VERSION ""

NS_ :

BS_:

BU_: ZCUR HDBI HDBM CID ZCUF ZCUT HDBT HDBA ZCUL

BO_ 656 ZCUR_VB1_2: 32 ZCUR
 SG_ ZCUR_FHVACBypassMotor_Err : 114|2@1+ (1,0) [0|3] ""  HDBM
 SG_ ZCUR_FHVACDefrostMotor_Err : 122|2@1+ (1,0) [0|3] ""  HDBM
 SG_ ZCUR_FHVACBLW_Err : 119|1@1+ (1,0) [0|1] ""  HDBM
 SG_ ZCUR_FHVACModePos_Rsp : 0|10@1+ (1,0) [0|1000] ""  HDBM
 SG_ ZCUR_FHVACCyclePos_Rsp : 10|10@1+ (1,0) [0|1000] ""  HDBM
 SG_ ZCUR_FHVACBypassPos_Rsp : 20|10@1+ (1,0) [0|1000] ""  HDBM
 SG_ ZCUR_FHVACDefrostPos_Rsp : 30|10@1+ (1,0) [0|1000] ""  HDBM
 SG_ ZCUR_FHVACBLWPWM_Rsp : 40|10@1+ (1,0) [0|1000] "千分比"  HDBM
 SG_ ZCUR_FHVACBLWRelay_St : 126|1@1+ (1,0) [0|1] ""  HDBM
 SG_ ZCUR_FHVACLeftMixPos_Rsp : 50|10@1+ (1,0) [0|1000] ""  HDBM
 SG_ ZCUR_FHVACRigtMixPos_Rsp : 60|10@1+ (1,0) [0|1000] ""  HDBM
 SG_ ZCUR_FHVACLeftMixMotor_Err : 120|2@1+ (1,0) [0|3] ""  HDBM
 SG_ ZCUR_FHVACModeMotor_Err : 112|2@1+ (1,0) [0|3] ""  HDBM
 SG_ ZCUR_FHVACCycleMotor_Err : 124|2@1+ (1,0) [0|3] ""  HDBM
 SG_ ZCUR_FHVACBLWRelay_Err : 118|1@1+ (1,0) [0|1] ""  HDBM
 SG_ ZCUR_FHVACRigtMixMotor_Err : 116|2@1+ (1,0) [0|3] ""  HDBM

BO_ 657 ZCUR_VB1_3: 32 ZCUR
 SG_ ZCUR_TDuctRVValid_St : 144|1@1+ (1,0) [0|1] ""  HDBM
 SG_ ZCUR_TDuctLFValid_St : 145|1@1+ (1,0) [0|1] ""  HDBM
 SG_ ZCUR_TDuctRFValid_St : 146|1@1+ (1,0) [0|1] ""  HDBM
 SG_ ZCUR_ADSTws_Val : 32|12@1+ (0.1,-40) [-40|80] "℃"  HDBM
 SG_ ZCUR_ION_St : 162|2@1+ (1,0) [0|3] ""  HDBM
 SG_ ZCUR_ADSTrh_Val : 44|12@1+ (0.1,-40) [-40|80] "℃"  HDBM
 SG_ ZCUR_ADShumidity_Val : 56|12@1+ (0.1,0) [0|100] "%"  HDBM
 SG_ ZCUR_TcabOrig_Val : 68|12@1+ (0.1,-40) [-40|80] "℃"  HDBM
 SG_ ZCUR_TEvapOrig_Val : 80|12@1+ (0.1,-40) [-40|80] "℃"  HDBM
 SG_ ZCUR_TDuctLV_Val : 92|12@1+ (0.1,-40) [-40|80] "℃"  HDBM
 SG_ ZCUR_TDuctRV_Val : 104|12@1+ (0.1,-40) [-40|80] "℃"  HDBM
 SG_ ZCUR_TDuctLF_Val : 116|12@1+ (0.1,-40) [-40|80] "℃"  HDBM
 SG_ ZCUR_TDuctRF_Val : 128|12@1+ (0.1,-40) [-40|80] "℃"  HDBM
 SG_ ZCUR_ADS_Valid_St : 147|1@1+ (1,0) [0|1] ""  HDBM
 SG_ ZCUR_TcabOrigValid_St : 148|1@1+ (1,0) [0|1] ""  HDBM
 SG_ ZCUR_TEvapOrigValid_St : 149|1@1+ (1,0) [0|1] ""  HDBM
 SG_ ZCUR_TDuctLVValid_St : 150|1@1+ (1,0) [0|1] ""  HDBM
 SG_ ZCUR_ION_Err : 151|1@1+ (1,0) [0|1] ""  HDBM
 SG_ ZCUR_PM25Sensor_Err : 143|1@1+ (1,0) [0|1] ""  HDBM
 SG_ ZCUR_CmpmtInAirPmDnsty_Val : 152|10@1+ (1,0) [0|1023] ""  HDBM
 SG_ ZCUR_CmpmtInAirPmAQI_St : 140|3@1+ (1,0) [0|7] ""  HDBM

BO_ 912 ZCUR_VB1_4: 32 ZCUR
 SG_ ZCUR_RRHdl_Err : 40|3@1+ (1,0) [0|7] ""  HDBM
 SG_ ZCUR_FRHdlWork_St : 32|2@1+ (1,0) [0|3] ""  HDBM
 SG_ ZCUR_RRHdlWork_St : 34|2@1+ (1,0) [0|3] ""  HDBM
 SG_ ZCUR_FRHdl_Err : 36|3@1+ (1,0) [0|7] ""  HDBM
 SG_ ZCUR_FRSeatHt_Rsp : 0|5@1+ (5,0) [0|100] "%"  HDBM
 SG_ ZCUR_FRSeatHtStpRsn_St : 24|4@1+ (1,0) [0|15] ""  HDBM
 SG_ ZCUR_FRSeatVtlt_Rsp : 8|5@1+ (5,0) [0|100] "%"  HDBM
 SG_ ZCUR_FRSeatVtltStpRsn_St : 28|4@1+ (1,0) [0|15] ""  HDBM
 SG_ ZCUR_RExMirHt_Rsp : 16|5@1+ (5,0) [0|100] "%"  HDBM
 SG_ ZCUR_RExMirHtStpRsn_St : 43|4@1+ (1,0) [0|15] ""  HDBM

BO_ 1472 ZCUR_VB1_5: 32 ZCUR
 SG_ ZCUR_HSDLVPower_Err : 24|48@1+ (1,0) [0|0] ""  HDBM
 SG_ ZCUR_HSDLVPower_St : 72|48@1+ (1,0) [0|0] ""  HDBM
 SG_ ZCUR_PERMLVPower_Err : 120|16@1+ (1,0) [0|65535] ""  HDBM
 SG_ ZCUR_PERMLVPower_St : 136|16@1+ (1,0) [0|65535] ""  HDBM
 SG_ ZCUR_FRSeatHgtAdjLn_St : 202|1@1+ (1,0) [0|1] ""  HDBM
 SG_ ZCUR_FRSeatCshnAngAdjLn_St : 203|1@1+ (1,0) [0|1] ""  HDBM
 SG_ ZCUR_FRLegAngCshnExtLn_St : 204|1@1+ (1,0) [0|1] ""  HDBM
 SG_ ZCUR_FRWinStpRsn_St : 208|4@1+ (1,0) [0|15] ""  HDBM
 SG_ ZCUR_RRWinStpRsn_St : 212|4@1+ (1,0) [0|15] ""  HDBM
 SG_ ZCUR_FRWinStp_Req : 216|3@1+ (1,0) [0|7] ""  HDBM
 SG_ ZCUR_RRWinStp_Req : 219|3@1+ (1,0) [0|7] ""  HDBM
 SG_ ZCUR_FRHdlFrzLn_Val : 168|8@1+ (1,0) [0|255] ""  HDBM
 SG_ ZCUR_RRHdlFrzLn_Val : 176|8@1+ (1,0) [0|255] ""  HDBM
 SG_ ZCUR_FRHdlFrzLnTime_Val : 184|8@1+ (0.1,0) [0|25.5] ""  HDBM
 SG_ ZCUR_RRHdlFrzLnTime_Val : 192|8@1+ (0.1,0) [0|25.5] ""  HDBM
 SG_ ZCUR_FRSeatFBAdjLn_St : 200|1@1+ (1,0) [0|1] ""  HDBM
 SG_ ZCUR_FRSeatBackrestAdjLn_St : 201|1@1+ (1,0) [0|1] ""  HDBM

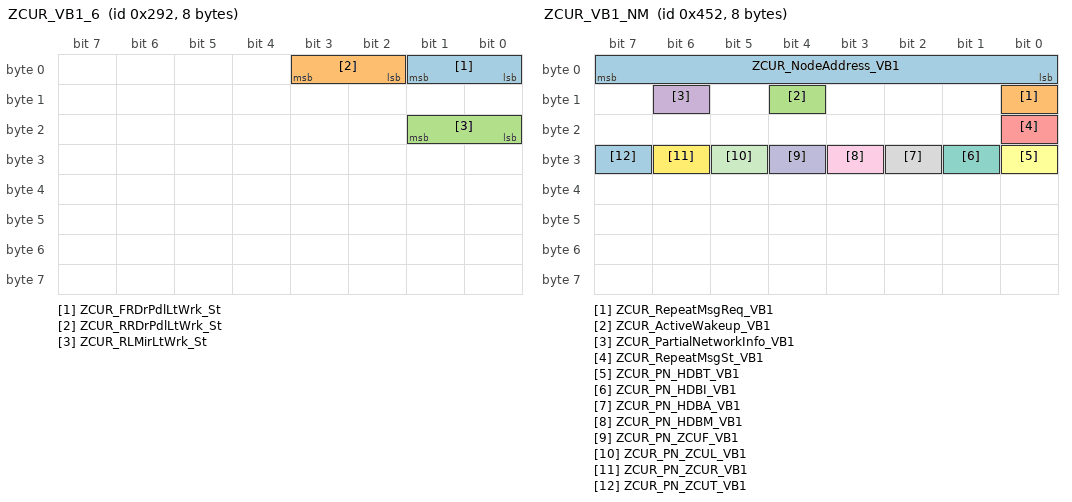
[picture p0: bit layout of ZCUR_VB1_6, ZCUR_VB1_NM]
BO_ 658 ZCUR_VB1_6: 8 ZCUR
 SG_ ZCUR_FRDrPdlLtWrk_St : 0|2@1+ (1,0) [0|3] ""  HDBM
 SG_ ZCUR_RRDrPdlLtWrk_St : 2|2@1+ (1,0) [0|3] ""  HDBM
 SG_ ZCUR_RLMirLtWrk_St : 16|2@1+ (1,0) [0|3] ""  HDBM

BO_ 1106 ZCUR_VB1_NM: 8 ZCUR
 SG_ ZCUR_NodeAddress_VB1 : 0|8@1+ (1,0) [0|255] ""  ZCUT,HDBI,ZCUF,HDBM,ZCUL,HDBA,HDBT,CID
 SG_ ZCUR_RepeatMsgReq_VB1 : 8|1@1+ (1,0) [0|1] ""  ZCUT,HDBI,ZCUF,HDBM,ZCUL,HDBA,HDBT
 SG_ ZCUR_ActiveWakeup_VB1 : 12|1@1+ (1,0) [0|1] ""  ZCUT,HDBI,ZCUF,HDBM,ZCUL,HDBA,HDBT
 SG_ ZCUR_PartialNetworkInfo_VB1 : 14|1@1+ (1,0) [0|1] ""  ZCUT,HDBI,ZCUF,HDBM,ZCUL,HDBA,HDBT
 SG_ ZCUR_RepeatMsgSt_VB1 : 16|1@1+ (1,0) [0|1] ""  ZCUT,HDBI,ZCUF,HDBM,ZCUL,HDBA,HDBT
 SG_ ZCUR_PN_HDBT_VB1 : 24|1@1+ (1,0) [0|1] ""  ZCUT,HDBI,ZCUF,HDBM,ZCUL,HDBA,HDBT
 SG_ ZCUR_PN_HDBI_VB1 : 25|1@1+ (1,0) [0|1] ""  ZCUT,HDBI,ZCUF,HDBM,ZCUL,HDBA,HDBT
 SG_ ZCUR_PN_HDBA_VB1 : 26|1@1+ (1,0) [0|1] ""  ZCUT,HDBI,ZCUF,HDBM,ZCUL,HDBA,HDBT
 SG_ ZCUR_PN_HDBM_VB1 : 27|1@1+ (1,0) [0|1] ""  ZCUT,HDBI,ZCUF,HDBM,ZCUL,HDBA,HDBT
 SG_ ZCUR_PN_ZCUF_VB1 : 28|1@1+ (1,0) [0|1] ""  ZCUT,HDBI,ZCUF,HDBM,ZCUL,HDBA,HDBT
 SG_ ZCUR_PN_ZCUL_VB1 : 29|1@1+ (1,0) [0|1] ""  ZCUT,HDBI,ZCUF,HDBM,ZCUL,HDBA,HDBT
 SG_ ZCUR_PN_ZCUR_VB1 : 30|1@1+ (1,0) [0|1] ""  ZCUT,HDBI,ZCUF,HDBM,ZCUL,HDBA,HDBT
 SG_ ZCUR_PN_ZCUT_VB1 : 31|1@1+ (1,0) [0|1] ""  ZCUT,HDBI,ZCUF,HDBM,ZCUL,HDBA,HDBT

BO_ 1414 ZCUR_NMWakeup: 32 ZCUR
 SG_ ZCUR_WakeupReq_HDBT : 0|1@1+ (1,0) [0|1] ""  HDBM,HDBT
 SG_ ZCUR_WakeupReq_HDBI : 8|8@1+ (1,0) [0|255] ""  HDBI,HDBM
 SG_ ZCUR_WakeupReq_HDBA : 16|8@1+ (1,0) [0|255] ""  HDBM,HDBA
 SG_ ZCUR_WakeupReq_HDBM : 24|8@1+ (1,0) [0|255] ""  HDBM
 SG_ ZCUR_WakeupReq_ZCUF : 32|56@1+ (1,0) [0|0] ""  ZCUF,HDBM
 SG_ ZCUR_WakeupReq_ZCUL : 88|56@1+ (1,0) [0|0] ""  HDBM,ZCUL
 SG_ ZCUR_WakeupReq_ZCUR : 144|56@1+ (1,0) [0|0] ""  HDBM
 SG_ ZCUR_WakeupReq_ZCUT : 200|56@1+ (1,0) [0|0] ""  ZCUT,HDBM

BO_ 1495 ZCUR_VB1_NMIndication: 32 ZCUR
 SG_ ZCUR_VB1_NetworkReqCondition0 : 0|8@1+ (1,0) [0|255] ""  HDBM
 SG_ ZCUR_VB1_NetworkReqCondition1 : 8|8@1+ (1,0) [0|255] ""  HDBM
 SG_ ZCUR_VB1_NetworkReqCondition2 : 16|8@1+ (1,0) [0|255] ""  HDBM
 SG_ ZCUR_VB1_NetworkReqCondition3 : 24|8@1+ (1,0) [0|255] ""  HDBM
 SG_ ZCUR_VB1_NetworkReqCondition4 : 32|8@1+ (1,0) [0|255] ""  HDBM
 SG_ ZCUR_VB1_NetworkReqCondition5 : 40|8@1+ (1,0) [0|255] ""  HDBM
 SG_ ZCUR_VB1_NetworkReqCondition6 : 48|8@1+ (1,0) [0|255] ""  HDBM
 SG_ ZCUR_VB1_NetworkReqCondition7 : 56|8@1+ (1,0) [0|255] ""  HDBM
 SG_ ZCUR_VB1_NetworkReqCondition8 : 64|8@1+ (1,0) [0|255] ""  HDBM
 SG_ ZCUR_VB1_NetworkReqCondition9 : 72|8@1+ (1,0) [0|255] ""  HDBM
 SG_ ZCUR_VB1_NetworkReqCondition10 : 80|8@1+ (1,0) [0|255] ""  HDBM
 SG_ ZCUR_VB1_NetworkReqCondition11 : 88|8@1+ (1,0) [0|255] ""  HDBM
 SG_ ZCUR_VB1_NetworkReqCondition12 : 96|8@1+ (1,0) [0|255] ""  HDBM
 SG_ ZCUR_VB1_NetworkReqCondition13 : 104|8@1+ (1,0) [0|255] ""  HDBM
 SG_ ZCUR_VB1_NetworkReqCondition14 : 112|8@1+ (1,0) [0|255] ""  HDBM
 SG_ ZCUR_VB1_NetworkReqCondition15 : 120|8@1+ (1,0) [0|255] ""  HDBM
 SG_ ZCUR_VB1_NetworkReqCondition16 : 128|8@1+ (1,0) [0|255] ""  HDBM
 SG_ ZCUR_VB1_NetworkReqCondition17 : 136|8@1+ (1,0) [0|255] ""  HDBM
 SG_ ZCUR_VB1_NetworkReqCondition18 : 144|8@1+ (1,0) [0|255] ""  HDBM
 SG_ ZCUR_VB1_NetworkReqCondition19 : 152|8@1+ (1,0) [0|255] ""  HDBM
 SG_ ZCUR_VB1_NetworkReqCondition20 : 160|8@1+ (1,0) [0|255] ""  HDBM
 SG_ ZCUR_VB1_NetworkReqCondition21 : 168|8@1+ (1,0) [0|255] ""  HDBM
 SG_ ZCUR_VB1_NetworkReqCondition22 : 176|8@1+ (1,0) [0|255] ""  HDBM
 SG_ ZCUR_VB1_NetworkReqCondition23 : 184|8@1+ (1,0) [0|255] ""  HDBM
 SG_ ZCUR_VB1_NetworkReqCondition24 : 192|8@1+ (1,0) [0|255] ""  HDBM
 SG_ ZCUR_VB1_NetworkReqCondition25 : 200|8@1+ (1,0) [0|255] ""  HDBM
 SG_ ZCUR_VB1_NetworkReqCondition26 : 208|8@1+ (1,0) [0|255] ""  HDBM
 SG_ ZCUR_VB1_NetworkReqCondition27 : 216|8@1+ (1,0) [0|255] ""  HDBM
 SG_ ZCUR_VB1_NetworkReqCondition28 : 224|8@1+ (1,0) [0|255] ""  HDBM
 SG_ ZCUR_VB1_NetworkReqCondition29 : 232|8@1+ (1,0) [0|255] ""  HDBM
 SG_ ZCUR_VB1_NetworkReqCondition30 : 240|8@1+ (1,0) [0|255] ""  HDBM
 SG_ ZCUR_VB1_NetworkReqCondition31 : 248|8@1+ (1,0) [0|255] ""  HDBM

BO_ 431 ZCUR_VB1_8: 32 ZCUR
 SG_ ZCUR_FRSeatCshnAngPst_Val : 40|7@1+ (1,0) [0|100] ""  HDBM
 SG_ ZCUR_FRLegAngCshnExtPst_Val : 48|7@1+ (1,0) [0|100] ""  HDBM
 SG_ ZCUR_FRSeatFBPst_Val : 16|7@1+ (1,0) [0|100] ""  HDBM
 SG_ ZCUR_FRSeatBackrestPst_Val : 24|7@1+ (1,0) [0|100] ""  HDBM
 SG_ ZCUR_FRSeatHgtPst_Val : 32|7@1+ (1,0) [0|100] ""  HDBM
 SG_ ZCUR_RExMirUDPst_Val : 56|7@1+ (1,0) [0|100] ""  HDBM
 SG_ ZCUR_RExMirLRPst_Val : 64|7@1+ (1,0) [0|100] ""  HDBM

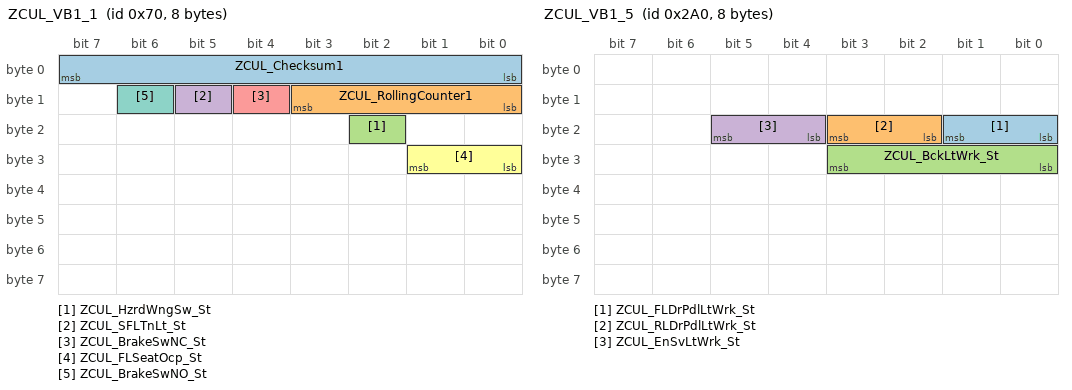
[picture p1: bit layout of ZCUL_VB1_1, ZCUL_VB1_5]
BO_ 112 ZCUL_VB1_1: 8 ZCUL
 SG_ ZCUL_Checksum1 : 0|8@1+ (1,0) [0|255] ""  HDBM,HDBA
 SG_ ZCUL_RollingCounter1 : 8|4@1+ (1,0) [0|15] ""  HDBM,HDBA
 SG_ ZCUL_HzrdWngSw_St : 18|1@1+ (1,0) [0|1] ""  ZCUF,HDBM
 SG_ ZCUL_SFLTnLt_St : 13|1@1+ (1,0) [0|1] ""  HDBM
 SG_ ZCUL_BrakeSwNC_St : 12|1@1+ (1,0) [0|1] ""  HDBM
 SG_ ZCUL_FLSeatOcp_St : 24|2@1+ (1,0) [0|3] ""  ZCUF,HDBM,HDBA
 SG_ ZCUL_BrakeSwNO_St : 14|1@1+ (1,0) [0|1] ""  HDBM

BO_ 400 ZCUL_VB1_2: 32 ZCUL
 SG_ ZCUL_FLSeatHgtAdj_Req : 24|2@1+ (1,0) [0|3] ""  HDBM
 SG_ ZCUL_FLLthPawl_St : 16|1@1+ (1,0) [0|1] ""  HDBM
 SG_ ZCUL_FLSeatCshnAngAdj_Req : 30|2@1+ (1,0) [0|3] ""  HDBM
 SG_ ZCUL_RLLthPawl_St : 36|1@1+ (1,0) [0|1] ""  HDBM
 SG_ ZCUL_FLHdlOprt_St : 17|2@1+ (1,0) [0|3] ""  HDBM
 SG_ ZCUL_RLHdlOprt_St : 19|2@1+ (1,0) [0|3] ""  HDBM
 SG_ ZCUL_FLDrIntSW_St : 12|2@1+ (1,0) [0|3] ""  HDBM
 SG_ ZCUL_RLDrIntSW_St : 32|2@1+ (1,0) [0|3] ""  HDBM
 SG_ ZCUL_FLLthAjar_St : 14|1@1+ (1,0) [0|1] ""  HDBM
 SG_ ZCUL_RLLthAjar_St : 34|1@1+ (1,0) [0|1] ""  HDBM
 SG_ ZCUL_FLSeatAdj_Req : 28|2@1+ (1,0) [0|3] ""  HDBM
 SG_ ZCUL_FLLthHlfLck_St : 15|1@1+ (1,0) [0|1] ""  HDBM
 SG_ ZCUL_FLSeatBackrestAdj_Req : 26|2@1+ (1,0) [0|3] ""  HDBM
 SG_ ZCUL_RLLthHlfLck_St : 35|1@1+ (1,0) [0|1] ""  HDBM
 SG_ ZCUL_Checksum2 : 0|8@1+ (1,0) [0|255] ""  HDBM
 SG_ ZCUL_RollingCounter2 : 8|4@1+ (1,0) [0|15] ""  HDBM
 SG_ ZCUL_FLSeatLegAngCshnExtAdj_Req : 40|2@1+ (1,0) [0|3] ""  HDBM
 SG_ ZCUL_SteerTiltPst_Val : 72|8@1+ (0.5,0) [0|100] ""  HDBM
 SG_ ZCUL_SteerTelePst_Val : 80|8@1+ (0.5,0) [0|100] ""  HDBM
 SG_ ZCUL_FLWinPst_Rsp : 88|8@1+ (1,0) [0|255] ""  HDBM
 SG_ ZCUL_RLWinPst_Rsp : 96|8@1+ (1,0) [0|255] ""  HDBM
 SG_ ZCUL_LExMirUDPst_Val : 104|7@1+ (1,0) [0|100] ""  HDBM
 SG_ ZCUL_LExMirLRPst_Val : 112|7@1+ (1,0) [0|100] ""  HDBM
 SG_ ZCUL_FLSeatFBPst_Val : 120|7@1+ (1,0) [0|100] ""  HDBM
 SG_ ZCUL_FLSeatBackrestPst_Val : 128|7@1+ (1,0) [0|100] ""  HDBM
 SG_ ZCUL_FLSeatHgtPst_Val : 136|7@1+ (1,0) [0|100] ""  HDBM
 SG_ ZCUL_FLSeatCshnAngPst_Val : 144|7@1+ (1,0) [0|100] ""  HDBM
 SG_ ZCUL_FLLegAngCshnExtPst_Val : 152|7@1+ (1,0) [0|100] ""  HDBM

BO_ 896 ZCUL_VB1_3: 32 ZCUL
 SG_ ZCUL_FLHdl_Err : 36|3@1+ (1,0) [0|7] ""  HDBM
 SG_ ZCUL_FLHdlWork_St : 32|2@1+ (1,0) [0|3] ""  HDBM
 SG_ ZCUL_RLHdlWork_St : 34|2@1+ (1,0) [0|3] ""  HDBM
 SG_ ZCUL_RLHdl_Err : 40|3@1+ (1,0) [0|7] ""  HDBM
 SG_ ZCUL_SteerTeleLn_St : 43|1@1+ (1,0) [0|1] ""  HDBM
 SG_ ZCUL_SteerTiltLn_St : 44|1@1+ (1,0) [0|1] ""  HDBM
 SG_ ZCUL_SteerHtStpRsn_St : 48|4@1+ (1,0) [0|15] ""  HDBM
 SG_ ZCUL_SteerHt_Rsp : 0|5@1+ (5,0) [0|100] "%"  HDBM
 SG_ ZCUL_FLSeatHtStpRsn_St : 56|4@1+ (1,0) [0|15] ""  HDBM
 SG_ ZCUL_FLSeatVtlt_Rsp : 24|5@1+ (5,0) [0|100] "%"  HDBM
 SG_ ZCUL_FLSeatVtltStpRsn_St : 60|4@1+ (1,0) [0|15] ""  HDBM
 SG_ ZCUL_LExMirHt_Rsp : 8|5@1+ (5,0) [0|100] "%"  HDBM
 SG_ ZCUL_LExMirHtStpRsn_St : 52|4@1+ (1,0) [0|15] ""  HDBM
 SG_ ZCUL_FLSeatHt_Rsp : 16|5@1+ (5,0) [0|100] "%"  HDBM

BO_ 1408 ZCUL_VB1_4: 32 ZCUL
 SG_ ZCUL_PERMLVPower_Err : 120|16@1+ (1,0) [0|65535] ""  HDBM
 SG_ ZCUL_HSDLVPower_St : 72|48@1+ (1,0) [0|0] ""  HDBM
 SG_ ZCUL_HSDLVPower_Err : 24|48@1+ (1,0) [0|0] ""  HDBM
 SG_ ZCUL_PERMLVPower_St : 136|16@1+ (1,0) [0|65535] ""  HDBM
 SG_ ZCUL_FLHdlFrzLn_Val : 168|8@1+ (1,0) [0|255] ""  HDBM
 SG_ ZCUL_RLHdlFrzLn_Val : 176|8@1+ (1,0) [0|255] ""  HDBM
 SG_ ZCUL_FLHdlFrzLnTime_Val : 184|8@1+ (0.1,0) [0|25.5] ""  HDBM
 SG_ ZCUL_RLHdlFrzLnTime_Val : 192|8@1+ (0.1,0) [0|25.5] ""  HDBM
 SG_ ZCUL_FLSeatFBAdjLn_St : 200|1@1+ (1,0) [0|1] ""  HDBM
 SG_ ZCUL_FLSeatBackrestAdjLn_St : 201|1@1+ (1,0) [0|1] ""  HDBM
 SG_ ZCUL_FLSeatHgtAdjLn_St : 202|1@1+ (1,0) [0|1] ""  HDBM
 SG_ ZCUL_FLSeatCshnAngAdjLn_St : 203|1@1+ (1,0) [0|1] ""  HDBM
 SG_ ZCUL_FLLegAngCshnExtLn_St : 204|1@1+ (1,0) [0|1] ""  HDBM
 SG_ ZCUL_FLWinStpRsn_St : 208|4@1+ (1,0) [0|15] ""  HDBM
 SG_ ZCUL_RLWinStpRsn_St : 212|4@1+ (1,0) [0|15] ""  HDBM
 SG_ ZCUL_FLWinStp_Req : 216|3@1+ (1,0) [0|7] ""  HDBM
 SG_ ZCUL_RLWinStp_Req : 219|3@1+ (1,0) [0|7] ""  HDBM

BO_ 672 ZCUL_VB1_5: 8 ZCUL
 SG_ ZCUL_FLDrPdlLtWrk_St : 16|2@1+ (1,0) [0|3] ""  HDBM
 SG_ ZCUL_RLDrPdlLtWrk_St : 18|2@1+ (1,0) [0|3] ""  HDBM
 SG_ ZCUL_BckLtWrk_St : 24|4@1+ (1,0) [0|15] ""  HDBM
 SG_ ZCUL_EnSvLtWrk_St : 20|2@1+ (1,0) [0|3] ""  HDBM

BO_ 673 ZCUL_VB1_6: 32 ZCUL
 SG_ ZCUL_RLWinSw_St : 58|3@1+ (1,0) [0|7] ""  HDBM
 SG_ ZCUL_FLWdwMov_St : 24|2@1+ (1,0) [0|3] ""  HDBM
 SG_ ZCUL_RLHdlFrz_St : 49|1@1+ (1,0) [0|1] ""  HDBM
 SG_ ZCUL_RLWdwMov_St : 56|2@1+ (1,0) [0|3] ""  HDBM
 SG_ ZCUL_FLLthHome_St : 23|1@1+ (1,0) [0|1] ""  HDBM
 SG_ ZCUL_RLLthHome_St : 55|1@1+ (1,0) [0|1] ""  HDBM
 SG_ ZCUL_FLDrLth_St : 0|3@1+ (1,0) [0|7] ""  HDBI,HDBM
 SG_ ZCUL_SFLTnLtErr_St : 47|1@1+ (1,0) [0|1] ""  HDBM
 SG_ ZCUL_FLHdlClsPstSW_St : 16|1@1+ (1,0) [0|1] ""  HDBM
 SG_ ZCUL_RLDrLth_St : 32|3@1+ (1,0) [0|7] ""  HDBI,HDBM
 SG_ ZCUL_FLDrLthWrk_St : 8|3@1+ (1,0) [0|7] ""  HDBM
 SG_ ZCUL_RLHdlClsPstSW_St : 48|1@1+ (1,0) [0|1] ""  HDBM
 SG_ ZCUL_FLHdlStpRsn_St : 19|4@1+ (1,0) [0|15] ""  HDBM
 SG_ ZCUL_FLHdlOpnPstSW_St : 18|1@1+ (1,0) [0|1] ""  HDBM
 SG_ ZCUL_RLDrLthWrk_St : 40|3@1+ (1,0) [0|7] ""  HDBM
 SG_ ZCUL_RLHdlStpRsn_St : 43|4@1+ (1,0) [0|15] ""  HDBM
 SG_ ZCUL_FLDrStpRsn_St : 11|4@1+ (1,0) [0|15] ""  HDBM
 SG_ ZCUL_RLHdlOpnPstSW_St : 50|1@1+ (1,0) [0|1] ""  HDBM
 SG_ ZCUL_RLDrStpRsn_St : 51|4@1+ (1,0) [0|15] ""  HDBM
 SG_ ZCUL_FLDrLth_Err : 3|3@1+ (1,0) [0|7] ""  HDBM
 SG_ ZCUL_RLDrLth_Err : 35|3@1+ (1,0) [0|7] ""  HDBM
 SG_ ZCUL_LExMirCtrl_Rsp : 72|1@1+ (1,0) [0|1] ""  HDBM
 SG_ ZCUL_HornSwitch_St : 64|1@1+ (1,0) [0|1] ""  HDBM
 SG_ ZCUL_FLHdlFrz_St : 17|1@1+ (1,0) [0|1] ""  HDBM
 SG_ ZCUL_FLDrStpRsn2_St : 65|4@1+ (1,0) [0|15] ""  HDBM
 SG_ ZCUL_FLDrLthWrk2_St : 69|3@1+ (1,0) [0|7] ""  HDBM
 SG_ ZCUL_RLDrStpRsn2_St : 73|4@1+ (1,0) [0|15] ""  HDBM
 SG_ ZCUL_RLDrLthWrk2_St : 77|3@1+ (1,0) [0|7] ""  HDBM
 SG_ ZCUL_FLLumbSuppUDAdj_Req : 88|2@1+ (1,0) [0|3] ""  HDBM
 SG_ ZCUL_FLSunshadeSW_St : 15|1@1+ (1,0) [0|1] ""  HDBM
 SG_ ZCUL_FLLumbSuppFBAdj_Req : 90|2@1+ (1,0) [0|3] ""  HDBM
 SG_ ZCUL_FLDrLth2_Err : 29|3@1+ (1,0) [0|7] ""  HDBM
 SG_ ZCUL_RLDrLth2_Err : 26|3@1+ (1,0) [0|7] ""  HDBM
 SG_ ZCUL_SteerTiltMv_St : 186|2@1+ (1,0) [0|3] ""  HDBM
 SG_ ZCUL_SteerTeleMv_St : 184|2@1+ (1,0) [0|3] ""  HDBM
 SG_ ZCUL_SteerTiltStpRsn_St : 148|4@1+ (1,0) [0|15] ""  HDBM
 SG_ ZCUL_SteerTiltStp_Req : 107|3@1+ (1,0) [0|7] ""  HDBM
 SG_ ZCUL_SteerTeleStpRsn_St : 144|4@1+ (1,0) [0|15] ""  HDBM
 SG_ ZCUL_SteerTeleStp_Req : 104|3@1+ (1,0) [0|7] ""  HDBM
 SG_ ZCUL_LExMirUDMv_St : 190|2@1+ (1,0) [0|3] ""  HDBM
 SG_ ZCUL_LExMirLRMv_St : 188|2@1+ (1,0) [0|3] ""  HDBM
 SG_ ZCUL_LExMirUDStpRsn_St : 156|4@1+ (1,0) [0|15] ""  HDBM
 SG_ ZCUL_LExMirUDStp_Req : 115|3@1+ (1,0) [0|7] ""  HDBM
 SG_ ZCUL_LExMirLRStpRsn_St : 152|4@1+ (1,0) [0|15] ""  HDBM
 SG_ ZCUL_LExMirLRStp_Req : 112|3@1+ (1,0) [0|7] ""  HDBM
 SG_ ZCUL_FLSeatCshnAngStpRsn_St : 176|4@1+ (1,0) [0|15] ""  HDBM
 SG_ ZCUL_FLSeatCshnAngStp_Req : 136|3@1+ (1,0) [0|7] ""  HDBM
 SG_ ZCUL_FLLegAngCshnExtStpRsn_St : 180|4@1+ (1,0) [0|15] ""  HDBM
 SG_ ZCUL_FLLegAngCshnExtStp_Req : 139|3@1+ (1,0) [0|7] ""  HDBM
 SG_ ZCUL_FLSeatFBMv_St : 194|2@1+ (1,0) [0|3] ""  HDBM
 SG_ ZCUL_FLSeatBackrestMv_St : 196|2@1+ (1,0) [0|3] ""  HDBM
 SG_ ZCUL_FLSeatHgtMv_St : 198|2@1+ (1,0) [0|3] ""  HDBM
 SG_ ZCUL_FLSeatCshnAngMv_St : 200|2@1+ (1,0) [0|3] ""  HDBM
 SG_ ZCUL_FLLegAngCshnExtMv_St : 202|2@1+ (1,0) [0|3] ""  HDBM
 SG_ ZCUL_FLSeatFBStpRsn_St : 164|4@1+ (1,0) [0|15] ""  HDBM
 SG_ ZCUL_FLSeatFBStp_Req : 123|3@1+ (1,0) [0|7] ""  HDBM
 SG_ ZCUL_FLSeatBackrestStpRsn_St : 168|4@1+ (1,0) [0|15] ""  HDBM
 SG_ ZCUL_FLSeatBackrestStp_Req : 128|3@1+ (1,0) [0|7] ""  HDBM
 SG_ ZCUL_FLSeatHgtStpRsn_St : 172|4@1+ (1,0) [0|15] ""  HDBM
 SG_ ZCUL_FLSeatHgtStp_Req : 131|3@1+ (1,0) [0|7] ""  HDBM
 SG_ ZCUL_FLHdlDbOprt_St : 80|2@1+ (1,0) [0|3] ""  HDBM
 SG_ ZCUL_RLHdlDbOprt_St : 82|2@1+ (1,0) [0|3] ""  HDBM
 SG_ ZCUL_LExMirCtrlMv_St : 192|2@1+ (1,0) [0|3] ""  HDBM
 SG_ ZCUL_LExMirCtrlStpRsn_St : 160|4@1+ (1,0) [0|15] ""  HDBM
 SG_ ZCUL_LExMirCtrlStp_Req : 120|3@1+ (1,0) [0|7] ""  HDBM

BO_ 401 ZCUL_FD_RT_1: 32 ZCUL
 SG_ SWSR_TouchPadDownSw_St : 25|1@1+ (1,0) [0|1] ""  HDBM
 SG_ SWSR_TouchPadLeftSw_St : 26|1@1+ (1,0) [0|1] ""  HDBM
 SG_ SWSR_TouchPadRightSw_St : 27|1@1+ (1,0) [0|1] ""  HDBM
 SG_ SWSR_TouchPadUpSw_St : 24|1@1+ (1,0) [0|1] ""  HDBM
 SG_ DISFL_FRWinCtl_Req : 32|3@1+ (1,0) [0|7] ""  HDBM
 SG_ DISFL_RLWinCtl_Req : 35|3@1+ (1,0) [0|7] ""  HDBM
 SG_ DISFL_RRWinCtl_Req : 40|3@1+ (1,0) [0|7] ""  HDBM
 SG_ DISFL_DrvCtLckSW_Req : 38|2@1+ (1,0) [0|3] ""  HDBM
 SG_ DISFL_FLWinCtl_Req : 43|3@1+ (1,0) [0|7] ""  HDBM
 SG_ TL_FLTpLtClr_St : 88|2@1+ (1,0) [0|3] ""  HDBM
 SG_ TL_RLTpLtClr_St : 92|2@1+ (1,0) [0|3] ""  HDBM
 SG_ TL_FRTpLtClr_St : 90|2@1+ (1,0) [0|3] ""  HDBM
 SG_ TL_RRTpLtClr_St : 94|2@1+ (1,0) [0|3] ""  HDBM
 SG_ TL_FLTchBtn_St : 80|1@1+ (1,0) [0|1] ""  HDBM
 SG_ TL_FLTpLtBrt_Val : 96|4@1+ (1,0) [0|15] ""  HDBM
 SG_ TL_RLTchBtn_St : 82|1@1+ (1,0) [0|1] ""  HDBM
 SG_ TL_RLTpLtBrt_Val : 104|4@1+ (1,0) [0|15] ""  HDBM
 SG_ TL_FRTchBtn_St : 81|1@1+ (1,0) [0|1] ""  HDBM
 SG_ TL_FRTpLtBrt_Val : 100|4@1+ (1,0) [0|15] ""  HDBM
 SG_ TL_RRTchBtn_St : 83|1@1+ (1,0) [0|1] ""  HDBM
 SG_ TL_RRTpLtBrt_Val : 108|4@1+ (1,0) [0|15] ""  HDBM
 SG_ ZCUL_FD_RT_1_SWSRAvailable_St : 120|2@1+ (1,0) [0|3] ""  HDBM
 SG_ ZCUL_FD_RT_1_DISFLAvailable_St : 122|2@1+ (1,0) [0|3] ""  HDBM
 SG_ ZCUL_FD_RT_1_TLAvailable_St : 124|2@1+ (1,0) [0|3] ""  HDBM

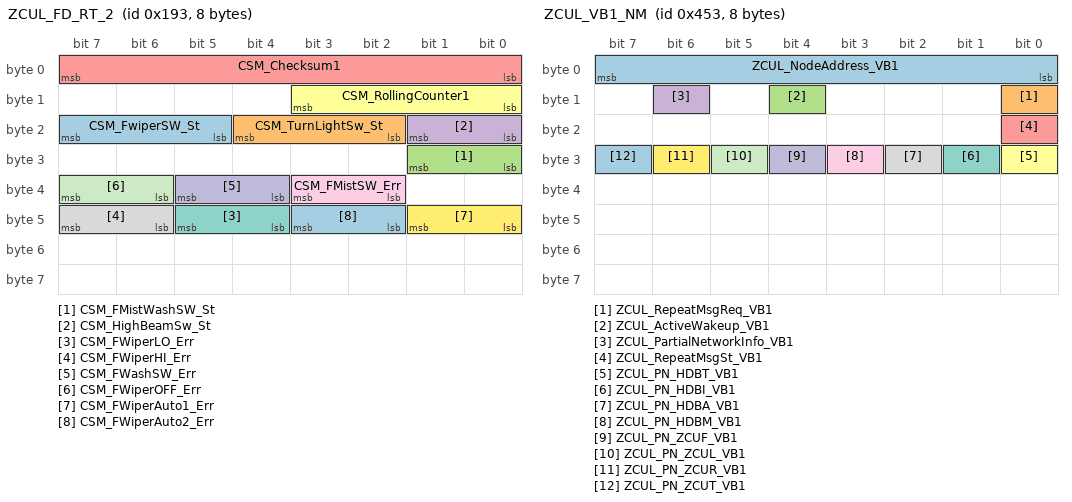
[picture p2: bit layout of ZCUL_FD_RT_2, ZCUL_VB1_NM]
BO_ 403 ZCUL_FD_RT_2: 8 ZCUL
 SG_ CSM_FwiperSW_St : 21|3@1+ (1,0) [0|7] ""  HDBM
 SG_ CSM_TurnLightSw_St : 18|3@1+ (1,0) [0|7] ""  HDBM
 SG_ CSM_FMistWashSW_St : 24|2@1+ (1,0) [0|3] ""  HDBM
 SG_ CSM_HighBeamSw_St : 16|2@1+ (1,0) [0|3] ""  HDBM
 SG_ CSM_Checksum1 : 0|8@1+ (1,0) [0|255] ""  HDBM
 SG_ CSM_RollingCounter1 : 8|4@1+ (1,0) [0|15] ""  HDBM
 SG_ CSM_FWiperLO_Err : 44|2@1+ (1,0) [0|3] ""  HDBM
 SG_ CSM_FWiperHI_Err : 46|2@1+ (1,0) [0|3] ""  HDBM
 SG_ CSM_FMistSW_Err : 34|2@1+ (1,0) [0|3] ""  HDBM
 SG_ CSM_FWashSW_Err : 36|2@1+ (1,0) [0|3] ""  HDBM
 SG_ CSM_FWiperOFF_Err : 38|2@1+ (1,0) [0|3] ""  HDBM
 SG_ CSM_FWiperAuto1_Err : 40|2@1+ (1,0) [0|3] ""  HDBM
 SG_ CSM_FWiperAuto2_Err : 42|2@1+ (1,0) [0|3] ""  HDBM

BO_ 1482 ZCUL_VB1_NMIndication: 32 ZCUL
 SG_ ZCUL_VB1_NetworkReqCondition0 : 0|8@1+ (1,0) [0|255] ""  HDBM
 SG_ ZCUL_VB1_NetworkReqCondition1 : 8|8@1+ (1,0) [0|255] ""  HDBM
 SG_ ZCUL_VB1_NetworkReqCondition2 : 16|8@1+ (1,0) [0|255] ""  HDBM
 SG_ ZCUL_VB1_NetworkReqCondition3 : 24|8@1+ (1,0) [0|255] ""  HDBM
 SG_ ZCUL_VB1_NetworkReqCondition4 : 32|8@1+ (1,0) [0|255] ""  HDBM
 SG_ ZCUL_VB1_NetworkReqCondition5 : 40|8@1+ (1,0) [0|255] ""  HDBM
 SG_ ZCUL_VB1_NetworkReqCondition6 : 48|8@1+ (1,0) [0|255] ""  HDBM
 SG_ ZCUL_VB1_NetworkReqCondition7 : 56|8@1+ (1,0) [0|255] ""  HDBM
 SG_ ZCUL_VB1_NetworkReqCondition8 : 64|8@1+ (1,0) [0|255] ""  HDBM
 SG_ ZCUL_VB1_NetworkReqCondition9 : 72|8@1+ (1,0) [0|255] ""  HDBM
 SG_ ZCUL_VB1_NetworkReqCondition10 : 80|8@1+ (1,0) [0|255] ""  HDBM
 SG_ ZCUL_VB1_NetworkReqCondition11 : 88|8@1+ (1,0) [0|255] ""  HDBM
 SG_ ZCUL_VB1_NetworkReqCondition12 : 96|8@1+ (1,0) [0|255] ""  HDBM
 SG_ ZCUL_VB1_NetworkReqCondition13 : 104|8@1+ (1,0) [0|255] ""  HDBM
 SG_ ZCUL_VB1_NetworkReqCondition14 : 112|8@1+ (1,0) [0|255] ""  HDBM
 SG_ ZCUL_VB1_NetworkReqCondition15 : 120|8@1+ (1,0) [0|255] ""  HDBM
 SG_ ZCUL_VB1_NetworkReqCondition16 : 128|8@1+ (1,0) [0|255] ""  HDBM
 SG_ ZCUL_VB1_NetworkReqCondition17 : 136|8@1+ (1,0) [0|255] ""  HDBM
 SG_ ZCUL_VB1_NetworkReqCondition18 : 144|8@1+ (1,0) [0|255] ""  HDBM
 SG_ ZCUL_VB1_NetworkReqCondition19 : 152|8@1+ (1,0) [0|255] ""  HDBM
 SG_ ZCUL_VB1_NetworkReqCondition20 : 160|8@1+ (1,0) [0|255] ""  HDBM
 SG_ ZCUL_VB1_NetworkReqCondition21 : 168|8@1+ (1,0) [0|255] ""  HDBM
 SG_ ZCUL_VB1_NetworkReqCondition22 : 176|8@1+ (1,0) [0|255] ""  HDBM
 SG_ ZCUL_VB1_NetworkReqCondition23 : 184|8@1+ (1,0) [0|255] ""  HDBM
 SG_ ZCUL_VB1_NetworkReqCondition24 : 192|8@1+ (1,0) [0|255] ""  HDBM
 SG_ ZCUL_VB1_NetworkReqCondition25 : 200|8@1+ (1,0) [0|255] ""  HDBM
 SG_ ZCUL_VB1_NetworkReqCondition26 : 208|8@1+ (1,0) [0|255] ""  HDBM
 SG_ ZCUL_VB1_NetworkReqCondition27 : 216|8@1+ (1,0) [0|255] ""  HDBM
 SG_ ZCUL_VB1_NetworkReqCondition28 : 224|8@1+ (1,0) [0|255] ""  HDBM
 SG_ ZCUL_VB1_NetworkReqCondition29 : 232|8@1+ (1,0) [0|255] ""  HDBM
 SG_ ZCUL_VB1_NetworkReqCondition30 : 240|8@1+ (1,0) [0|255] ""  HDBM
 SG_ ZCUL_VB1_NetworkReqCondition31 : 248|8@1+ (1,0) [0|255] ""  HDBM

BO_ 1415 ZCUL_NMWakeup: 32 ZCUL
 SG_ ZCUL_WakeupReq_HDBT : 0|1@1+ (1,0) [0|1] ""  HDBM,HDBT
 SG_ ZCUL_WakeupReq_HDBI : 8|8@1+ (1,0) [0|255] ""  HDBI,HDBM
 SG_ ZCUL_WakeupReq_HDBA : 16|8@1+ (1,0) [0|255] ""  HDBM,HDBA
 SG_ ZCUL_WakeupReq_HDBM : 24|8@1+ (1,0) [0|255] ""  HDBM
 SG_ ZCUL_WakeupReq_ZCUF : 32|56@1+ (1,0) [0|0] ""  ZCUF,HDBM
 SG_ ZCUL_WakeupReq_ZCUL : 88|56@1+ (1,0) [0|0] ""  HDBM
 SG_ ZCUL_WakeupReq_ZCUR : 144|56@1+ (1,0) [0|0] ""  HDBM,ZCUR
 SG_ ZCUL_WakeupReq_ZCUT : 200|56@1+ (1,0) [0|0] ""  ZCUT,HDBM

BO_ 1107 ZCUL_VB1_NM: 8 ZCUL
 SG_ ZCUL_NodeAddress_VB1 : 0|8@1+ (1,0) [0|255] ""  ZCUT,HDBI,ZCUF,HDBM,HDBA,ZCUR,HDBT
 SG_ ZCUL_RepeatMsgReq_VB1 : 8|1@1+ (1,0) [0|1] ""  ZCUT,HDBI,ZCUF,HDBM,HDBA,ZCUR,HDBT
 SG_ ZCUL_ActiveWakeup_VB1 : 12|1@1+ (1,0) [0|1] ""  ZCUT,HDBI,ZCUF,HDBM,HDBA,ZCUR,HDBT
 SG_ ZCUL_PartialNetworkInfo_VB1 : 14|1@1+ (1,0) [0|1] ""  ZCUT,HDBI,ZCUF,HDBM,HDBA,ZCUR,HDBT
 SG_ ZCUL_RepeatMsgSt_VB1 : 16|1@1+ (1,0) [0|1] ""  ZCUT,HDBI,ZCUF,HDBM,HDBA,ZCUR,HDBT
 SG_ ZCUL_PN_HDBT_VB1 : 24|1@1+ (1,0) [0|1] ""  ZCUT,HDBI,ZCUF,HDBM,HDBA,ZCUR,HDBT
 SG_ ZCUL_PN_HDBI_VB1 : 25|1@1+ (1,0) [0|1] ""  ZCUT,HDBI,ZCUF,HDBM,HDBA,ZCUR,HDBT
 SG_ ZCUL_PN_HDBA_VB1 : 26|1@1+ (1,0) [0|1] ""  ZCUT,HDBI,ZCUF,HDBM,HDBA,ZCUR,HDBT
 SG_ ZCUL_PN_HDBM_VB1 : 27|1@1+ (1,0) [0|1] ""  ZCUT,HDBI,ZCUF,HDBM,HDBA,ZCUR,HDBT
 SG_ ZCUL_PN_ZCUF_VB1 : 28|1@1+ (1,0) [0|1] ""  ZCUT,HDBI,ZCUF,HDBM,HDBA,ZCUR,HDBT
 SG_ ZCUL_PN_ZCUL_VB1 : 29|1@1+ (1,0) [0|1] ""  ZCUT,HDBI,ZCUF,HDBM,HDBA,ZCUR,HDBT
 SG_ ZCUL_PN_ZCUR_VB1 : 30|1@1+ (1,0) [0|1] ""  ZCUT,HDBI,ZCUF,HDBM,HDBA,ZCUR,HDBT
 SG_ ZCUL_PN_ZCUT_VB1 : 31|1@1+ (1,0) [0|1] ""  ZCUT,HDBI,ZCUF,HDBM,HDBA,ZCUR,HDBT

BO_ 320 ZCUF_VB1_2: 32 ZCUF
 SG_ ZCUF_RegenPwrPct_Val : 0|8@1+ (0.4,0) [0|100] "%"  HDBI,HDBM
 SG_ ZCUF_CurrActlDrvPwr_Val : 8|8@1+ (2,0) [0|500] "KW"  HDBI,HDBM
 SG_ ZCUF_FWiperParkAreaSW_St : 64|2@1+ (1,0) [0|3] ""  HDBM
 SG_ ZCUF_CurrActlBrakePwr_Val : 24|8@1+ (2,0) [0|500] "KW"  HDBI,HDBM
 SG_ ZCUF_CurrLimitDrivePwrPct_Val : 48|8@1+ (0.4,0) [0|100] "%"  HDBI,HDBM
 SG_ ZCUF_CurrLimitBrakePwrPct_Val : 56|8@1+ (0.4,0) [0|100] "%"  HDBI,HDBM

BO_ 528 ZCUF_VB1_3: 32 ZCUF
 SG_ ZCUF_ACTotLimPwr_Val : 184|10@1+ (100,0) [0|40000] "W"  HDBM
 SG_ ZCUF_ECFActualSpdPct_Val : 160|8@1+ (1,0) [0|100] ""  HDBM
 SG_ ZCUF_EcfFlt_St : 168|3@1+ (1,0) [0|3] ""  HDBM
 SG_ ZCUF_FLHighLgt_St : 120|1@1+ (1,0) [0|1] ""  HDBM
 SG_ ZCUF_FRHighLgt_St : 121|1@1+ (1,0) [0|1] ""  HDBM
 SG_ ZCUF_StdSenarioMileage_Val : 76|12@1+ (1,0) [0|4000] "Km"  HDBI,HDBM,HDBT
 SG_ ZCUF_RESSInletTargTemp_Req : 104|8@1+ (1,-40) [-40|100] "℃"  ZCUT,HDBM
 SG_ ZCUF_Ready_St : 128|1@1+ (1,0) [0|1] ""  HDBM,HDBA
 SG_ ZCUF_PackThmlMode_Req : 112|3@1+ (1,0) [0|7] ""  ZCUT,HDBM
 SG_ ZCUF_HighVoltage_St : 129|2@1+ (1,0) [0|3] ""  HDBM
 SG_ ZCUF_AGSFaultSt_Err : 214|1@1+ (1,0) [0|1] ""  HDBM
 SG_ ZCUF_AGSActAng_Val : 32|8@1+ (1,0) [0|255] ""  HDBM
 SG_ ZCUF_TractionModeSet_Rsp : 16|2@1+ (1,0) [0|3] ""  HDBI,HDBM
 SG_ ZCUF_FLTnLgtErr_St : 18|1@1+ (1,0) [0|1] ""  HDBM
 SG_ ZCUF_FRTnLgtErr_St : 19|1@1+ (1,0) [0|1] ""  HDBM
 SG_ ZCUF_Checksum5 : 0|8@1+ (1,0) [0|255] ""  HDBM
 SG_ ZCUF_RollingCounter5 : 8|4@1+ (1,0) [0|15] ""  HDBM
 SG_ ZCUF_CoolSysInletTemp_Val : 144|8@1+ (1,-40) [-40|120] "℃"  ZCUT,HDBM
 SG_ ZCUF_CoolSysOutletTemp_Val : 152|8@1+ (1,-40) [-40|120] "℃"  ZCUT,HDBM

BO_ 1424 ZCUF_VB1_4: 32 ZCUF
 SG_ ZCUF_HSDLVPower_St : 72|48@1+ (1,0) [0|0] ""  HDBM
 SG_ ZCUF_HSDLVPower_Err : 24|48@1+ (1,1) [0|0] ""  HDBM
 SG_ ZCUF_PERMLVPower_St : 120|16@1+ (1,0) [0|65535] ""  HDBM
 SG_ ZCUF_PERMLVPower_Err : 136|16@1+ (1,0) [0|65535] ""  HDBM
 SG_ ZCUF_AvgEnergyConsume_Val : 160|12@1+ (0.1,0) [0|409.5] "kWh/100km"  HDBM

BO_ 513 ZCUF_VB1_5: 32 ZCUF
 SG_ ZCUF_AbnormalShiftInfo_Err : 88|4@1+ (1,0) [0|15] ""  HDBI,HDBM
 SG_ ZCUF_ThmlRunawayWarn_St : 99|2@1+ (1,0) [0|1] ""  HDBI,HDBM
 SG_ ZCUF_Shift_Err : 84|3@1+ (1,0) [0|7] ""  HDBI,HDBM
 SG_ ZCUF_PullOver_St : 75|1@1+ (1,0) [0|1] ""  HDBI,HDBM
 SG_ ZCUF_BrakeLightOn_Req : 106|1@1+ (1,0) [0|1] ""  HDBM
 SG_ ZCUF_HVOffConfirm_Req : 105|1@1+ (1,0) [0|1] ""  HDBI,HDBM,CID
 SG_ ZCUF_PTFaultLgtClr_St : 80|2@1+ (1,0) [0|3] ""  HDBI,HDBM
 SG_ ZCUF_AntiTheft_St : 101|3@1+ (1,0) [0|7] ""  HDBI,HDBM
 SG_ ZCUF_LowVoltSys_Err : 87|1@1+ (1,0) [0|1] ""  HDBI,HDBM
 SG_ ZCUF_MotorOverTemp_St : 83|1@1+ (1,0) [0|1] ""  HDBI,HDBM
 SG_ ZCUF_PTHMI_Req : 128|32@1+ (1,0) [0|4294967295] ""  HDBI,HDBM
 SG_ ZCUF_EDCDisTemp_Val : 16|12@1+ (0.1,-40) [-40|160] "℃"  HDBM
 SG_ ZCUF_EDCSuncPres_Val : 40|16@1+ (1,0) [0|30000] "kpa"  HDBM
 SG_ ZCUF_EDCSuncTemp_Val : 28|12@1+ (0.1,-40) [-40|160] "℃"  HDBM
 SG_ ZCUF_EDCDisPres_Val : 0|16@1+ (1,0) [0|30000] "kpa"  HDBM
 SG_ ZCUF_TAmbOrig_Val : 56|12@1+ (0.1,-40) [-40|80] ""  HDBM
 SG_ ZCUF_EEMSetPowerLevel_St : 68|4@1+ (1,0) [0|15] ""  HDBM

BO_ 880 ZCUF_VB1_6: 32 ZCUF
 SG_ ZCUF_ACMEnable_Req : 80|1@1+ (1,0) [0|1] ""  HDBM
 SG_ ZCUF_FLLowLgt_St : 26|1@1+ (1,0) [0|1] ""  HDBM
 SG_ ZCUF_FRLowLgt_St : 27|1@1+ (1,0) [0|1] ""  HDBM
 SG_ ZCUF_HoodAjar_St : 73|1@1+ (1,0) [0|1] ""  HDBM
 SG_ ZCUF_DriveConflictRemindInfo_UI : 32|4@1+ (1,0) [0|15] ""  HDBI,HDBM
 SG_ ZCUF_FLPstnLgt_St : 24|1@1+ (1,0) [0|1] ""  HDBM
 SG_ ZCUF_FRPstnLgt_St : 25|1@1+ (1,1) [0|1] ""  HDBM
 SG_ ZCUF_PTworkmode_St : 16|4@1+ (1,0) [0|15] ""  HDBM
 SG_ ZCUF_PtModAvailable_St : 76|1@1+ (1,0) [0|1] ""  HDBM
 SG_ ZCUF_RegenSetPct_Rsp : 96|8@1+ (0.5,0) [0|100] "%"  HDBI,HDBM
 SG_ ZCUF_Fwiper_St : 40|3@1+ (1,0) [0|7] ""  HDBM
 SG_ ZCUF_ServiceReminder_St : 85|1@1+ (1,0) [0|1] ""  HDBI,HDBM
 SG_ ZCUF_HoodHalfOrPawl_St : 72|1@1+ (1,0) [0|1] ""  HDBM
 SG_ ZCUF_TractionModeAvail_St : 88|2@1+ (1,0) [0|3] ""  HDBI,HDBM
 SG_ ZCUF_TractionModeRemaind_St : 90|2@1+ (1,0) [0|3] ""  HDBI,HDBM
 SG_ ZCUF_FLDyLgt_St : 64|1@1+ (1,0) [0|1] ""  HDBM
 SG_ ZCUF_FRDyLgt_St : 66|1@1+ (1,0) [0|1] ""  HDBM
 SG_ ZCUF_LowBattChrgForbid_St : 65|1@1+ (1,0) [0|1] ""  HDBM
 SG_ ZCUF_PTThmlLiquidLackWarn_St : 20|2@1+ (1,0) [0|3] ""  HDBI,HDBM
 SG_ ZCUF_RegenAvail_St : 79|1@1+ (1,0) [0|1] ""  HDBI,HDBM
 SG_ ZCUF_LowVoltSysWarnStop_St : 22|1@1+ (1,0) [0|1] ""  HDBI,HDBM
 SG_ ZCUF_EmergencyLgtOn_Req : 23|1@1+ (1,0) [0|1] ""  HDBM
 SG_ ZCUF_HoodLatch_St : 81|2@1+ (1,0) [0|3] ""  HDBM
 SG_ ZCUF_WashLqdHgtSW_St : 67|1@1+ (1,0) [0|1] ""  HDBM

BO_ 97 ZCUF_FD_RT_1: 16 ZCUF
 SG_ EHBM_FLWhlPulse_Val : 56|8@1+ (1,0) [0|255] ""  HDBM,HDBA
 SG_ EHBM_FRWhlPulse_Val : 64|8@1+ (1,0) [0|255] ""  HDBM,HDBA
 SG_ EHBM_RLWhlPulse_Val : 72|8@1+ (1,0) [0|255] ""  HDBM,HDBA
 SG_ EHBM_RRWhlPulse_Val : 80|8@1+ (1,0) [0|255] ""  HDBM,HDBA
 SG_ EHBM_FLWhlPulseValid_St : 50|1@1+ (1,0) [0|1] ""  HDBM,HDBA
 SG_ EHBM_FRWhlPulseValid_St : 51|1@1+ (1,0) [0|1] ""  HDBM,HDBA
 SG_ EHBM_RLWhlPulseValid_St : 52|1@1+ (1,0) [0|1] ""  HDBM,HDBA
 SG_ EHBM_RRWhlPulseValid_St : 53|1@1+ (1,0) [0|1] ""  HDBM,HDBA
 SG_ ZCUF_FD_RT_1_EHBMAvailable_St : 54|2@1+ (1,0) [0|3] ""  HDBM

BO_ 448 ACCM_FCANFD1_1: 32 ZCUF
 SG_ ACCM_ZCUFMissing_St : 98|1@1+ (1,0) [0|1] ""  HDBM
 SG_ ACCM_VDC_Val : 18|10@1+ (1,0) [0|1000] "V"  HDBM
 SG_ ACCM_UvP_St : 85|1@1+ (1,0) [0|1] ""  HDBM
 SG_ ACCM_UnderHV_St : 87|1@1+ (1,0) [0|1] ""  HDBM
 SG_ ACCM_TempSensorError : 95|1@1+ (1,0) [0|1] ""  HDBM
 SG_ ACCM_St : 72|3@1+ (1,0) [0|7] ""  HDBM
 SG_ ACCM_Speed_Val : 42|14@1+ (1,0) [0|16000] "rpm"  HDBM
 SG_ ACCM_SIC_Err : 97|1@1+ (1,0) [0|1] ""  HDBM
 SG_ ACCM_Power_Val : 28|14@1+ (1,0) [0|16000] "W"  HDBM
 SG_ ACCM_PISaturation_St : 92|1@1+ (1,0) [0|1] ""  HDBM
 SG_ ACCM_PhaseCurrent_Val : 56|8@1+ (0.1,0) [0|25.5] "A"  HDBM
 SG_ ACCM_OvPd_St : 78|1@1+ (1,0) [0|1] ""  HDBM
 SG_ ACCM_OverPower_St : 94|1@1+ (1,0) [0|1] ""  HDBM
 SG_ ACCM_Overload_St : 93|1@1+ (1,0) [0|1] ""  HDBM
 SG_ ACCM_OverIPMTemp_St : 76|1@1+ (1,0) [0|1] ""  HDBM
 SG_ ACCM_OverHV_St : 86|1@1+ (1,0) [0|1] ""  HDBM
 SG_ ACCM_OverDuty_St : 75|1@1+ (1,0) [0|1] ""  HDBM
 SG_ ACCM_LvUv_St : 79|1@1+ (1,0) [0|1] ""  HDBM
 SG_ ACCM_LvOv_St : 77|1@1+ (1,0) [0|1] ""  HDBM
 SG_ ACCM_LoseStep_St : 82|1@1+ (1,0) [0|1] ""  HDBM
 SG_ ACCM_LackPhase_St : 80|1@1+ (1,0) [0|1] ""  HDBM
 SG_ ACCM_IPMTemperature_Val : 9|9@1+ (0.5,-50) [-50|200] "DegC"  HDBM
 SG_ ACCM_HVLoop_St : 83|2@1+ (1,0) [0|3] ""  HDBM
 SG_ ACCM_HardProtection_St : 91|1@1+ (1,0) [0|1] ""  HDBM
 SG_ ACCM_FreqLimitcode_Spec : 89|2@1+ (1,0) [0|3] ""  HDBM
 SG_ ACCM_DriveVoltageUV_St : 88|1@1+ (1,0) [0|1] ""  HDBM
 SG_ ACCM_DriveVoltageOV_St : 96|1@1+ (1,0) [0|1] ""  HDBM
 SG_ ACCM_DCCurrent_Val : 64|8@1+ (0.1,0) [0|25.5] "A"  HDBM
 SG_ ACCM_CSE_Err : 81|1@1+ (1,0) [0|1] ""  HDBM
 SG_ ACCM_ControllerTemp_Val : 0|9@1+ (0.5,-50) [-50|200] "DegC"  HDBM
 SG_ ACCM_Busoff_Err : 104|1@1+ (1,0) [0|1] ""  HDBM

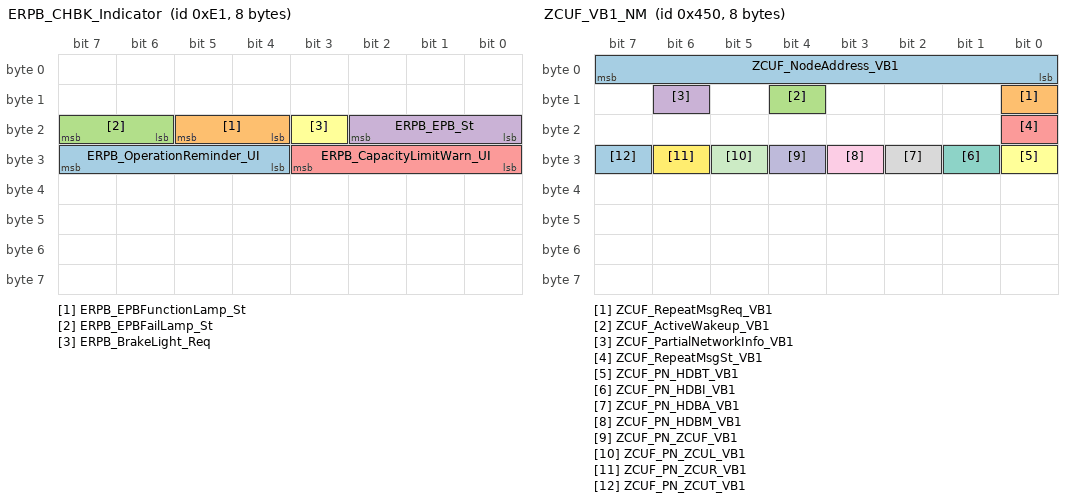
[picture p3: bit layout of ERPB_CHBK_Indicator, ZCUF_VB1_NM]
BO_ 225 ERPB_CHBK_Indicator: 8 ZCUF
 SG_ ERPB_OperationReminder_UI : 28|4@1+ (1,0) [0|15] ""  HDBI,HDBM
 SG_ ERPB_EPBFunctionLamp_St : 20|2@1+ (1,0) [0|3] ""  HDBI,HDBM
 SG_ ERPB_EPBFailLamp_St : 22|2@1+ (1,0) [0|3] ""  HDBI,HDBM
 SG_ ERPB_EPB_St : 16|3@1+ (1,0) [0|7] ""  HDBI,ZCUF,HDBM,HDBA,CID
 SG_ ERPB_CapacityLimitWarn_UI : 24|4@1+ (1,0) [0|15] ""  HDBI,HDBM
 SG_ ERPB_BrakeLight_Req : 19|1@1+ (1,0) [0|1] ""  HDBM

BO_ 1476 ZCUF_VB1_NMIndication: 32 ZCUF
 SG_ ZCUF_VB1_NetworkReqCondition0 : 0|8@1+ (1,0) [0|255] ""  HDBM
 SG_ ZCUF_VB1_NetworkReqCondition1 : 8|8@1+ (1,0) [0|255] ""  HDBM
 SG_ ZCUF_VB1_NetworkReqCondition2 : 16|8@1+ (1,0) [0|255] ""  HDBM
 SG_ ZCUF_VB1_NetworkReqCondition3 : 24|8@1+ (1,0) [0|255] ""  HDBM
 SG_ ZCUF_VB1_NetworkReqCondition4 : 32|8@1+ (1,0) [0|255] ""  HDBM
 SG_ ZCUF_VB1_NetworkReqCondition5 : 40|8@1+ (1,0) [0|255] ""  HDBM
 SG_ ZCUF_VB1_NetworkReqCondition6 : 48|8@1+ (1,0) [0|255] ""  HDBM
 SG_ ZCUF_VB1_NetworkReqCondition7 : 56|8@1+ (1,0) [0|255] ""  HDBM
 SG_ ZCUF_VB1_NetworkReqCondition8 : 64|8@1+ (1,0) [0|255] ""  HDBM
 SG_ ZCUF_VB1_NetworkReqCondition9 : 72|8@1+ (1,0) [0|255] ""  HDBM
 SG_ ZCUF_VB1_NetworkReqCondition10 : 80|8@1+ (1,0) [0|255] ""  HDBM
 SG_ ZCUF_VB1_NetworkReqCondition11 : 88|8@1+ (1,0) [0|255] ""  HDBM
 SG_ ZCUF_VB1_NetworkReqCondition12 : 96|8@1+ (1,0) [0|255] ""  HDBM
 SG_ ZCUF_VB1_NetworkReqCondition13 : 104|8@1+ (1,0) [0|255] ""  HDBM
 SG_ ZCUF_VB1_NetworkReqCondition14 : 112|8@1+ (1,0) [0|255] ""  HDBM
 SG_ ZCUF_VB1_NetworkReqCondition15 : 120|8@1+ (1,0) [0|255] ""  HDBM
 SG_ ZCUF_VB1_NetworkReqCondition16 : 128|8@1+ (1,0) [0|255] ""  HDBM
 SG_ ZCUF_VB1_NetworkReqCondition17 : 136|8@1+ (1,0) [0|255] ""  HDBM
 SG_ ZCUF_VB1_NetworkReqCondition18 : 144|8@1+ (1,0) [0|255] ""  HDBM
 SG_ ZCUF_VB1_NetworkReqCondition19 : 152|8@1+ (1,0) [0|255] ""  HDBM
 SG_ ZCUF_VB1_NetworkReqCondition20 : 160|8@1+ (1,0) [0|255] ""  HDBM
 SG_ ZCUF_VB1_NetworkReqCondition21 : 168|8@1+ (1,0) [0|255] ""  HDBM
 SG_ ZCUF_VB1_NetworkReqCondition22 : 176|8@1+ (1,0) [0|255] ""  HDBM
 SG_ ZCUF_VB1_NetworkReqCondition23 : 184|8@1+ (1,0) [0|255] ""  HDBM
 SG_ ZCUF_VB1_NetworkReqCondition24 : 192|8@1+ (1,0) [0|255] ""  HDBM
 SG_ ZCUF_VB1_NetworkReqCondition25 : 200|8@1+ (1,0) [0|255] ""  HDBM
 SG_ ZCUF_VB1_NetworkReqCondition26 : 208|8@1+ (1,0) [0|255] ""  HDBM
 SG_ ZCUF_VB1_NetworkReqCondition27 : 216|8@1+ (1,0) [0|255] ""  HDBM
 SG_ ZCUF_VB1_NetworkReqCondition28 : 224|8@1+ (1,0) [0|255] ""  HDBM
 SG_ ZCUF_VB1_NetworkReqCondition29 : 232|8@1+ (1,0) [0|255] ""  HDBM
 SG_ ZCUF_VB1_NetworkReqCondition30 : 240|8@1+ (1,0) [0|255] ""  HDBM
 SG_ ZCUF_VB1_NetworkReqCondition31 : 248|8@1+ (1,0) [0|255] ""  HDBM

BO_ 1412 ZCUF_NMWakeup: 32 ZCUF
 SG_ ZCUF_WakeupReq_HDBT : 0|1@1+ (1,0) [0|1] ""  HDBM,HDBT
 SG_ ZCUF_WakeupReq_HDBI : 8|8@1+ (1,0) [0|255] ""  HDBI,HDBM
 SG_ ZCUF_WakeupReq_HDBA : 16|8@1+ (1,0) [0|255] ""  HDBM,HDBA
 SG_ ZCUF_WakeupReq_HDBM : 24|8@1+ (1,0) [0|255] ""  HDBM
 SG_ ZCUF_WakeupReq_ZCUF : 32|56@1+ (1,0) [0|0] ""  HDBM
 SG_ ZCUF_WakeupReq_ZCUL : 88|56@1+ (1,0) [0|0] ""  HDBM,ZCUL
 SG_ ZCUF_WakeupReq_ZCUR : 144|56@1+ (1,0) [0|0] ""  HDBM,ZCUR
 SG_ ZCUF_WakeupReq_ZCUT : 200|56@1+ (1,0) [0|0] ""  ZCUT,HDBM

BO_ 1104 ZCUF_VB1_NM: 8 ZCUF
 SG_ ZCUF_NodeAddress_VB1 : 0|8@1+ (1,0) [0|255] ""  ZCUT,HDBI,HDBM,ZCUL,HDBA,ZCUR,HDBT
 SG_ ZCUF_RepeatMsgReq_VB1 : 8|1@1+ (1,0) [0|1] ""  ZCUT,HDBI,HDBM,ZCUL,HDBA,ZCUR,HDBT
 SG_ ZCUF_ActiveWakeup_VB1 : 12|1@1+ (1,0) [0|1] ""  ZCUT,HDBI,HDBM,ZCUL,HDBA,ZCUR,HDBT
 SG_ ZCUF_PartialNetworkInfo_VB1 : 14|1@1+ (1,0) [0|1] ""  ZCUT,HDBI,HDBM,ZCUL,HDBA,HDBT,ZCUR
 SG_ ZCUF_RepeatMsgSt_VB1 : 16|1@1+ (1,0) [0|1] ""  ZCUT,HDBI,HDBM,ZCUL,HDBA,ZCUR,HDBT
 SG_ ZCUF_PN_HDBT_VB1 : 24|1@1+ (1,0) [0|1] ""  ZCUT,HDBI,HDBM,ZCUL,HDBA,ZCUR,HDBT
 SG_ ZCUF_PN_HDBI_VB1 : 25|1@1+ (1,0) [0|1] ""  ZCUT,HDBI,HDBM,ZCUL,HDBA,ZCUR,HDBT
 SG_ ZCUF_PN_HDBA_VB1 : 26|1@1+ (1,0) [0|1] ""  ZCUT,HDBI,HDBM,ZCUL,HDBA,ZCUR,HDBT
 SG_ ZCUF_PN_HDBM_VB1 : 27|1@1+ (1,0) [0|1] ""  ZCUT,HDBI,HDBM,ZCUL,HDBA,ZCUR,HDBT
 SG_ ZCUF_PN_ZCUF_VB1 : 28|1@1+ (1,0) [0|1] ""  ZCUT,HDBI,HDBM,ZCUL,HDBA,ZCUR,HDBT
 SG_ ZCUF_PN_ZCUL_VB1 : 29|1@1+ (1,0) [0|1] ""  ZCUT,HDBI,HDBM,ZCUL,HDBA,ZCUR,HDBT
 SG_ ZCUF_PN_ZCUR_VB1 : 30|1@1+ (1,0) [0|1] ""  ZCUT,HDBI,HDBM,ZCUL,HDBA,ZCUR,HDBT
 SG_ ZCUF_PN_ZCUT_VB1 : 31|1@1+ (1,0) [0|1] ""  ZCUT,HDBI,HDBM,ZCUL,HDBA,ZCUR,HDBT

BO_ 562 TCM_FD_RT_1: 32 ZCUF
 SG_ AQS_NoxWert_Val : 56|10@1+ (1,0) [0|1023] ""  HDBM
 SG_ AQS_NoxBereich_St : 40|2@1+ (1,0) [0|3] ""  HDBM
 SG_ AQS_Nox_St : 48|4@1+ (1,0) [0|15] ""  HDBM
 SG_ CHVH_InltTmp_Val : 16|8@1+ (1,-40) [-40|215] "℃"  ZCUF,HDBM
 SG_ CHVH_OutltTmp_Val : 24|8@1+ (1,-40) [-40|215] "℃"  ZCUF,HDBM
 SG_ AQS_Luftguete_Val : 52|4@1+ (1,0) [0|15] ""  HDBM
 SG_ TCM_FD_RT_1_AQSAvailable_St : 68|2@1+ (1,0) [0|3] ""  HDBM
 SG_ CHVH_ActuPwr_Val : 32|8@1+ (50,0) [0|12750] "W"  HDBM
 SG_ CHVH_Fault_St : 42|2@1+ (2,0) [0|3] ""  HDBM

BO_ 514 TCM_FCANFD1_1: 32 ZCUF
 SG_ TCM_V3WHeatActualPos_Val : 32|8@1+ (1,0) [0|100] "%"  ZCUF,HDBM
 SG_ TCM_ThermalCoolantTemp_Val : 96|8@1+ (1,-40) [-40|100] "℃"  ZCUF,HDBM
 SG_ TCM_OHXEXVRun_St : 149|1@1+ (1,0) [0|1] ""  HDBM
 SG_ TCM_OHXEXVPos_Val : 0|16@1+ (1,0) [0|576] ""  HDBM
 SG_ TCM_OHXEXVOverTempWarn_St : 162|2@1+ (1,0) [0|3] ""  HDBM
 SG_ TCM_OHXEXVInit_St : 158|2@1+ (1,0) [0|3] ""  HDBM
 SG_ TCM_OHXEXVFault_St : 168|4@1+ (1,0) [0|15] ""  HDBM
 SG_ TCM_OHXEXVCal_Req : 160|2@1+ (1,0) [0|3] ""  HDBM
 SG_ TCM_LINPowerHSD_St : 142|2@1+ (1,0) [0|3] ""  HDBM
 SG_ TCM_HPLowPressSOVFault_St : 182|1@1+ (1,0) [0|1] ""  HDBM
 SG_ TCM_HPLowPressSOV_St : 138|2@1+ (1,0) [0|3] ""  HDBM
 SG_ TCM_HPHighPressSOVFault_St : 175|1@1+ (1,0) [0|1] ""  HDBM
 SG_ TCM_HPHighPressSOV_St : 140|2@1+ (1,0) [0|3] ""  HDBM
 SG_ TCM_HPChillerTempValid_St : 145|1@1+ (1,0) [0|1] ""  HDBM
 SG_ TCM_HPChillerTemp_Val : 16|16@1+ (0.1,-40) [-40|80] ""  HDBM
 SG_ TCM_HEXVRun_St : 174|1@1+ (1,0) [0|1] ""  HDBM
 SG_ TCM_HEXVPos_Val : 72|10@1+ (1,0) [0|576] "step"  HDBM
 SG_ TCM_HEXVOverTempWarn_St : 156|2@1+ (1,0) [0|3] ""  HDBM
 SG_ TCM_HEXVInit_St : 154|2@1+ (1,0) [0|3] ""  HDBM
 SG_ TCM_HEXVFault_St : 176|4@1+ (1,0) [0|15] ""  HDBM
 SG_ TCM_HEXVCal_Req : 172|2@1+ (1,0) [0|3] ""  HDBM
 SG_ TCM_HeatPumpAcutalSpdPct_Val : 88|8@1+ (1,0) [0|100] "%"  ZCUF,HDBM
 SG_ TCM_FHVACOutletTempValid_St : 146|1@1+ (1,0) [0|1] ""  HDBM
 SG_ TCM_FHVACOutletTemp_Val : 120|16@1+ (0.1,-40) [-40|80] ""  HDBM
 SG_ TCM_CombChillerTempValid_St : 144|1@1+ (1,0) [0|1] ""  HDBM
 SG_ TCM_CombChillerTemp_Val : 56|16@1+ (0.1,-40) [-40|80] ""  HDBM
 SG_ TCM_ChillerEXVRun_St : 181|1@1+ (1,0) [0|1] ""  HDBM
 SG_ TCM_ChillerEXVPos_Val : 104|16@1+ (1,0) [0|576] ""  HDBM
 SG_ TCM_ChillerEXVOverTempWarn_St : 150|2@1+ (1,0) [0|3] ""  HDBM
 SG_ TCM_ChillerEXVInit_St : 147|2@1+ (1,0) [0|3] ""  HDBM
 SG_ TCM_ChillerEXVFault_St : 164|4@1+ (1,0) [0|15] ""  HDBM
 SG_ TCM_ChillerEXVCal_Req : 152|2@1+ (1,0) [0|3] ""  HDBM
 SG_ TCM_ACSOVFault_St : 180|1@1+ (1,0) [0|1] ""  HDBM
 SG_ TCM_ACSOV_St : 136|2@1+ (1,0) [0|3] ""  HDBM

BO_ 515 TCM_FCANFD1_2: 32 ZCUF
 SG_ TCM_V5WV4wActualPosition_Val : 106|2@1+ (1,0) [0|3] ""  ZCUF,HDBM
 SG_ TCM_V5WV3wActualPosition_Val : 136|8@1+ (1,0) [0|100] "%"  ZCUF,HDBM
 SG_ TCM_V5wMotor_St : 105|1@1+ (1,0) [0|1] ""  ZCUF,HDBM
 SG_ TCM_V5wFault_St : 116|1@1+ (1,0) [0|1] ""  ZCUF,HDBM
 SG_ TCM_V3wMotFault_St : 104|1@1+ (1,0) [0|1] ""  ZCUF,HDBM
 SG_ TCM_V3WHeatPMotor_St : 111|1@1+ (1,0) [0|1] ""  ZCUF,HDBM
 SG_ TCM_V3WHeatPCal_Req : 109|2@1+ (1,0) [0|3] ""  ZCUF,HDBM
 SG_ TCM_V3WHeatFault_St : 108|1@1+ (1,0) [0|1] ""  ZCUF,HDBM
 SG_ TCM_V3WHeatCal_St : 117|2@1+ (1,0) [0|3] ""  ZCUF,HDBM
 SG_ TCM_ThermalLiquidLackWarn_St : 126|2@1+ (1,0) [0|3] ""  ZCUF,HDBM
 SG_ TCM_RessPumpFault_St : 112|2@1+ (2,0) [0|3] ""  ZCUF,HDBM
 SG_ TCM_PowerVoltage_Val : 94|10@1+ (0.1,0) [0|30] "V"  ZCUF,HDBM
 SG_ TCM_PowerOffDelay_Req : 88|2@1+ (1,0) [0|3] ""  ZCUF,HDBM
 SG_ TCM_MotPumpFault_St : 120|2@1+ (2,0) [0|3] ""  ZCUF,HDBM
 SG_ TCM_HeatPumpFault_St : 114|2@1+ (2,0) [0|3] ""  ZCUF,HDBM
 SG_ TCM_HeatLiquidtLackWarn_St : 124|2@1+ (1,0) [0|3] ""  ZCUF,HDBM

BO_ 164 EHBM_CHBK_WorkState: 32 ZCUF
 SG_ EHBM_ABS_Err : 33|1@1+ (1,0) [0|1] ""  HDBI,ZCUF,HDBM,HDBA
 SG_ EHBM_EBD_Err : 35|1@1+ (1,0) [0|1] ""  HDBI,HDBM,HDBA
 SG_ EHBM_BrakeLight_Req : 46|1@1+ (1,0) [0|1] ""  HDBM
 SG_ EHBM_ModeChgEnable_St : 60|1@1+ (1,0) [0|1] ""  HDBM
 SG_ EHBM_CST_Rsp : 30|2@1+ (1,0) [0|3] ""  HDBI,HDBM
 SG_ EHBM_ESC_Err : 28|1@1+ (1,0) [0|1] ""  ZCUF,HDBM,HDBA
 SG_ EHBM_EmergencyBrakeLight_Req : 47|1@1+ (1,0) [0|1] ""  HDBM
 SG_ EHBM_PataLamp_St : 43|1@1+ (1,0) [0|1] ""  HDBI,ZCUF,HDBM,HDBA
 SG_ EHBM_VehSpd_Val : 112|13@1+ (0.05625,0) [0|300] "km/h"  ZCUT,HDBI,ZCUF,HDBM,ZCUL,HDBA,HDBT
 SG_ EHBM_VehSpdValid_St : 91|1@1+ (1,0) [0|1] ""  ZCUT,HDBI,ZCUF,HDBM,ZCUL,HDBT
 SG_ EHBM_WorkMode_St : 56|4@1+ (1,0) [0|15] ""  HDBM
 SG_ EHBM_InputRodStroke_Val : 96|12@1+ (0.05,-5) [-5|46.15] "mm"  HDBI,HDBM
 SG_ EHBM_InputRodStroke_St : 92|2@1+ (1,0) [0|3] ""  HDBI,HDBM
 SG_ EHBM_BrakePedal_St : 48|1@1+ (1,0) [0|1] ""  HDBI,ZCUF,HDBM,HDBT
 SG_ EHBM_BrakeMode_St : 53|3@1+ (1,0) [0|7] ""  HDBI,HDBM
 SG_ EHBM_BrakeModeEnable_St : 51|2@1+ (1,0) [0|3] ""  HDBI,HDBM
 SG_ EHBM_VDCorTCSIntv_St : 40|1@1+ (1,0) [0|1] ""  HDBI,ZCUF,HDBM
 SG_ EHBM_CtrllerFault_St : 29|1@1+ (1,0) [0|1] ""  HDBM
 SG_ EHBM_VDCIntv_St : 42|1@1+ (1,0) [0|1] ""  HDBI,ZCUF,HDBM
 SG_ EHBM_ESCSys_Err : 27|1@1+ (1,0) [0|1] ""  HDBM
 SG_ EHBM_ESCFunSys_St : 24|3@1+ (1,0) [0|7] ""  HDBI,HDBM,HDBT
 SG_ EHBM_ABSIntv_St : 32|1@1+ (1,0) [0|1] ""  HDBI,ZCUF,HDBM,HDBT
 SG_ EHBM_EBDIntv_St : 34|1@1+ (1,0) [0|1] ""  HDBI,HDBM
 SG_ EHBM_BrakeFluidLvl_St : 44|2@1+ (1,0) [0|3] ""  HDBI,HDBM
 SG_ EHBM_Checksum3 : 0|16@1+ (1,0) [0|65535] ""  HDBI,ZCUF,HDBM,ZCUL,HDBA
 SG_ EHBM_RollingCounter3 : 16|8@1+ (1,0) [0|255] ""  HDBI,ZCUF,HDBM,ZCUL,HDBA
 SG_ EHBM_HDCAvail_St : 73|1@1+ (1,0) [0|1] ""  HDBI,ZCUF,HDBM
 SG_ EHBM_HDC_St : 74|2@1+ (1,0) [0|3] ""  HDBI,ZCUF,HDBM
 SG_ EHBM_BoostDegrade_St : 88|3@1+ (1,0) [0|7] ""  HDBI,ZCUF,HDBM
 SG_ EHBM_ESCSwAvail_St : 68|1@1+ (1,0) [0|1] ""  HDBM
 SG_ EHBM_ESClamp_St : 69|1@1+ (1,0) [0|1] ""  HDBM
 SG_ EHBM_TCSSwAvail_St : 70|1@1+ (1,0) [0|1] ""  HDBM
 SG_ EHBM_AVH_St : 64|2@1+ (1,0) [0|3] ""  HDBM
 SG_ EHBM_AVHAvail_St : 66|1@1+ (1,0) [0|1] ""  HDBM

BO_ 226 ERPB_CHBU_EPBState: 32 ZCUF
 SG_ ERPB_BU_OperationReminder_UI : 20|4@1+ (1,0) [0|15] ""  HDBI,HDBM
 SG_ ERPB_BU_EPBHardSwitch_St : 40|2@1+ (1,0) [0|3] ""  HDBI,ZCUF,HDBM
 SG_ ERPB_BU_EPBFunctionLamp_St : 32|2@1+ (1,0) [0|3] ""  HDBI,HDBM
 SG_ ERPB_BU_EPBFailLamp_St : 34|2@1+ (1,0) [0|3] ""  HDBI,HDBM
 SG_ ERPB_BU_EPB_St : 45|3@1+ (1,0) [0|7] ""  HDBI,HDBM
 SG_ ERPB_BU_CapacityLimitWarn_UI : 16|4@1+ (1,0) [0|15] ""  HDBI,HDBM
 SG_ ERPB_BU_BrakeLight_Req : 44|1@1+ (1,0) [0|1] ""  HDBM

BO_ 160 ACU_CHBK_AxisAccelandCollision: 32 ZCUF
 SG_ ACU_YawRateValid_St : 27|1@1+ (1,0) [0|1] ""  HDBM,HDBA
 SG_ ACU_YawRate_Val : 104|16@1+ (0.01,-300) [-300|300] "°/s"  HDBM,HDBA,HDBT
 SG_ ACU_LtrlAccelValid_St : 25|1@1+ (1,0) [0|1] ""  ZCUF,HDBM,HDBA
 SG_ ACU_LtrlAccel_Val : 72|16@1+ (0.0002,-6) [-6|6] "g"  ZCUF,HDBM,HDBA
 SG_ ACU_LongAccel_Val : 56|16@1+ (0.0002,-6) [-6|6] "g"  ZCUF,HDBM,HDBA
 SG_ ACU_AirbagWarnLamp_St : 32|2@1+ (1,0) [0|3] ""  HDBM
 SG_ ACU_DrvrSeatBelt_St : 31|1@1+ (1,0) [0|1] ""  HDBM
 SG_ ACU_DrvrSeatBeltValid_St : 30|1@1+ (1,0) [0|1] ""  HDBM

BO_ 176 EPS_CHBK_WorkState: 32 ZCUF
 SG_ EPS_WorkMode_St : 93|3@1+ (1,0) [0|7] ""  HDBM,HDBA
 SG_ EPS_System_Err : 134|2@1+ (1,0) [0|3] ""  HDBI,HDBM,HDBA
 SG_ EPS_ModeChangeEn_St : 92|1@1+ (1,0) [0|1] ""  HDBM

BO_ 800 HDBI_VB1_2: 32 HDBI
 SG_ HDBI_NFCAvailability_St : 56|2@1+ (1,0) [0|3] ""  HDBM

BO_ 820 HDBI_VB1_3: 32 HDBI

BO_ 1501 HDBI_VB1_NMIndication: 32 HDBI
 SG_ HDBI_VB1_NetworkReqCondition0 : 0|8@1+ (1,0) [0|255] ""  HDBM
 SG_ HDBI_VB1_NetworkReqCondition1 : 8|8@1+ (1,0) [0|255] ""  HDBM
 SG_ HDBI_VB1_NetworkReqCondition2 : 16|8@1+ (1,0) [0|255] ""  HDBM
 SG_ HDBI_VB1_NetworkReqCondition3 : 24|8@1+ (1,0) [0|255] ""  HDBM
 SG_ HDBI_VB1_NetworkReqCondition4 : 32|8@1+ (1,0) [0|255] ""  HDBM
 SG_ HDBI_VB1_NetworkReqCondition5 : 40|8@1+ (1,0) [0|255] ""  HDBM
 SG_ HDBI_VB1_NetworkReqCondition6 : 48|8@1+ (1,0) [0|255] ""  HDBM
 SG_ HDBI_VB1_NetworkReqCondition7 : 56|8@1+ (1,0) [0|255] ""  HDBM
 SG_ HDBI_VB1_NetworkReqCondition8 : 64|8@1+ (1,0) [0|255] ""  HDBM
 SG_ HDBI_VB1_NetworkReqCondition9 : 72|8@1+ (1,0) [0|255] ""  HDBM
 SG_ HDBI_VB1_NetworkReqCondition10 : 80|8@1+ (1,0) [0|255] ""  HDBM
 SG_ HDBI_VB1_NetworkReqCondition11 : 88|8@1+ (1,0) [0|255] ""  HDBM
 SG_ HDBI_VB1_NetworkReqCondition12 : 96|8@1+ (1,0) [0|255] ""  HDBM
 SG_ HDBI_VB1_NetworkReqCondition13 : 104|8@1+ (1,0) [0|255] ""  HDBM
 SG_ HDBI_VB1_NetworkReqCondition14 : 112|8@1+ (1,0) [0|255] ""  HDBM
 SG_ HDBI_VB1_NetworkReqCondition15 : 120|8@1+ (1,0) [0|255] ""  HDBM
 SG_ HDBI_VB1_NetworkReqCondition16 : 128|8@1+ (1,0) [0|255] ""  HDBM
 SG_ HDBI_VB1_NetworkReqCondition17 : 136|8@1+ (1,0) [0|255] ""  HDBM
 SG_ HDBI_VB1_NetworkReqCondition18 : 144|8@1+ (1,0) [0|255] ""  HDBM
 SG_ HDBI_VB1_NetworkReqCondition19 : 152|8@1+ (1,0) [0|255] ""  HDBM
 SG_ HDBI_VB1_NetworkReqCondition20 : 160|8@1+ (1,0) [0|255] ""  HDBM
 SG_ HDBI_VB1_NetworkReqCondition21 : 168|8@1+ (1,0) [0|255] ""  HDBM
 SG_ HDBI_VB1_NetworkReqCondition22 : 176|8@1+ (1,0) [0|255] ""  HDBM
 SG_ HDBI_VB1_NetworkReqCondition23 : 184|8@1+ (1,0) [0|255] ""  HDBM
 SG_ HDBI_VB1_NetworkReqCondition24 : 192|8@1+ (1,0) [0|255] ""  HDBM
 SG_ HDBI_VB1_NetworkReqCondition25 : 200|8@1+ (1,0) [0|255] ""  HDBM
 SG_ HDBI_VB1_NetworkReqCondition26 : 208|8@1+ (1,0) [0|255] ""  HDBM
 SG_ HDBI_VB1_NetworkReqCondition27 : 216|8@1+ (1,0) [0|255] ""  HDBM
 SG_ HDBI_VB1_NetworkReqCondition28 : 224|8@1+ (1,0) [0|255] ""  HDBM
 SG_ HDBI_VB1_NetworkReqCondition29 : 232|8@1+ (1,0) [0|255] ""  HDBM
 SG_ HDBI_VB1_NetworkReqCondition30 : 240|8@1+ (1,0) [0|255] ""  HDBM
 SG_ HDBI_VB1_NetworkReqCondition31 : 248|8@1+ (1,0) [0|255] ""  HDBM

BO_ 1344 HDBI_NMWakeup: 32 HDBI
 SG_ HDBI_WakeupReq_HDBI : 8|8@1+ (1,0) [0|255] ""  HDBM
 SG_ HDBI_WakeupReq_HDBM : 24|8@1+ (1,0) [0|255] ""  HDBM

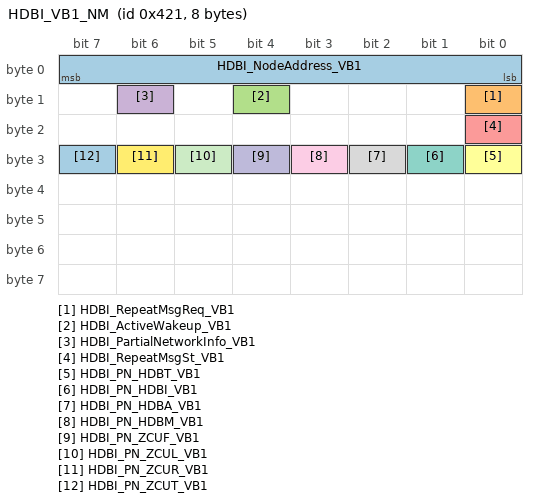
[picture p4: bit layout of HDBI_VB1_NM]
BO_ 1057 HDBI_VB1_NM: 8 HDBI
 SG_ HDBI_NodeAddress_VB1 : 0|8@1+ (1,0) [0|255] ""  ZCUT,ZCUF,HDBM,ZCUL,HDBA,ZCUR,HDBT
 SG_ HDBI_RepeatMsgReq_VB1 : 8|1@1+ (1,0) [0|1] ""  ZCUT,ZCUF,HDBM,ZCUL,HDBA,ZCUR,HDBT
 SG_ HDBI_ActiveWakeup_VB1 : 12|1@1+ (1,0) [0|1] ""  ZCUT,ZCUF,HDBM,ZCUL,HDBA,ZCUR,HDBT
 SG_ HDBI_PartialNetworkInfo_VB1 : 14|1@1+ (1,0) [0|1] ""  ZCUT,ZCUF,HDBM,ZCUL,HDBA,ZCUR,HDBT
 SG_ HDBI_RepeatMsgSt_VB1 : 16|1@1+ (1,0) [0|1] ""  ZCUT,ZCUF,HDBM,ZCUL,HDBA,ZCUR,HDBT
 SG_ HDBI_PN_HDBT_VB1 : 24|1@1+ (1,0) [0|1] ""  ZCUT,ZCUF,HDBM,ZCUL,HDBA,HDBT,ZCUR
 SG_ HDBI_PN_HDBI_VB1 : 25|1@1+ (1,0) [0|1] ""  ZCUT,ZCUF,HDBM,ZCUL,HDBA,HDBT
 SG_ HDBI_PN_HDBA_VB1 : 26|1@1+ (1,0) [0|1] ""  ZCUT,ZCUF,HDBM,ZCUL,HDBA,HDBT,ZCUR
 SG_ HDBI_PN_HDBM_VB1 : 27|1@1+ (1,0) [0|1] ""  ZCUT,ZCUF,HDBM,ZCUL,HDBA,HDBT,ZCUR
 SG_ HDBI_PN_ZCUF_VB1 : 28|1@1+ (1,0) [0|1] ""  ZCUT,ZCUF,HDBM,ZCUL,HDBA,ZCUR,HDBT
 SG_ HDBI_PN_ZCUL_VB1 : 29|1@1+ (1,0) [0|1] ""  ZCUT,ZCUF,HDBM,ZCUL,HDBA,HDBT,ZCUR
 SG_ HDBI_PN_ZCUR_VB1 : 30|1@1+ (1,0) [0|1] ""  ZCUT,ZCUF,HDBM,ZCUL,HDBA,ZCUR,HDBT
 SG_ HDBI_PN_ZCUT_VB1 : 31|1@1+ (1,0) [0|1] ""  ZCUT,ZCUF,HDBM,ZCUL,HDBA,ZCUR,HDBT

CM_ SG_ 656 ZCUR_FHVACBypassMotor_Err "


前Bypass模式风门电机状态反馈





";
CM_ SG_ 656 ZCUR_FHVACDefrostMotor_Err "

前除雾风门电机状态反馈




";
CM_ SG_ 656 ZCUR_FHVACBLW_Err "


前鼓风机电机状态反馈





";
CM_ SG_ 656 ZCUR_FHVACModePos_Rsp "


前出风模式风门位置反馈


";
CM_ SG_ 656 ZCUR_FHVACCyclePos_Rsp "


前内外循环风门位置反馈


";
CM_ SG_ 656 ZCUR_FHVACBypassPos_Rsp "


前Bypass模式风门位置反馈


";
CM_ SG_ 656 ZCUR_FHVACDefrostPos_Rsp "


前除雾风门位置反馈


";
CM_ SG_ 656 ZCUR_FHVACBLWPWM_Rsp "

前鼓风机转速占空比反馈



";
CM_ SG_ 656 ZCUR_FHVACBLWRelay_St "
前鼓风机继电器状态反馈


";
CM_ SG_ 656 ZCUR_FHVACLeftMixPos_Rsp "


前左冷暖风门位置反馈


";
CM_ SG_ 656 ZCUR_FHVACRigtMixPos_Rsp "


前右冷暖风门位置反馈


";
CM_ SG_ 656 ZCUR_FHVACLeftMixMotor_Err "
前左冷暖风门电机状态反馈




";
CM_ SG_ 656 ZCUR_FHVACModeMotor_Err "
前出风模式风门电机状态反馈




";
CM_ SG_ 656 ZCUR_FHVACCycleMotor_Err "
前内外循环风门电机状态反馈




";
CM_ SG_ 656 ZCUR_FHVACBLWRelay_Err "
前鼓风机继电器故障状态反馈
";
CM_ SG_ 656 ZCUR_FHVACRigtMixMotor_Err "
前右冷暖风门电机状态反馈
";
CM_ SG_ 657 ZCUR_TDuctRVValid_St "

右侧吹面通道温度有效性

";
CM_ SG_ 657 ZCUR_TDuctLFValid_St "

左侧吹脚通道温度有效性

";
CM_ SG_ 657 ZCUR_TDuctRFValid_St "

右侧吹脚通道温度有效性

";
CM_ SG_ 657 ZCUR_ADSTws_Val "

ADS自动除雾传感器-玻璃表面温度

";
CM_ SG_ 657 ZCUR_ION_St "



等离子发生器开关状态反馈



";
CM_ SG_ 657 ZCUR_ADSTrh_Val "

ADS自动除雾传感器-玻璃附近温度

";
CM_ SG_ 657 ZCUR_ADShumidity_Val "

ADS自动除雾传感器-玻璃表面湿度

";
CM_ SG_ 657 ZCUR_TcabOrig_Val "

车内温度原始值

";
CM_ SG_ 657 ZCUR_TEvapOrig_Val "

蒸发器温度原始值

";
CM_ SG_ 657 ZCUR_TDuctLV_Val "

左侧吹面通道温度

";
CM_ SG_ 657 ZCUR_TDuctRV_Val "

右侧吹面通道温度

";
CM_ SG_ 657 ZCUR_TDuctLF_Val "

左侧吹脚通道温度

";
CM_ SG_ 657 ZCUR_TDuctRF_Val "


右侧吹脚通道温度


";
CM_ SG_ 657 ZCUR_ADS_Valid_St "

ADS自动除雾传感器有效性

";
CM_ SG_ 657 ZCUR_TcabOrigValid_St "

车内温度原始值有效性

";
CM_ SG_ 657 ZCUR_TEvapOrigValid_St "

蒸发器温度原始值有效性

";
CM_ SG_ 657 ZCUR_TDuctLVValid_St "

左侧吹面通道温度有效性

";
CM_ SG_ 657 ZCUR_ION_Err "
等离子发生器故障状态
";
CM_ SG_ 657 ZCUR_PM25Sensor_Err "
PM2.5传感器故障状态
";
CM_ SG_ 657 ZCUR_CmpmtInAirPmDnsty_Val "

空气质量浓度

";
CM_ SG_ 657 ZCUR_CmpmtInAirPmAQI_St "

AQI值

";
CM_ SG_ 912 ZCUR_RRHdl_Err "

右后把手故障信号

";
CM_ SG_ 912 ZCUR_FRHdlWork_St "

右前把手工作状态

";
CM_ SG_ 912 ZCUR_RRHdlWork_St "

右后把手工作状态

";
CM_ SG_ 912 ZCUR_FRHdl_Err "

右前把手故障信号

";
CM_ SG_ 912 ZCUR_FRSeatHt_Rsp "



副驾座椅加热状态反馈



";
CM_ SG_ 912 ZCUR_FRSeatHtStpRsn_St "




副驾座椅加热停止原因




";
CM_ SG_ 912 ZCUR_FRSeatVtlt_Rsp "



副驾座椅通风状态反馈



";
CM_ SG_ 912 ZCUR_FRSeatVtltStpRsn_St "




副驾座椅通风停止原因




";
CM_ SG_ 912 ZCUR_RExMirHt_Rsp "



右外后视镜加热状态反馈



";
CM_ SG_ 912 ZCUR_RExMirHtStpRsn_St "




右外后视镜加热停止原因




";
CM_ SG_ 1472 ZCUR_HSDLVPower_Err "



ZCUR二级配电HSD供电故障
每个Bit位代表一个控制器电源故障状态 0:No Fault 1:Fault


";
CM_ SG_ 1472 ZCUR_HSDLVPower_St "

 ZCUR二级配电HSD供电状态  每个Bit位代表一个控制器电源状态 0;Power Off 1:Power On

";
CM_ SG_ 1472 ZCUR_PERMLVPower_Err "
ZCUR二级配电eFuse常电供电故障每个Bit位代表一个控制器电源故障状态 0:No Fault 1:Fault 
";
CM_ SG_ 1472 ZCUR_PERMLVPower_St "
 ZCUR二级配电eFuse常电供电状态每个Bit位代表一个控制器电源状态 0:Power Off 1:Power On
";
CM_ SG_ 1472 ZCUR_FRSeatHgtAdjLn_St "
副驾座椅高低调节电机学习状态



";
CM_ SG_ 1472 ZCUR_FRSeatCshnAngAdjLn_St "

副驾座椅坐垫角度调节电机学习状态



";
CM_ SG_ 1472 ZCUR_FRLegAngCshnExtLn_St "

副驾座椅腿托角度/坐垫延伸调节电机学习状态



";
CM_ SG_ 1472 ZCUR_FRWinStpRsn_St "
右前车窗停止原因



";
CM_ SG_ 1472 ZCUR_RRWinStpRsn_St "
右后车窗停止原因



";
CM_ SG_ 1472 ZCUR_FRWinStp_Req "

右前车窗过热状态




";
CM_ SG_ 1472 ZCUR_RRWinStp_Req "

右后车窗过热状态




";
CM_ SG_ 1472 ZCUR_FRHdlFrzLn_Val "

右前把手破冰学习次数

";
CM_ SG_ 1472 ZCUR_RRHdlFrzLn_Val "

右后把手破冰学习次数

";
CM_ SG_ 1472 ZCUR_FRHdlFrzLnTime_Val "

右前把手破冰学习时间

";
CM_ SG_ 1472 ZCUR_RRHdlFrzLnTime_Val "

右后把手破冰学习时间

";
CM_ SG_ 1472 ZCUR_FRSeatFBAdjLn_St "

副驾座椅前后调节电机学习状态



";
CM_ SG_ 1472 ZCUR_FRSeatBackrestAdjLn_St "

副驾座椅靠背调节电机学习状态

";
CM_ SG_ 658 ZCUR_FRDrPdlLtWrk_St "

右前门踏板灯工作状态

";
CM_ SG_ 658 ZCUR_RRDrPdlLtWrk_St "

右后门踏板灯工作状态

";
CM_ SG_ 658 ZCUR_RLMirLtWrk_St "


右化妆镜灯工作状态


";
CM_ SG_ 1106 ZCUR_NodeAddress_VB1 "
Node source address
节点源地址
";
CM_ SG_ 1106 ZCUR_RepeatMsgReq_VB1 "
Repeat Message Request Bit
重复报文请求位
";
CM_ SG_ 1106 ZCUR_ActiveWakeup_VB1 "
Active Wakeup Bit
主动唤醒指示位
";
CM_ SG_ 1106 ZCUR_PartialNetworkInfo_VB1 "
Partial Network Information Bit
部分网络管理信息指示位
";
CM_ SG_ 1106 ZCUR_RepeatMsgSt_VB1 "
Repeat Message State indication
节点处在重复报文状态指示位
";
CM_ SG_ 1106 ZCUR_PN_HDBT_VB1 "
Wakeup Target ECU requirement flag
唤醒目标ECU需求标志
";
CM_ SG_ 1106 ZCUR_PN_HDBI_VB1 "
Wakeup Target ECU requirement flag
唤醒目标ECU需求标志
";
CM_ SG_ 1106 ZCUR_PN_HDBA_VB1 "
Wakeup Target ECU requirement flag
唤醒目标ECU需求标志
";
CM_ SG_ 1106 ZCUR_PN_HDBM_VB1 "
Wakeup Target ECU requirement flag
唤醒目标ECU需求标志
";
CM_ SG_ 1106 ZCUR_PN_ZCUF_VB1 "
Wakeup Target ECU requirement flag
唤醒目标ECU需求标志
";
CM_ SG_ 1106 ZCUR_PN_ZCUL_VB1 "
Wakeup Target ECU requirement flag
唤醒目标ECU需求标志
";
CM_ SG_ 1106 ZCUR_PN_ZCUR_VB1 "
Wakeup Target ECU requirement flag
唤醒目标ECU需求标志
";
CM_ SG_ 1106 ZCUR_PN_ZCUT_VB1 "
Wakeup Target ECU requirement flag
唤醒目标ECU需求标志
";
CM_ SG_ 1414 ZCUR_WakeupReq_HDBT " Wakeup HDBT domain-related ECU flag bits, each bit represents an ECU, the correspondence between bit and ECU refers to Sleep Wakeup List 唤醒HDBT域相关ECU标志位，每一bit位代表一个ECU，具体bit与ECU的对应关系见休眠唤醒列表。 ";
CM_ SG_ 1414 ZCUR_WakeupReq_HDBI " Wakeup HDBI domain-related ECU flag bits, each bit represents an ECU, the correspondence between bit and ECU refers to Sleep Wakeup List 唤醒HDBI域相关ECU标志位，每一bit位代表一个ECU，具体bit与ECU的对应关系见休眠唤醒列表。 ";
CM_ SG_ 1414 ZCUR_WakeupReq_HDBA " Wakeup HDBA domain-related ECU flag bits, each bit represents an ECU, the correspondence between bit and ECU refers to Sleep Wakeup List 唤醒HDBA域相关ECU标志位，每一bit位代表一个ECU，具体bit与ECU的对应关系见休眠唤醒列表。 ";
CM_ SG_ 1414 ZCUR_WakeupReq_HDBM " Wakeup HDBM domain-related ECU flag bits, each bit represents an ECU, the correspondence between bit and ECU refers to Sleep Wakeup List 唤醒HDBM域相关ECU标志位，每一bit位代表一个ECU，具体bit与ECU的对应关系见休眠唤醒列表。 ";
CM_ SG_ 1414 ZCUR_WakeupReq_ZCUF " Wakeup ZCUF domain-related ECU flag bits, each bit represents an ECU, the correspondence between bit and ECU refers to Sleep Wakeup List 唤醒ZCUF域相关ECU标志位，每一bit位代表一个ECU，具体bit与ECU的对应关系见休眠唤醒列表。 ";
CM_ SG_ 1414 ZCUR_WakeupReq_ZCUL " Wakeup ZCUL domain-related ECU flag bits, each bit represents an ECU, the correspondence between bit and ECU refers to Sleep Wakeup List 唤醒ZCUL域相关ECU标志位，每一bit位代表一个ECU，具体bit与ECU的对应关系见休眠唤醒列表。 ";
CM_ SG_ 1414 ZCUR_WakeupReq_ZCUR " Wakeup ZCUR domain-related ECU flag bits, each bit represents an ECU, the correspondence between bit and ECU refers to Sleep Wakeup List 唤醒ZCUR域相关ECU标志位，每一bit位代表一个ECU，具体bit与ECU的对应关系见休眠唤醒列表。 ";
CM_ SG_ 1414 ZCUR_WakeupReq_ZCUT " Wakeup ZCUT domain-related ECU flag bits, each bit represents an ECU, the correspondence between bit and ECU refers to Sleep Wakeup List 唤醒ZCUT域相关ECU标志位，每一bit位代表一个ECU，具体bit与ECU的对应关系见休眠唤醒列表。 ";
CM_ SG_ 1495 ZCUR_VB1_NetworkReqCondition0 "
Wakeup or Request or Keep Network Condition0
唤醒或请求或保持网络条件1
";
CM_ SG_ 1495 ZCUR_VB1_NetworkReqCondition1 "
Wakeup or Request or Keep Network Condition1
唤醒或请求或保持网络条件1
";
CM_ SG_ 1495 ZCUR_VB1_NetworkReqCondition2 "
Wakeup or Request or Keep Network Condition2
唤醒或请求或保持网络条件2
";
CM_ SG_ 1495 ZCUR_VB1_NetworkReqCondition3 "
Wakeup or Request or Keep Network Condition3
唤醒或请求或保持网络条件3
";
CM_ SG_ 1495 ZCUR_VB1_NetworkReqCondition4 "
Wakeup or Request or Keep Network Condition4
唤醒或请求或保持网络条件4
";
CM_ SG_ 1495 ZCUR_VB1_NetworkReqCondition5 "
Wakeup or Request or Keep Network Condition5
唤醒或请求或保持网络条件5
";
CM_ SG_ 1495 ZCUR_VB1_NetworkReqCondition6 "
Wakeup or Request or Keep Network Condition6
唤醒或请求或保持网络条件6
";
CM_ SG_ 1495 ZCUR_VB1_NetworkReqCondition7 "
Wakeup or Request or Keep Network Condition7
唤醒或请求或保持网络条件7
";
CM_ SG_ 1495 ZCUR_VB1_NetworkReqCondition8 "
Wakeup or Request or Keep Network Condition8
唤醒或请求或保持网络条件8
";
CM_ SG_ 1495 ZCUR_VB1_NetworkReqCondition9 "
Wakeup or Request or Keep Network Condition9
唤醒或请求或保持网络条件9
";
CM_ SG_ 1495 ZCUR_VB1_NetworkReqCondition10 "
Wakeup or Request or Keep Network Condition10
唤醒或请求或保持网络条件10
";
CM_ SG_ 1495 ZCUR_VB1_NetworkReqCondition11 "
Wakeup or Request or Keep Network Condition11
唤醒或请求或保持网络条件11
";
CM_ SG_ 1495 ZCUR_VB1_NetworkReqCondition12 "
Wakeup or Request or Keep Network Condition12
唤醒或请求或保持网络条件12
";
CM_ SG_ 1495 ZCUR_VB1_NetworkReqCondition13 "
Wakeup or Request or Keep Network Condition13
唤醒或请求或保持网络条件13
";
CM_ SG_ 1495 ZCUR_VB1_NetworkReqCondition14 "
Wakeup or Request or Keep Network Condition14
唤醒或请求或保持网络条件14
";
CM_ SG_ 1495 ZCUR_VB1_NetworkReqCondition15 "
Wakeup or Request or Keep Network Condition15
唤醒或请求或保持网络条件15
";
CM_ SG_ 1495 ZCUR_VB1_NetworkReqCondition16 "
Wakeup or Request or Keep Network Condition16
唤醒或请求或保持网络条件16
";
CM_ SG_ 1495 ZCUR_VB1_NetworkReqCondition17 "
Wakeup or Request or Keep Network Condition17
唤醒或请求或保持网络条件17
";
CM_ SG_ 1495 ZCUR_VB1_NetworkReqCondition18 "
Wakeup or Request or Keep Network Condition18
唤醒或请求或保持网络条件18
";
CM_ SG_ 1495 ZCUR_VB1_NetworkReqCondition19 "
Wakeup or Request or Keep Network Condition19
唤醒或请求或保持网络条件19
";
CM_ SG_ 1495 ZCUR_VB1_NetworkReqCondition20 "
Wakeup or Request or Keep Network Condition20
唤醒或请求或保持网络条件20
";
CM_ SG_ 1495 ZCUR_VB1_NetworkReqCondition21 "
Wakeup or Request or Keep Network Condition20
唤醒或请求或保持网络条件21
";
CM_ SG_ 1495 ZCUR_VB1_NetworkReqCondition22 "
Wakeup or Request or Keep Network Condition20
唤醒或请求或保持网络条件22
";
CM_ SG_ 1495 ZCUR_VB1_NetworkReqCondition23 "
Wakeup or Request or Keep Network Condition20
唤醒或请求或保持网络条件23
";
CM_ SG_ 1495 ZCUR_VB1_NetworkReqCondition24 "
Wakeup or Request or Keep Network Condition20
唤醒或请求或保持网络条件24
";
CM_ SG_ 1495 ZCUR_VB1_NetworkReqCondition25 "
Wakeup or Request or Keep Network Condition20
唤醒或请求或保持网络条件25
";
CM_ SG_ 1495 ZCUR_VB1_NetworkReqCondition26 "
Wakeup or Request or Keep Network Condition20
唤醒或请求或保持网络条件26
";
CM_ SG_ 1495 ZCUR_VB1_NetworkReqCondition27 "
Wakeup or Request or Keep Network Condition20
唤醒或请求或保持网络条件27
";
CM_ SG_ 1495 ZCUR_VB1_NetworkReqCondition28 "
Wakeup or Request or Keep Network Condition20
唤醒或请求或保持网络条件28
";
CM_ SG_ 1495 ZCUR_VB1_NetworkReqCondition29 "
Wakeup or Request or Keep Network Condition20
唤醒或请求或保持网络条件29
";
CM_ SG_ 1495 ZCUR_VB1_NetworkReqCondition30 "
Wakeup or Request or Keep Network Condition20
唤醒或请求或保持网络条件30
";
CM_ SG_ 1495 ZCUR_VB1_NetworkReqCondition31 "
Wakeup or Request or Keep Network Condition20
唤醒或请求或保持网络条件31
";
CM_ SG_ 431 ZCUR_FRSeatCshnAngPst_Val "

副驾座椅坐垫角度位置反馈

";
CM_ SG_ 431 ZCUR_FRLegAngCshnExtPst_Val "

副驾座椅腿托角度/坐垫延伸位置反馈

";
CM_ SG_ 431 ZCUR_FRSeatFBPst_Val "


副驾座椅前后位置反馈


";
CM_ SG_ 431 ZCUR_FRSeatBackrestPst_Val "


副驾座椅靠背位置反馈


";
CM_ SG_ 431 ZCUR_FRSeatHgtPst_Val "

副驾座椅高低位置反馈

";
CM_ SG_ 431 ZCUR_RExMirUDPst_Val "

右前外后视镜上下位置反馈


";
CM_ SG_ 431 ZCUR_RExMirLRPst_Val "

右前外后视镜左右位置反馈


";
CM_ SG_ 112 ZCUL_Checksum1 "

E2E Signal Group Checksum
Checksum is the actual value after calculation. 
E2E信号组校验和
Checksum为计算后实际值

";
CM_ SG_ 112 ZCUL_RollingCounter1 "


E2E Signal Group Counter
Counter value is automatically accumulated, added from 0 to 14 and then looped to the initial value of 0. Every time a message is sent, counter adds 1.
E2E信号组计数器
Counter值为自动累加，从0加到14，然后循环至初始值0，每次报文发送，Counter加1


";
CM_ SG_ 112 ZCUL_HzrdWngSw_St "
危险报警灯开关状态
Hazard Warning light Switch Status



";
CM_ SG_ 112 ZCUL_SFLTnLt_St "
Side Left Turn Light State 左侧后视镜转向灯状态




";
CM_ SG_ 112 ZCUL_BrakeSwNC_St "



刹车踏板常闭开关状态







";
CM_ SG_ 112 ZCUL_FLSeatOcp_St "
Front Left Seat Occupied State 主驾座椅占位








";
CM_ SG_ 112 ZCUL_BrakeSwNO_St "

 刹车踏板常开开关状态


";
CM_ SG_ 400 ZCUL_FLSeatHgtAdj_Req "

主驾座椅高低调节请求

";
CM_ SG_ 400 ZCUL_FLLthPawl_St "


左前门锁Pawl状态


";
CM_ SG_ 400 ZCUL_FLSeatCshnAngAdj_Req "


主驾座椅坐垫角度调节请求


";
CM_ SG_ 400 ZCUL_RLLthPawl_St "

左后门锁Pawl状态

";
CM_ SG_ 400 ZCUL_FLHdlOprt_St "
左前把手操作状态


";
CM_ SG_ 400 ZCUL_RLHdlOprt_St "
左后把手操作状态


";
CM_ SG_ 400 ZCUL_FLDrIntSW_St "
左前门内部按键状态


";
CM_ SG_ 400 ZCUL_RLDrIntSW_St "
左后门内部按键状态


";
CM_ SG_ 400 ZCUL_FLLthAjar_St "

左前门锁Ajar状态

";
CM_ SG_ 400 ZCUL_RLLthAjar_St "

左后门锁Ajar状态

";
CM_ SG_ 400 ZCUL_FLSeatAdj_Req "


主驾座椅前后调节请求


";
CM_ SG_ 400 ZCUL_FLLthHlfLck_St "

左前门锁HalfLock状态

";
CM_ SG_ 400 ZCUL_FLSeatBackrestAdj_Req "

主驾座椅靠背调节请求

";
CM_ SG_ 400 ZCUL_RLLthHlfLck_St "

左后门锁HalfLock状态

";
CM_ SG_ 400 ZCUL_Checksum2 "


E2E Signal Group Checksum
Checksum is the actual value after calculation. 
E2E信号组校验和
Checksum为计算后实际值


";
CM_ SG_ 400 ZCUL_RollingCounter2 "


E2E Signal Group Counter
Counter value is automatically accumulated, added from 0 to 14 and then looped to the initial value of 0. Every time a message is sent, counter adds 1.
E2E信号组计数器
Counter值为自动累加，从0加到14，然后循环至初始值0，每次报文发送，Counter加1


";
CM_ SG_ 400 ZCUL_FLSeatLegAngCshnExtAdj_Req "

 主驾座椅腿托角度/坐垫延伸调节请求


";
CM_ SG_ 400 ZCUL_SteerTiltPst_Val "


方向盘Tilt（上下）位置反馈


";
CM_ SG_ 400 ZCUL_SteerTelePst_Val "


方向盘Telescope（伸缩）位置反馈


";
CM_ SG_ 400 ZCUL_FLWinPst_Rsp "

左前车窗位置反馈




";
CM_ SG_ 400 ZCUL_RLWinPst_Rsp "




左后车窗位置反馈




";
CM_ SG_ 400 ZCUL_LExMirUDPst_Val "

左外后视镜上下位置反馈



";
CM_ SG_ 400 ZCUL_LExMirLRPst_Val "


左外后视镜左右位置反馈


";
CM_ SG_ 400 ZCUL_FLSeatFBPst_Val "


主驾座椅前后位置反馈


";
CM_ SG_ 400 ZCUL_FLSeatBackrestPst_Val "


主驾座椅靠背位置反馈


";
CM_ SG_ 400 ZCUL_FLSeatHgtPst_Val "

主驾座椅高低位置反馈

";
CM_ SG_ 400 ZCUL_FLSeatCshnAngPst_Val "

主驾座椅坐垫角度位置反馈

";
CM_ SG_ 400 ZCUL_FLLegAngCshnExtPst_Val "

主驾座椅腿托角度/坐垫延伸位置反馈

";
CM_ SG_ 896 ZCUL_FLHdl_Err "


左前把手故障信号


";
CM_ SG_ 896 ZCUL_FLHdlWork_St "


左前把手工作状态


";
CM_ SG_ 896 ZCUL_RLHdlWork_St "


左后把手工作状态


";
CM_ SG_ 896 ZCUL_RLHdl_Err "

左后把手故障信号

";
CM_ SG_ 896 ZCUL_SteerTeleLn_St "

方向盘Telescope（伸缩）学习状态

";
CM_ SG_ 896 ZCUL_SteerTiltLn_St "

方向盘Tilt（上下）学习状态

";
CM_ SG_ 896 ZCUL_SteerHtStpRsn_St "




方向盘加热停止原因




";
CM_ SG_ 896 ZCUL_SteerHt_Rsp "



方向盘加热反馈



";
CM_ SG_ 896 ZCUL_FLSeatHtStpRsn_St "




主驾座椅加热停止原因




";
CM_ SG_ 896 ZCUL_FLSeatVtlt_Rsp "



主驾座椅通风状态反馈



";
CM_ SG_ 896 ZCUL_FLSeatVtltStpRsn_St "




主驾座椅通风停止原因




";
CM_ SG_ 896 ZCUL_LExMirHt_Rsp "



左外后视镜加热状态反馈



";
CM_ SG_ 896 ZCUL_LExMirHtStpRsn_St "




左外后视镜加热停止原因




";
CM_ SG_ 896 ZCUL_FLSeatHt_Rsp "



主驾座椅加热状态反馈



";
CM_ SG_ 1408 ZCUL_PERMLVPower_Err "

ZCUL二级配电eFuse常电供电故障
每个Bit位代表一个控制器电源故障状态 0:No Fault 1:Fault

";
CM_ SG_ 1408 ZCUL_HSDLVPower_St "

 ZCUL二级配电HSD供电状态  每个Bit位代表一个控制器电源状态 0;Power Off 1:Power On

";
CM_ SG_ 1408 ZCUL_HSDLVPower_Err "

ZCUL二级配电HSD供电故障每个Bit位代表一个控制器电源故障状态 0:No Fault 1:Fault




";
CM_ SG_ 1408 ZCUL_PERMLVPower_St "
 ZCUL二级配电eFuse常电供电状态 每个Bit位代表一个控制器电源状态 0;Power Off 1:Power On 
";
CM_ SG_ 1408 ZCUL_FLHdlFrzLn_Val "

左前把手破冰学习次数

";
CM_ SG_ 1408 ZCUL_RLHdlFrzLn_Val "

左后把手破冰学习次数

";
CM_ SG_ 1408 ZCUL_FLHdlFrzLnTime_Val "

左前把手破冰学习时间

";
CM_ SG_ 1408 ZCUL_RLHdlFrzLnTime_Val "

左后把手破冰学习时间

";
CM_ SG_ 1408 ZCUL_FLSeatFBAdjLn_St "

主驾座椅前后调节电机学习状态



";
CM_ SG_ 1408 ZCUL_FLSeatBackrestAdjLn_St "

主驾座椅靠背调节电机学习状态



";
CM_ SG_ 1408 ZCUL_FLSeatHgtAdjLn_St "



主驾座椅高低调节电机学习状态



";
CM_ SG_ 1408 ZCUL_FLSeatCshnAngAdjLn_St "

主驾座椅坐垫角度调节电机学习状态



";
CM_ SG_ 1408 ZCUL_FLLegAngCshnExtLn_St "

主驾座椅腿托角度/坐垫延伸调节电机学习状态



";
CM_ SG_ 1408 ZCUL_FLWinStpRsn_St "



左前车窗停止原因



";
CM_ SG_ 1408 ZCUL_RLWinStpRsn_St "



左后车窗停止原因



";
CM_ SG_ 1408 ZCUL_FLWinStp_Req "

左前车窗停止请求


";
CM_ SG_ 1408 ZCUL_RLWinStp_Req "

左后车窗过热状态




";
CM_ SG_ 672 ZCUL_FLDrPdlLtWrk_St "

左前门踏板灯工作状态

";
CM_ SG_ 672 ZCUL_RLDrPdlLtWrk_St "

左后门踏板灯工作状态

";
CM_ SG_ 672 ZCUL_BckLtWrk_St "

 背光灯工作状态

";
CM_ SG_ 672 ZCUL_EnSvLtWrk_St "

节能灯工作状态(化妆镜灯/扶手箱灯)

";
CM_ SG_ 673 ZCUL_RLWinSw_St "
左后车窗开关状态



";
CM_ SG_ 673 ZCUL_FLWdwMov_St "
左前车窗运动状态
";
CM_ SG_ 673 ZCUL_RLHdlFrz_St "

左后把手结冰状态

";
CM_ SG_ 673 ZCUL_RLWdwMov_St "
左后车窗运动状态
";
CM_ SG_ 673 ZCUL_FLLthHome_St "

左前门锁Home状态

";
CM_ SG_ 673 ZCUL_RLLthHome_St "

左后门锁Home状态

";
CM_ SG_ 673 ZCUL_FLDrLth_St "

左前门锁状态

";
CM_ SG_ 673 ZCUL_SFLTnLtErr_St "


Side Left Turn Light Error State
左侧转向灯故障状态信号


";
CM_ SG_ 673 ZCUL_FLHdlClsPstSW_St "

左前把手关闭位置开关状态

";
CM_ SG_ 673 ZCUL_RLDrLth_St "

左后门锁状态

";
CM_ SG_ 673 ZCUL_FLDrLthWrk_St "

左前门锁工作状态

";
CM_ SG_ 673 ZCUL_RLHdlClsPstSW_St "

左后把手关闭位置开关状态

";
CM_ SG_ 673 ZCUL_FLHdlStpRsn_St "



 左前把手停止原因 



";
CM_ SG_ 673 ZCUL_FLHdlOpnPstSW_St "

左前把手打开位置开关状态

";
CM_ SG_ 673 ZCUL_RLDrLthWrk_St "

左后门锁工作状态

";
CM_ SG_ 673 ZCUL_RLHdlStpRsn_St "



 左后把手停止原因



";
CM_ SG_ 673 ZCUL_FLDrStpRsn_St "
左前门停止原因



";
CM_ SG_ 673 ZCUL_RLHdlOpnPstSW_St "

左后把手打开位置开关状态

";
CM_ SG_ 673 ZCUL_RLDrStpRsn_St "
左后门停止原因



";
CM_ SG_ 673 ZCUL_FLDrLth_Err "
左前门锁故障信号
";
CM_ SG_ 673 ZCUL_RLDrLth_Err "
左后门锁故障信号
";
CM_ SG_ 673 ZCUL_LExMirCtrl_Rsp "
左外后视镜展开折叠状态反馈
";
CM_ SG_ 673 ZCUL_HornSwitch_St "
喇叭按键状态
";
CM_ SG_ 673 ZCUL_FLHdlFrz_St "

左前把手结冰状态

";
CM_ SG_ 673 ZCUL_FLDrStpRsn2_St "


 左前门停止原因2 


";
CM_ SG_ 673 ZCUL_FLDrLthWrk2_St "

 左前门锁工作状态2

";
CM_ SG_ 673 ZCUL_RLDrStpRsn2_St "

左后门停止原因2

";
CM_ SG_ 673 ZCUL_RLDrLthWrk2_St "

 左后门锁工作状态2

";
CM_ SG_ 673 ZCUL_FLLumbSuppUDAdj_Req "

主驾座椅腰托上下调节请求

";
CM_ SG_ 673 ZCUL_FLSunshadeSW_St "

左前遮阳板开关状态

";
CM_ SG_ 673 ZCUL_FLLumbSuppFBAdj_Req "

主驾座椅腰托前后调节请求

";
CM_ SG_ 673 ZCUL_FLDrLth2_Err "

左前门锁故障信号2

";
CM_ SG_ 673 ZCUL_RLDrLth2_Err "

左后门锁故障信号2

";
CM_ SG_ 673 ZCUL_SteerTiltMv_St "


方向盘Tilt（上下）运动状态


";
CM_ SG_ 673 ZCUL_SteerTeleMv_St "


方向盘Telescope（伸缩）运动状态


";
CM_ SG_ 673 ZCUL_SteerTiltStpRsn_St "
方向盘Tilt（上下）Tilt停止原因



";
CM_ SG_ 673 ZCUL_SteerTiltStp_Req "
方向盘Tilt（上下）停止请求


";
CM_ SG_ 673 ZCUL_SteerTeleStpRsn_St "
方向盘Telescope（伸缩）停止原因



";
CM_ SG_ 673 ZCUL_SteerTeleStp_Req "


方向盘Telescope（伸缩）停止请求


";
CM_ SG_ 673 ZCUL_LExMirUDMv_St "


左外后视镜上下运动状态


";
CM_ SG_ 673 ZCUL_LExMirLRMv_St "


左外后视镜左右运动状态


";
CM_ SG_ 673 ZCUL_LExMirUDStpRsn_St "
左外后视镜上下停止原因



";
CM_ SG_ 673 ZCUL_LExMirUDStp_Req "


左外后视镜上下停止请求


";
CM_ SG_ 673 ZCUL_LExMirLRStpRsn_St "
左外后视镜左右停止原因



";
CM_ SG_ 673 ZCUL_LExMirLRStp_Req "


左外后视镜左右停止请求


";
CM_ SG_ 673 ZCUL_FLSeatCshnAngStpRsn_St "
主驾座椅坐垫角度停止原因



";
CM_ SG_ 673 ZCUL_FLSeatCshnAngStp_Req "
主驾座椅坐垫角度停止请求


";
CM_ SG_ 673 ZCUL_FLLegAngCshnExtStpRsn_St "
主驾座椅腿托角度/坐垫延伸停止原因



";
CM_ SG_ 673 ZCUL_FLLegAngCshnExtStp_Req "
主驾座椅腿托角度/坐垫延伸停止请求



";
CM_ SG_ 673 ZCUL_FLSeatFBMv_St "


主驾座椅前后运动状态


";
CM_ SG_ 673 ZCUL_FLSeatBackrestMv_St "


主驾座椅靠背运动状态


";
CM_ SG_ 673 ZCUL_FLSeatHgtMv_St "

主驾座椅高低运动状态

";
CM_ SG_ 673 ZCUL_FLSeatCshnAngMv_St "

主驾座椅坐垫角度运动状态

";
CM_ SG_ 673 ZCUL_FLLegAngCshnExtMv_St "

主驾座椅腿托角度/坐垫延伸运动状态

";
CM_ SG_ 673 ZCUL_FLSeatFBStpRsn_St "
主驾座椅前后停止原因



";
CM_ SG_ 673 ZCUL_FLSeatFBStp_Req "
主驾座椅前后停止请求


";
CM_ SG_ 673 ZCUL_FLSeatBackrestStpRsn_St "
主驾座椅靠背停止原因



";
CM_ SG_ 673 ZCUL_FLSeatBackrestStp_Req "
主驾座椅靠背停止请求


";
CM_ SG_ 673 ZCUL_FLSeatHgtStpRsn_St "
主驾座椅高低停止原因



";
CM_ SG_ 673 ZCUL_FLSeatHgtStp_Req "


主驾座椅高低停止请求


";
CM_ SG_ 673 ZCUL_FLHdlDbOprt_St "

左前把手双拉操作

";
CM_ SG_ 673 ZCUL_RLHdlDbOprt_St "

左后把手双拉操作

";
CM_ SG_ 673 ZCUL_LExMirCtrlMv_St "

左外后视镜展开折叠运动状态

";
CM_ SG_ 673 ZCUL_LExMirCtrlStpRsn_St "
左外后视镜展开折叠停止原因


";
CM_ SG_ 673 ZCUL_LExMirCtrlStp_Req "


左外后视镜展开折叠停止请求


";
CM_ SG_ 401 SWSR_TouchPadDownSw_St "

 方向盘右侧ToachPad向下按键状态


";
CM_ SG_ 401 SWSR_TouchPadLeftSw_St "

 方向盘右侧ToachPad向左按键状态


";
CM_ SG_ 401 SWSR_TouchPadRightSw_St "

 方向盘右侧ToachPad向右按键状态


";
CM_ SG_ 401 SWSR_TouchPadUpSw_St "

 方向盘右侧ToachPad向上按键状态


";
CM_ SG_ 401 DISFL_FRWinCtl_Req "

 右前车窗控制请求


";
CM_ SG_ 401 DISFL_RLWinCtl_Req "

 左后车窗控制请求


";
CM_ SG_ 401 DISFL_RRWinCtl_Req "

 右后车窗控制请求


";
CM_ SG_ 401 DISFL_DrvCtLckSW_Req "
 Driver Ctrl Lock Switch Request主驾侧中控锁开关请求 
";
CM_ SG_ 401 DISFL_FLWinCtl_Req "

 左前车窗控制请求


";
CM_ SG_ 401 TL_FLTpLtClr_St "

 左前顶灯色温状态

";
CM_ SG_ 401 TL_RLTpLtClr_St "

 左后顶灯色温状态

";
CM_ SG_ 401 TL_FRTpLtClr_St "

 右前顶灯色温状态

";
CM_ SG_ 401 TL_RRTpLtClr_St "

 右后顶灯色温状态


";
CM_ SG_ 401 TL_FLTchBtn_St "
 左前顶灯触摸按键状态
";
CM_ SG_ 401 TL_FLTpLtBrt_Val "
 左前顶灯亮度
";
CM_ SG_ 401 TL_RLTchBtn_St "
 左后顶灯触摸按键状态
";
CM_ SG_ 401 TL_RLTpLtBrt_Val "
 左后顶灯亮度
";
CM_ SG_ 401 TL_FRTchBtn_St "
 右前顶灯触摸按键状态
";
CM_ SG_ 401 TL_FRTpLtBrt_Val "
 右前顶灯亮度
";
CM_ SG_ 401 TL_RRTchBtn_St "
 右后顶灯触摸按键状态
";
CM_ SG_ 401 TL_RRTpLtBrt_Val "
 右后顶灯亮度
";
CM_ SG_ 401 ZCUL_FD_RT_1_SWSRAvailable_St "

If signals which route from SWSR in message ZCUL_FD_RT_1 are available
报文ZCUL_FD_RT_1中路由的SWSR节点的信号是否可信

";
CM_ SG_ 401 ZCUL_FD_RT_1_DISFLAvailable_St "

If signals which route from DISFL in message ZCUL_FD_RT_1 are available
报文ZCUL_FD_RT_1中路由的DISFL节点的信号是否可信

";
CM_ SG_ 401 ZCUL_FD_RT_1_TLAvailable_St "

If signals which route from TL in message ZCUL_FD_RT_1 are available
报文ZCUL_FD_RT_1中路由的TL节点的信号是否可信

";
CM_ SG_ 403 CSM_FwiperSW_St "

 前雨刮开关


";
CM_ SG_ 403 CSM_TurnLightSw_St "
 转向灯开关状态

";
CM_ SG_ 403 CSM_FMistWashSW_St "
 前雨刮点动及洗涤开关

";
CM_ SG_ 403 CSM_HighBeamSw_St "
 远光灯开关状态

";
CM_ SG_ 403 CSM_Checksum1 "


E2E Signal Group Checksum
Checksum is the actual value after calculation. 
E2E信号组校验和
Checksum为计算后实际值


";
CM_ SG_ 403 CSM_RollingCounter1 "


E2E Signal Group Counter
Counter value is automatically accumulated, added from 0 to 14 and then looped to the initial value of 0. Every time a message is sent, counter adds 1.
E2E信号组计数器
Counter值为自动累加，从0加到14，然后循环至初始值0，每次报文发送，Counter加1


";
CM_ SG_ 403 CSM_FWiperLO_Err "

Front Wiper Low error
 前雨刮Low档开关错误

";
CM_ SG_ 403 CSM_FWiperHI_Err "


Front Wiper Hight error
 前雨刮Hight档开关错误


";
CM_ SG_ 403 CSM_FMistSW_Err "

Inching switch error
 点动开关错误

";
CM_ SG_ 403 CSM_FWashSW_Err "

Front Wash Switch error
 前洗涤开关错误

";
CM_ SG_ 403 CSM_FWiperOFF_Err "

Front Wiper OFF error
 前雨刮OFF档开关错误

";
CM_ SG_ 403 CSM_FWiperAuto1_Err "
 Front Wiper INT1 error
前雨刮INT1档开关错误 
";
CM_ SG_ 403 CSM_FWiperAuto2_Err "
 Front Wiper INT1 error
前雨刮INT2档开关错误 
";
CM_ SG_ 1482 ZCUL_VB1_NetworkReqCondition0 "
Wakeup or Request or Keep Network Condition0
唤醒或请求或保持网络条件1
";
CM_ SG_ 1482 ZCUL_VB1_NetworkReqCondition1 "
Wakeup or Request or Keep Network Condition1
唤醒或请求或保持网络条件1
";
CM_ SG_ 1482 ZCUL_VB1_NetworkReqCondition2 "
Wakeup or Request or Keep Network Condition2
唤醒或请求或保持网络条件2
";
CM_ SG_ 1482 ZCUL_VB1_NetworkReqCondition3 "
Wakeup or Request or Keep Network Condition3
唤醒或请求或保持网络条件3
";
CM_ SG_ 1482 ZCUL_VB1_NetworkReqCondition4 "
Wakeup or Request or Keep Network Condition4
唤醒或请求或保持网络条件4
";
CM_ SG_ 1482 ZCUL_VB1_NetworkReqCondition5 "
Wakeup or Request or Keep Network Condition5
唤醒或请求或保持网络条件5
";
CM_ SG_ 1482 ZCUL_VB1_NetworkReqCondition6 "
Wakeup or Request or Keep Network Condition6
唤醒或请求或保持网络条件6
";
CM_ SG_ 1482 ZCUL_VB1_NetworkReqCondition7 "
Wakeup or Request or Keep Network Condition7
唤醒或请求或保持网络条件7
";
CM_ SG_ 1482 ZCUL_VB1_NetworkReqCondition8 "
Wakeup or Request or Keep Network Condition8
唤醒或请求或保持网络条件8
";
CM_ SG_ 1482 ZCUL_VB1_NetworkReqCondition9 "
Wakeup or Request or Keep Network Condition9
唤醒或请求或保持网络条件9
";
CM_ SG_ 1482 ZCUL_VB1_NetworkReqCondition10 "
Wakeup or Request or Keep Network Condition10
唤醒或请求或保持网络条件10
";
CM_ SG_ 1482 ZCUL_VB1_NetworkReqCondition11 "
Wakeup or Request or Keep Network Condition11
唤醒或请求或保持网络条件11
";
CM_ SG_ 1482 ZCUL_VB1_NetworkReqCondition12 "
Wakeup or Request or Keep Network Condition12
唤醒或请求或保持网络条件12
";
CM_ SG_ 1482 ZCUL_VB1_NetworkReqCondition13 "
Wakeup or Request or Keep Network Condition13
唤醒或请求或保持网络条件13
";
CM_ SG_ 1482 ZCUL_VB1_NetworkReqCondition14 "
Wakeup or Request or Keep Network Condition14
唤醒或请求或保持网络条件14
";
CM_ SG_ 1482 ZCUL_VB1_NetworkReqCondition15 "
Wakeup or Request or Keep Network Condition15
唤醒或请求或保持网络条件15
";
CM_ SG_ 1482 ZCUL_VB1_NetworkReqCondition16 "
Wakeup or Request or Keep Network Condition16
唤醒或请求或保持网络条件16
";
CM_ SG_ 1482 ZCUL_VB1_NetworkReqCondition17 "
Wakeup or Request or Keep Network Condition17
唤醒或请求或保持网络条件17
";
CM_ SG_ 1482 ZCUL_VB1_NetworkReqCondition18 "
Wakeup or Request or Keep Network Condition18
唤醒或请求或保持网络条件18
";
CM_ SG_ 1482 ZCUL_VB1_NetworkReqCondition19 "
Wakeup or Request or Keep Network Condition19
唤醒或请求或保持网络条件19
";
CM_ SG_ 1482 ZCUL_VB1_NetworkReqCondition20 "
Wakeup or Request or Keep Network Condition20
唤醒或请求或保持网络条件20
";
CM_ SG_ 1482 ZCUL_VB1_NetworkReqCondition21 "
Wakeup or Request or Keep Network Condition20
唤醒或请求或保持网络条件21
";
CM_ SG_ 1482 ZCUL_VB1_NetworkReqCondition22 "
Wakeup or Request or Keep Network Condition20
唤醒或请求或保持网络条件22
";
CM_ SG_ 1482 ZCUL_VB1_NetworkReqCondition23 "
Wakeup or Request or Keep Network Condition20
唤醒或请求或保持网络条件23
";
CM_ SG_ 1482 ZCUL_VB1_NetworkReqCondition24 "
Wakeup or Request or Keep Network Condition20
唤醒或请求或保持网络条件24
";
CM_ SG_ 1482 ZCUL_VB1_NetworkReqCondition25 "
Wakeup or Request or Keep Network Condition20
唤醒或请求或保持网络条件25
";
CM_ SG_ 1482 ZCUL_VB1_NetworkReqCondition26 "
Wakeup or Request or Keep Network Condition20
唤醒或请求或保持网络条件26
";
CM_ SG_ 1482 ZCUL_VB1_NetworkReqCondition27 "
Wakeup or Request or Keep Network Condition20
唤醒或请求或保持网络条件27
";
CM_ SG_ 1482 ZCUL_VB1_NetworkReqCondition28 "
Wakeup or Request or Keep Network Condition20
唤醒或请求或保持网络条件28
";
CM_ SG_ 1482 ZCUL_VB1_NetworkReqCondition29 "
Wakeup or Request or Keep Network Condition20
唤醒或请求或保持网络条件29
";
CM_ SG_ 1482 ZCUL_VB1_NetworkReqCondition30 "
Wakeup or Request or Keep Network Condition20
唤醒或请求或保持网络条件30
";
CM_ SG_ 1482 ZCUL_VB1_NetworkReqCondition31 "
Wakeup or Request or Keep Network Condition20
唤醒或请求或保持网络条件31
";
CM_ SG_ 1415 ZCUL_WakeupReq_HDBT " Signal Description: Wakeup HDBT domain-related ECU flag bits, each bit represents an ECU, the correspondence between bit and ECU refers to Sleep Wakeup List 唤醒HDBT域相关ECU标志位，每一bit位代表一个ECU，具体bit与ECU的对应关系见休眠唤醒列表。 ";
CM_ SG_ 1415 ZCUL_WakeupReq_HDBI " Signal Description: Wakeup HDBI domain-related ECU flag bits, each bit represents an ECU, the correspondence between bit and ECU refers to Sleep Wakeup List 唤醒HDBI域相关ECU标志位，每一bit位代表一个ECU，具体bit与ECU的对应关系见休眠唤醒列表。 ";
CM_ SG_ 1415 ZCUL_WakeupReq_HDBA " Wakeup HDBA domain-related ECU flag bits, each bit represents an ECU, the correspondence between bit and ECU refers to Sleep Wakeup List 唤醒HDBA域相关ECU标志位，每一bit位代表一个ECU，具体bit与ECU的对应关系见休眠唤醒列表。 ";
CM_ SG_ 1415 ZCUL_WakeupReq_HDBM " Signal Description: Wakeup HDBM domain-related ECU flag bits, each bit represents an ECU, the correspondence between bit and ECU refers to Sleep Wakeup List 唤醒HDBM域相关ECU标志位，每一bit位代表一个ECU，具体bit与ECU的对应关系见休眠唤醒列表。 ";
CM_ SG_ 1415 ZCUL_WakeupReq_ZCUF " Signal Description: Wakeup ZCUF domain-related ECU flag bits, each bit represents an ECU, the correspondence between bit and ECU refers to Sleep Wakeup List 唤醒ZCUF域相关ECU标志位，每一bit位代表一个ECU，具体bit与ECU的对应关系见休眠唤醒列表。 ";
CM_ SG_ 1415 ZCUL_WakeupReq_ZCUL " Signal Description: Wakeup ZCUL domain-related ECU flag bits, each bit represents an ECU, the correspondence between bit and ECU refers to Sleep Wakeup List 唤醒ZCUL域相关ECU标志位，每一bit位代表一个ECU，具体bit与ECU的对应关系见休眠唤醒列表。 ";
CM_ SG_ 1415 ZCUL_WakeupReq_ZCUR " Signal Description: Wakeup ZCUR domain-related ECU flag bits, each bit represents an ECU, the correspondence between bit and ECU refers to Sleep Wakeup List 唤醒ZCUR域相关ECU标志位，每一bit位代表一个ECU，具体bit与ECU的对应关系见休眠唤醒列表。 ";
CM_ SG_ 1415 ZCUL_WakeupReq_ZCUT " Signal Description: Wakeup ZCUT domain-related ECU flag bits, each bit represents an ECU, the correspondence between bit and ECU refers to Sleep Wakeup List 唤醒ZCUT域相关ECU标志位，每一bit位代表一个ECU，具体bit与ECU的对应关系见休眠唤醒列表。 ";
CM_ SG_ 1107 ZCUL_NodeAddress_VB1 "
Node source address
节点源地址
";
CM_ SG_ 1107 ZCUL_RepeatMsgReq_VB1 "
Repeat Message Request Bit
重复报文请求位
";
CM_ SG_ 1107 ZCUL_ActiveWakeup_VB1 "
Active Wakeup Bit
主动唤醒指示位
";
CM_ SG_ 1107 ZCUL_PartialNetworkInfo_VB1 "
Partial Network Information Bit
部分网络管理信息指示位
";
CM_ SG_ 1107 ZCUL_RepeatMsgSt_VB1 "
Repeat Message State indication
节点处在重复报文状态指示位
";
CM_ SG_ 1107 ZCUL_PN_HDBT_VB1 "
Wakeup Target ECU requirement flag
唤醒目标ECU需求标志
";
CM_ SG_ 1107 ZCUL_PN_HDBI_VB1 "
Wakeup Target ECU requirement flag
唤醒目标ECU需求标志
";
CM_ SG_ 1107 ZCUL_PN_HDBA_VB1 "
Wakeup Target ECU requirement flag
唤醒目标ECU需求标志
";
CM_ SG_ 1107 ZCUL_PN_HDBM_VB1 "
Wakeup Target ECU requirement flag
唤醒目标ECU需求标志
";
CM_ SG_ 1107 ZCUL_PN_ZCUF_VB1 "
Wakeup Target ECU requirement flag
唤醒目标ECU需求标志
";
CM_ SG_ 1107 ZCUL_PN_ZCUL_VB1 "
Wakeup Target ECU requirement flag
唤醒目标ECU需求标志
";
CM_ SG_ 1107 ZCUL_PN_ZCUR_VB1 "
Wakeup Target ECU requirement flag
唤醒目标ECU需求标志
";
CM_ SG_ 1107 ZCUL_PN_ZCUT_VB1 "
Wakeup Target ECU requirement flag
唤醒目标ECU需求标志
";
CM_ SG_ 320 ZCUF_RegenPwrPct_Val "
Electric brake power percent
电制动功率百分比
";
CM_ SG_ 320 ZCUF_CurrActlDrvPwr_Val "
Current actual Driving electric power
 当前实际驱动电功率
";
CM_ SG_ 320 ZCUF_FWiperParkAreaSW_St "


前雨刮回位开关状态


";
CM_ SG_ 320 ZCUF_CurrActlBrakePwr_Val "
Current actual brake power
 当前实际制动电功率
";
CM_ SG_ 320 ZCUF_CurrLimitDrivePwrPct_Val "
Current Limit Drive Power Percent
可用驱动功率和最大可用驱动功率的比值
";
CM_ SG_ 320 ZCUF_CurrLimitBrakePwrPct_Val "
Current Limit Brake Power Percent
可用回收功率和最大可用回收功率的比值
";
CM_ SG_ 528 ZCUF_ACTotLimPwr_Val "
ZCUR high voltage total limited power
 空调系统高压限制总功率
";
CM_ SG_ 528 ZCUF_ECFActualSpdPct_Val " 冷却风扇转速百分比
";
CM_ SG_ 528 ZCUF_EcfFlt_St "
冷却风扇故障状态
";
CM_ SG_ 528 ZCUF_FLHighLgt_St " Left High Beam Light State Response 左前远光灯状态";
CM_ SG_ 528 ZCUF_FRHighLgt_St " Right High Beam Light State Response 右前远光灯状态";
CM_ SG_ 528 ZCUF_StdSenarioMileage_Val "
Standard Senario Mileage
标准工况续航里程
";
CM_ SG_ 528 ZCUF_RESSInletTargTemp_Req "

RESS inlet target temperature 电池进水口目标温度

";
CM_ SG_ 528 ZCUF_Ready_St "
Ready sign (for general)
Ready信号(通用Ready信号)
";
CM_ SG_ 528 ZCUF_PackThmlMode_Req "

电池包热管理模式请求

";
CM_ SG_ 528 ZCUF_HighVoltage_St "

High voltage power-on
高压上电完成状态

";
CM_ SG_ 528 ZCUF_AGSFaultSt_Err "
AGS故障状态
";
CM_ SG_ 528 ZCUF_AGSActAng_Val "
AGS实际开启角度
";
CM_ SG_ 528 ZCUF_TractionModeSet_Rsp "


Traction Mode Setting Response
ZCUF Traction Mode设置反馈信号


";
CM_ SG_ 528 ZCUF_FLTnLgtErr_St "


Front Left Turn Light State 左前转向灯故障状态


";
CM_ SG_ 528 ZCUF_FRTnLgtErr_St "


Front Right Turn Light State 右前转向灯故障状态


";
CM_ SG_ 528 ZCUF_Checksum5 "

E2E Signal Group Checksum
Checksum is the actual value after calculation. 
E2E信号组校验和
Checksum为计算后实际值

";
CM_ SG_ 528 ZCUF_RollingCounter5 "



E2E Signal Group Counter
Counter value is automatically accumulated, added from 0 to 14 and then looped to the initial value of 0. Every time a message is sent, counter adds 1.
E2E信号组计数器
Counter值为自动累加，从0加到14，然后循环至初始值0，每次报文发送，Counter加1



";
CM_ SG_ 528 ZCUF_CoolSysInletTemp_Val "

Cooling system inlet tempterature
冷却系统入口温度

";
CM_ SG_ 528 ZCUF_CoolSysOutletTemp_Val "

Cooling system outlet tempterature
冷却系统出口温度

";
CM_ SG_ 1424 ZCUF_HSDLVPower_St "

 ZCUF二级配电HSD供电状态  每个Bit位代表一个控制器电源状态 0;Power Off 1:Power On

";
CM_ SG_ 1424 ZCUF_HSDLVPower_Err "

ZCUF二级配电HSD供电故障
每个Bit位代表一个控制器电源故障状态 0:No Fault 1:Fault



";
CM_ SG_ 1424 ZCUF_PERMLVPower_St "
 ZCUF二级配电eFuse常电供电状态 每个Bit位代表一个控制器电源状态 0;Power Off 1:Power On 
";
CM_ SG_ 1424 ZCUF_PERMLVPower_Err "

ZCUF二级配电eFuse常电供电故障
每个Bit位代表一个控制器电源故障状态 0:No Fault 1:Fault
";
CM_ SG_ 1424 ZCUF_AvgEnergyConsume_Val "

Vehicle Average energy consumption
整车平均能耗

";
CM_ SG_ 513 ZCUF_AbnormalShiftInfo_Err "
Abnormal Shift Information
异常换挡信号
";
CM_ SG_ 513 ZCUF_ThmlRunawayWarn_St "

Thermal Runaway Warn Status 热失控报警状态

";
CM_ SG_ 513 ZCUF_Shift_Err "


EGSM fault
换挡器故障


";
CM_ SG_ 513 ZCUF_PullOver_St "
Pull over alert status 靠边停车提示状态
";
CM_ SG_ 513 ZCUF_BrakeLightOn_Req "
Brake Light Turn On Request
点亮刹车灯请求
";
CM_ SG_ 513 ZCUF_HVOffConfirm_Req "
Emergency switch off request
紧急开关下电请求确认
";
CM_ SG_ 513 ZCUF_PTFaultLgtClr_St "
Powertrain System Fault Light Color
PT系统故障灯颜色
";
CM_ SG_ 513 ZCUF_AntiTheft_St "
Anti-theft Status
防盗状态
";
CM_ SG_ 513 ZCUF_LowVoltSys_Err "
Low voltage system error 
低压系统故障
";
CM_ SG_ 513 ZCUF_MotorOverTemp_St "

ZCUF基于车辆配置对MCUF和MCUR的电机过温报警进行汇总

";
CM_ SG_ 513 ZCUF_PTHMI_Req "
PT HMI requesst PT HMI请求（不同bit位代表不同提示需求，对应bit位值为1代表请求，为0代表无请求） bit0:低充电功率提醒
bit1:当前AGS异常，请及时检查
bit2:同时踩下两个踏板提示电机功率下降
bit3:低SOC可能无法驾驶提示
bit4:12V小电池（后）需要检修
bit5:12V小电池（前）需要检修
bit6:低温低SOP时仪表提示预热
bit7:冬季或高SOC能量回收弱提示";
CM_ SG_ 513 ZCUF_EDCDisTemp_Val "

压缩机出口温度原始值

";
CM_ SG_ 513 ZCUF_EDCSuncPres_Val "

压缩机入口压力

";
CM_ SG_ 513 ZCUF_EDCSuncTemp_Val "

压缩机入口温度

";
CM_ SG_ 513 ZCUF_EDCDisPres_Val "

压缩机出口压力原始值

";
CM_ SG_ 513 ZCUF_TAmbOrig_Val "

车外温度原始值

";
CM_ SG_ 513 ZCUF_EEMSetPowerLevel_St "

Request for EEM setting power level
EEM能量等级反馈

";
CM_ SG_ 880 ZCUF_ACMEnable_Req "
空调系统高压部件使能
";
CM_ SG_ 880 ZCUF_FLLowLgt_St " Left Low Beam Light State Response 左前近光灯状态";
CM_ SG_ 880 ZCUF_FRLowLgt_St " Right Low Beam Light State Response 右前近光灯状态";
CM_ SG_ 880 ZCUF_HoodAjar_St "
前舱盖全锁信号
";
CM_ SG_ 880 ZCUF_DriveConflictRemindInfo_UI "

Driving conflict tips
驾驶冲突提示

";
CM_ SG_ 880 ZCUF_FLPstnLgt_St " Front Left Position Light State 左前位置灯状态";
CM_ SG_ 880 ZCUF_FRPstnLgt_St " Front Right Position Light State 右前位置灯状态";
CM_ SG_ 880 ZCUF_PTworkmode_St "

PT Map Status
PT Map状态

";
CM_ SG_ 880 ZCUF_PtModAvailable_St "

PT Map Available

";
CM_ SG_ 880 ZCUF_RegenSetPct_Rsp "
Regen setting percent response
再生制动设置反馈
";
CM_ SG_ 880 ZCUF_Fwiper_St "


雨刮运行状态反馈


";
CM_ SG_ 880 ZCUF_ServiceReminder_St "
Service Reminder Status
维修提示状态
";
CM_ SG_ 880 ZCUF_HoodHalfOrPawl_St "
前舱盖半锁或棘爪信号
";
CM_ SG_ 880 ZCUF_TractionModeAvail_St "
Traction Mode Available Status
Traction Mode可用状态
";
CM_ SG_ 880 ZCUF_TractionModeRemaind_St "
TractionModeRemaind
拖车模式提醒
";
CM_ SG_ 880 ZCUF_FLDyLgt_St " 左前日行灯状态";
CM_ SG_ 880 ZCUF_FRDyLgt_St " 右前日行灯状态";
CM_ SG_ 880 ZCUF_LowBattChrgForbid_St "


Low Battery Charge Forbid Status
动力电池给小电池充电禁用状态位


";
CM_ SG_ 880 ZCUF_PTThmlLiquidLackWarn_St "

PT thermal management circuit coolant level low warn
PT热管理回路冷却液液位低报警

";
CM_ SG_ 880 ZCUF_RegenAvail_St " Energy recovery available status 能量回收可用状态";
CM_ SG_ 880 ZCUF_LowVoltSysWarnStop_St "
Low voltage system error ，can not travl for long time，please stop vehicel immediately
低压系统故障，无法长时间行驶，请立即停车文字提醒

";
CM_ SG_ 880 ZCUF_EmergencyLgtOn_Req "

Emergency Light Turn On Request
紧急制动灯点亮请求

";
CM_ SG_ 880 ZCUF_HoodLatch_St "

前舱盖锁状态信号

";
CM_ SG_ 880 ZCUF_WashLqdHgtSW_St "
 洗涤液位开关状态
";
CM_ SG_ 97 EHBM_FLWhlPulse_Val "

Front left wheel speed pulse in 10ms(raw data)
左前轮轮速脉冲(原始数据)

";
CM_ SG_ 97 EHBM_FRWhlPulse_Val "

Front left wheel speed pulse in 10ms(raw data)
右前轮轮速脉冲(原始数据)

";
CM_ SG_ 97 EHBM_RLWhlPulse_Val "

Rear left wheel speed pulse in 10ms(raw data)
左后轮轮速脉冲(原始数据)

";
CM_ SG_ 97 EHBM_RRWhlPulse_Val "

Rear Right wheel speed pulse in 10ms(raw data)
右后轮轮速脉冲(原始数据)

";
CM_ SG_ 97 EHBM_FLWhlPulseValid_St "


Check the Stity of the front left wheel pulse
左前轮轮速脉冲有效位


";
CM_ SG_ 97 EHBM_FRWhlPulseValid_St "


Check the Stity of the front right wheel pulse
右前轮轮速脉冲有效位


";
CM_ SG_ 97 EHBM_RLWhlPulseValid_St "


Check the Stity of the rear left wheel pulse
左后轮轮速脉冲有效位


";
CM_ SG_ 97 EHBM_RRWhlPulseValid_St "


Check the Stity of the rear right wheel pulse
右后轮轮速脉冲有效位


";
CM_ SG_ 97 ZCUF_FD_RT_1_EHBMAvailable_St "
If signals which route from EHBM in message ZCUF_FD_RT_1 areavailable
报文ZCUF_FD_RT_1中路由的EHBM节点的信号是否可信
";
CM_ SG_ 448 ACCM_ZCUFMissing_St "


压缩机与ZCUF通讯丢失


";
CM_ SG_ 448 ACCM_VDC_Val "
压缩机母线电压
";
CM_ SG_ 448 ACCM_UvP_St "

吸气压力过低

";
CM_ SG_ 448 ACCM_UnderHV_St "

高压欠压

";
CM_ SG_ 448 ACCM_TempSensorError "


压缩机温度传感器故障


";
CM_ SG_ 448 ACCM_St "



压缩机运行状态



";
CM_ SG_ 448 ACCM_Speed_Val "
压缩机当前实际速度
";
CM_ SG_ 448 ACCM_SIC_Err "


压缩机SIC故障


";
CM_ SG_ 448 ACCM_Power_Val "
压缩机当前运行功率
";
CM_ SG_ 448 ACCM_PISaturation_St "


压缩机速度环PI饱和


";
CM_ SG_ 448 ACCM_PhaseCurrent_Val "
相电流过大
";
CM_ SG_ 448 ACCM_OvPd_St "

排气压力过高

";
CM_ SG_ 448 ACCM_OverPower_St "


压缩机功率过大


";
CM_ SG_ 448 ACCM_Overload_St "


压缩机过载


";
CM_ SG_ 448 ACCM_OverIPMTemp_St "

IPM温度过高

";
CM_ SG_ 448 ACCM_OverHV_St "


高压过压


";
CM_ SG_ 448 ACCM_OverDuty_St "


压缩机丢步


";
CM_ SG_ 448 ACCM_LvUv_St "


压缩机低压欠压


";
CM_ SG_ 448 ACCM_LvOv_St "


压缩机低压过压


";
CM_ SG_ 448 ACCM_LoseStep_St "

失步保护

";
CM_ SG_ 448 ACCM_IPMTemperature_Val "
压缩机模块温度
";
CM_ SG_ 448 ACCM_HVLoop_St "
压缩机高压互锁信号
";
CM_ SG_ 448 ACCM_HardProtection_St "

硬件保护

";
CM_ SG_ 448 ACCM_FreqLimitcode_Spec "
压缩机频率限制代码
";
CM_ SG_ 448 ACCM_DriveVoltageUV_St "


压缩机高压过压


";
CM_ SG_ 448 ACCM_DriveVoltageOV_St "


压缩机高压欠压


";
CM_ SG_ 448 ACCM_DCCurrent_Val "
压缩机电流
";
CM_ SG_ 448 ACCM_ControllerTemp_Val "
压缩机控制器温度
";
CM_ SG_ 448 ACCM_Busoff_Err "

通信故障

";
CM_ SG_ 225 ERPB_OperationReminder_UI "

 EPB operation reminder EPB操作提醒 


";
CM_ SG_ 225 ERPB_EPBFunctionLamp_St "
EPB functon lamp status, dashboard receive this signal to illuminate the function lamp
EPB功能指示灯状态,仪表接收到该信号后需点亮功能灯
";
CM_ SG_ 225 ERPB_EPBFailLamp_St "
EPB failure lamp status, dashboard receive this signal to illuminate the failure lamp
EPB故障指示灯,仪表接收到该信号后需点亮故障灯
";
CM_ SG_ 225 ERPB_EPB_St " Status of EPB system EPB系统状态 
";
CM_ SG_ 225 ERPB_CapacityLimitWarn_UI "
 EPB Capacity Limit Warn EPB能力限制警告 

";
CM_ SG_ 225 ERPB_BrakeLight_Req "


EPB请求点亮制动尾灯


";
CM_ SG_ 1476 ZCUF_VB1_NetworkReqCondition0 "

Wakeup or Request or Keep Network Condition0
唤醒或请求或保持网络条件1

";
CM_ SG_ 1476 ZCUF_VB1_NetworkReqCondition1 "

Wakeup or Request or Keep Network Condition1
唤醒或请求或保持网络条件1

";
CM_ SG_ 1476 ZCUF_VB1_NetworkReqCondition2 "

Wakeup or Request or Keep Network Condition2
唤醒或请求或保持网络条件2

";
CM_ SG_ 1476 ZCUF_VB1_NetworkReqCondition3 "

Wakeup or Request or Keep Network Condition3
唤醒或请求或保持网络条件3

";
CM_ SG_ 1476 ZCUF_VB1_NetworkReqCondition4 "

Wakeup or Request or Keep Network Condition4
唤醒或请求或保持网络条件4

";
CM_ SG_ 1476 ZCUF_VB1_NetworkReqCondition5 "

Wakeup or Request or Keep Network Condition5
唤醒或请求或保持网络条件5

";
CM_ SG_ 1476 ZCUF_VB1_NetworkReqCondition6 "

Wakeup or Request or Keep Network Condition6
唤醒或请求或保持网络条件6

";
CM_ SG_ 1476 ZCUF_VB1_NetworkReqCondition7 "

Wakeup or Request or Keep Network Condition7
唤醒或请求或保持网络条件7

";
CM_ SG_ 1476 ZCUF_VB1_NetworkReqCondition8 "

Wakeup or Request or Keep Network Condition8
唤醒或请求或保持网络条件8

";
CM_ SG_ 1476 ZCUF_VB1_NetworkReqCondition9 "

Wakeup or Request or Keep Network Condition9
唤醒或请求或保持网络条件9

";
CM_ SG_ 1476 ZCUF_VB1_NetworkReqCondition10 "

Wakeup or Request or Keep Network Condition10
唤醒或请求或保持网络条件10

";
CM_ SG_ 1476 ZCUF_VB1_NetworkReqCondition11 "

Wakeup or Request or Keep Network Condition11
唤醒或请求或保持网络条件11

";
CM_ SG_ 1476 ZCUF_VB1_NetworkReqCondition12 "

Wakeup or Request or Keep Network Condition12
唤醒或请求或保持网络条件12

";
CM_ SG_ 1476 ZCUF_VB1_NetworkReqCondition13 "

Wakeup or Request or Keep Network Condition13
唤醒或请求或保持网络条件13

";
CM_ SG_ 1476 ZCUF_VB1_NetworkReqCondition14 "

Wakeup or Request or Keep Network Condition14
唤醒或请求或保持网络条件14

";
CM_ SG_ 1476 ZCUF_VB1_NetworkReqCondition15 "

Wakeup or Request or Keep Network Condition15
唤醒或请求或保持网络条件15

";
CM_ SG_ 1476 ZCUF_VB1_NetworkReqCondition16 "

Wakeup or Request or Keep Network Condition16
唤醒或请求或保持网络条件16

";
CM_ SG_ 1476 ZCUF_VB1_NetworkReqCondition17 "

Wakeup or Request or Keep Network Condition17
唤醒或请求或保持网络条件17

";
CM_ SG_ 1476 ZCUF_VB1_NetworkReqCondition18 "

Wakeup or Request or Keep Network Condition18
唤醒或请求或保持网络条件18

";
CM_ SG_ 1476 ZCUF_VB1_NetworkReqCondition19 "

Wakeup or Request or Keep Network Condition19
唤醒或请求或保持网络条件19

";
CM_ SG_ 1476 ZCUF_VB1_NetworkReqCondition20 "

Wakeup or Request or Keep Network Condition20
唤醒或请求或保持网络条件20

";
CM_ SG_ 1476 ZCUF_VB1_NetworkReqCondition21 "

Wakeup or Request or Keep Network Condition20
唤醒或请求或保持网络条件21

";
CM_ SG_ 1476 ZCUF_VB1_NetworkReqCondition22 "

Wakeup or Request or Keep Network Condition20
唤醒或请求或保持网络条件22

";
CM_ SG_ 1476 ZCUF_VB1_NetworkReqCondition23 "

Wakeup or Request or Keep Network Condition20
唤醒或请求或保持网络条件23

";
CM_ SG_ 1476 ZCUF_VB1_NetworkReqCondition24 "

Wakeup or Request or Keep Network Condition20
唤醒或请求或保持网络条件24

";
CM_ SG_ 1476 ZCUF_VB1_NetworkReqCondition25 "

Wakeup or Request or Keep Network Condition20
唤醒或请求或保持网络条件25

";
CM_ SG_ 1476 ZCUF_VB1_NetworkReqCondition26 "

Wakeup or Request or Keep Network Condition20
唤醒或请求或保持网络条件26

";
CM_ SG_ 1476 ZCUF_VB1_NetworkReqCondition27 "

Wakeup or Request or Keep Network Condition20
唤醒或请求或保持网络条件27

";
CM_ SG_ 1476 ZCUF_VB1_NetworkReqCondition28 "

Wakeup or Request or Keep Network Condition20
唤醒或请求或保持网络条件28

";
CM_ SG_ 1476 ZCUF_VB1_NetworkReqCondition29 "

Wakeup or Request or Keep Network Condition20
唤醒或请求或保持网络条件29

";
CM_ SG_ 1476 ZCUF_VB1_NetworkReqCondition30 "

Wakeup or Request or Keep Network Condition20
唤醒或请求或保持网络条件30

";
CM_ SG_ 1476 ZCUF_VB1_NetworkReqCondition31 "

Wakeup or Request or Keep Network Condition20
唤醒或请求或保持网络条件31

";
CM_ SG_ 1412 ZCUF_WakeupReq_HDBT " Wakeup HDBT domain-related ECU flag bits, each bit represents an ECU, the correspondence between bit and ECU refers to Sleep Wakeup List 唤醒HDBT域相关ECU标志位，每一bit位代表一个ECU，具体bit与ECU的对应关系见休眠唤醒列表。 ";
CM_ SG_ 1412 ZCUF_WakeupReq_HDBI " Wakeup HDBI domain-related ECU flag bits, each bit represents an ECU, the correspondence between bit and ECU refers to Sleep Wakeup List 唤醒HDBI域相关ECU标志位，每一bit位代表一个ECU，具体bit与ECU的对应关系见休眠唤醒列表。 ";
CM_ SG_ 1412 ZCUF_WakeupReq_HDBA " Wakeup HDBA domain-related ECU flag bits, each bit represents an ECU, the correspondence between bit and ECU refers to Sleep Wakeup List 唤醒HDBA域相关ECU标志位，每一bit位代表一个ECU，具体bit与ECU的对应关系见休眠唤醒列表。 ";
CM_ SG_ 1412 ZCUF_WakeupReq_HDBM " Wakeup HDBM domain-related ECU flag bits, each bit represents an ECU, the correspondence between bit and ECU refers to Sleep Wakeup List 唤醒HDBM域相关ECU标志位，每一bit位代表一个ECU，具体bit与ECU的对应关系见休眠唤醒列表。 ";
CM_ SG_ 1412 ZCUF_WakeupReq_ZCUF " Wakeup ZCUF domain-related ECU flag bits, each bit represents an ECU, the correspondence between bit and ECU refers to Sleep Wakeup List 唤醒ZCUF域相关ECU标志位，每一bit位代表一个ECU，具体bit与ECU的对应关系见休眠唤醒列表。 ";
CM_ SG_ 1412 ZCUF_WakeupReq_ZCUL " Wakeup ZCUL domain-related ECU flag bits, each bit represents an ECU, the correspondence between bit and ECU refers to Sleep Wakeup List 唤醒ZCUL域相关ECU标志位，每一bit位代表一个ECU，具体bit与ECU的对应关系见休眠唤醒列表。 ";
CM_ SG_ 1412 ZCUF_WakeupReq_ZCUR " Wakeup ZCUR domain-related ECU flag bits, each bit represents an ECU, the correspondence between bit and ECU refers to Sleep Wakeup List 唤醒ZCUR域相关ECU标志位，每一bit位代表一个ECU，具体bit与ECU的对应关系见休眠唤醒列表。 ";
CM_ SG_ 1412 ZCUF_WakeupReq_ZCUT " Wakeup ZCUT domain-related ECU flag bits, each bit represents an ECU, the correspondence between bit and ECU refers to Sleep Wakeup List 唤醒ZCUT域相关ECU标志位，每一bit位代表一个ECU，具体bit与ECU的对应关系见休眠唤醒列表。 ";
CM_ SG_ 1104 ZCUF_NodeAddress_VB1 "
Node source address
节点源地址
";
CM_ SG_ 1104 ZCUF_RepeatMsgReq_VB1 "
Repeat Message Request Bit
重复报文请求位
";
CM_ SG_ 1104 ZCUF_ActiveWakeup_VB1 "
Active Wakeup Bit
主动唤醒指示位
";
CM_ SG_ 1104 ZCUF_PartialNetworkInfo_VB1 "
Partial Network Information Bit
部分网络管理信息指示位
";
CM_ SG_ 1104 ZCUF_RepeatMsgSt_VB1 "
Repeat Message State indication
节点处在重复报文状态指示位
";
CM_ SG_ 1104 ZCUF_PN_HDBT_VB1 "
Wakeup Target ECU requirement flag
唤醒目标ECU需求标志
";
CM_ SG_ 1104 ZCUF_PN_HDBI_VB1 "
Wakeup Target ECU requirement flag
唤醒目标ECU需求标志
";
CM_ SG_ 1104 ZCUF_PN_HDBA_VB1 "
Wakeup Target ECU requirement flag
唤醒目标ECU需求标志
";
CM_ SG_ 1104 ZCUF_PN_HDBM_VB1 "
Wakeup Target ECU requirement flag
唤醒目标ECU需求标志
";
CM_ SG_ 1104 ZCUF_PN_ZCUF_VB1 "
Wakeup Target ECU requirement flag
唤醒目标ECU需求标志
";
CM_ SG_ 1104 ZCUF_PN_ZCUL_VB1 "
Wakeup Target ECU requirement flag
唤醒目标ECU需求标志
";
CM_ SG_ 1104 ZCUF_PN_ZCUR_VB1 "
Wakeup Target ECU requirement flag
唤醒目标ECU需求标志
";
CM_ SG_ 1104 ZCUF_PN_ZCUT_VB1 "
Wakeup Target ECU requirement flag
唤醒目标ECU需求标志
";
CM_ SG_ 562 CHVH_InltTmp_Val "

CHVH进水口温度

";
CM_ SG_ 562 CHVH_OutltTmp_Val "

CHVH出水口温度

";
CM_ SG_ 562 AQS_Luftguete_Val "
 entspricht STATUS_FAS 
";
CM_ SG_ 562 TCM_FD_RT_1_AQSAvailable_St "


If signals which route from AQS in message TCM_FD_RT_1 are available
报文TCM_FD_RT_1中路由的AQS节点的信号是否可信


";
CM_ SG_ 562 CHVH_ActuPwr_Val "

CHVH实际功率

";
CM_ SG_ 562 CHVH_Fault_St "

CHVH 运行状态

";
CM_ SG_ 514 TCM_V3WHeatActualPos_Val "
暖芯三通阀实际位置



";
CM_ SG_ 514 TCM_ThermalCoolantTemp_Val "


热管理冷却液回路水温


";
CM_ SG_ 514 TCM_OHXEXVRun_St "

Running Status

";
CM_ SG_ 514 TCM_OHXEXVPos_Val "
Position
";
CM_ SG_ 514 TCM_OHXEXVOverTempWarn_St "

Over Temperature Warn

";
CM_ SG_ 514 TCM_OHXEXVInit_St "

Current Initialization Status

";
CM_ SG_ 514 TCM_OHXEXVFault_St "

Fault Status

";
CM_ SG_ 514 TCM_OHXEXVCal_Req "

外换EXV自标定请求

";
CM_ SG_ 514 TCM_LINPowerHSD_St "

TCM_LIN总线供电继电器状态

";
CM_ SG_ 514 TCM_HPLowPressSOVFault_St "



热泵回路低压截止阀驱动状态



";
CM_ SG_ 514 TCM_HPLowPressSOV_St "
热泵回路低压截止阀开关状态
";
CM_ SG_ 514 TCM_HPHighPressSOVFault_St "



热泵回路高压截止阀驱动状态



";
CM_ SG_ 514 TCM_HPHighPressSOV_St "
热泵回路高压截止阀开关状态
";
CM_ SG_ 514 TCM_HPChillerTempValid_St "

热泵换热器温度传感器有效性

";
CM_ SG_ 514 TCM_HPChillerTemp_Val "
HP Chiller出口温度原始值
";
CM_ SG_ 514 TCM_HEXVRun_St "

Running Status

";
CM_ SG_ 514 TCM_HEXVPos_Val "
HVAC EXV feedback current position                        
HVAC EXV 反馈当前位置
";
CM_ SG_ 514 TCM_HEXVOverTempWarn_St "

Over Temperature Warn

";
CM_ SG_ 514 TCM_HEXVInit_St "

Current Initialization Status

";
CM_ SG_ 514 TCM_HEXVFault_St "

Fault Status

";
CM_ SG_ 514 TCM_HEXVCal_Req "

HVAC EXV自标定请求

";
CM_ SG_ 514 TCM_HeatPumpAcutalSpdPct_Val "

Pump Actual Percentage of Speed 
真实转速百分比

";
CM_ SG_ 514 TCM_FHVACOutletTempValid_St "

前空调箱出口温度传感器有效性

";
CM_ SG_ 514 TCM_FHVACOutletTemp_Val "

前空调箱出口温度原始值

";
CM_ SG_ 514 TCM_CombChillerTempValid_St "

电池冷却器温度传感器有效性

";
CM_ SG_ 514 TCM_CombChillerTemp_Val "
Chiller出口温度原始值
";
CM_ SG_ 514 TCM_ChillerEXVRun_St "

Running Status

";
CM_ SG_ 514 TCM_ChillerEXVPos_Val "
Position
";
CM_ SG_ 514 TCM_ChillerEXVOverTempWarn_St "

Over Temperature Warn

";
CM_ SG_ 514 TCM_ChillerEXVInit_St "

Current Initialization Status

";
CM_ SG_ 514 TCM_ChillerEXVFault_St "

Fault Status

";
CM_ SG_ 514 TCM_ChillerEXVCal_Req "

外换EXV自标定请求

";
CM_ SG_ 514 TCM_ACSOVFault_St "



制冷回路截止阀驱动状态



";
CM_ SG_ 514 TCM_ACSOV_St "
制冷回路截止阀开关状态
";
CM_ SG_ 515 TCM_V5WV4wActualPosition_Val "

五通阀中四通实际位置

";
CM_ SG_ 515 TCM_V5WV3wActualPosition_Val "

五通阀中三通实际位置

";
CM_ SG_ 515 TCM_V5wMotor_St "

热管理五通阀电机运行状态

";
CM_ SG_ 515 TCM_V5wFault_St "

热管理五通阀故障状态

";
CM_ SG_ 515 TCM_V3wMotFault_St "

电机三通阀故障状态

";
CM_ SG_ 515 TCM_V3WHeatPMotor_St "

暖芯三通阀电机运行状态

";
CM_ SG_ 515 TCM_V3WHeatPCal_Req "

暖芯三通阀自标定请求

";
CM_ SG_ 515 TCM_V3WHeatFault_St "

暖芯三通阀故障状态

";
CM_ SG_ 515 TCM_V3WHeatCal_St "

暖芯三通阀自标定状态

";
CM_ SG_ 515 TCM_ThermalLiquidLackWarn_St "

电池电机回路水壶液位传感器报警

";
CM_ SG_ 515 TCM_RessPumpFault_St "
电池水泵运行状态
";
CM_ SG_ 515 TCM_PowerVoltage_Val "

low voltage supply voltage
低压供电电压

";
CM_ SG_ 515 TCM_PowerOffDelay_Req "
 TCM供电维持信号 
";
CM_ SG_ 515 TCM_MotPumpFault_St "
电机水泵运行状态
";
CM_ SG_ 515 TCM_HeatPumpFault_St "
采暖水泵运行状态
";
CM_ SG_ 515 TCM_HeatLiquidtLackWarn_St "

暖芯回路水壶液位传感器报警

";
CM_ SG_ 164 EHBM_ABS_Err "
ABS_Fault: ESP system has detected a failure which does not allow a reliable ABS regulation and is therefore switched off
ABS_Fault: ESP系统检测到一个故障,不允许可靠的ABS调节,因此被关闭
";
CM_ SG_ 164 EHBM_EBD_Err "
EBD_Fault: ESP system has detected a heavy fault, which does not even allow a reliable electronic brake distribution and is therefore completely shut down
EBD_Fault: ESP系统检测到严重故障,甚至不允许可靠的电子制动分布,因此完全关闭
";
CM_ SG_ 164 EHBM_BrakeLight_Req "
Request brake light
刹车灯请求
";
CM_ SG_ 164 EHBM_ModeChgEnable_St "
ESC Mode Change Enable
ESC模式接口可用
";
CM_ SG_ 164 EHBM_CST_Rsp "

Indicate CST state

";
CM_ SG_ 164 EHBM_ESC_Err "
ESC_Fault: VDC/TCS is switched off due to detected failure
ESC_Fault:由于检测到故障,VDC/TCS被关闭
";
CM_ SG_ 164 EHBM_EmergencyBrakeLight_Req "
Request emergency brake light
紧急制动灯请求
";
CM_ SG_ 164 EHBM_PataLamp_St "

ESP is diabled by pata
 (Only include TCS function,VDC always ON)
 ESC开启开关(只有TCS功能的开关,VDC功能一直开启)

";
CM_ SG_ 164 EHBM_VehSpd_Val "


Vehicle speed out
车速


";
CM_ SG_ 164 EHBM_VehSpdValid_St "


Vehicle speed out status
车速有效


";
CM_ SG_ 164 EHBM_WorkMode_St "
ESC Working Mode
ESC当前模式
";
CM_ SG_ 164 EHBM_InputRodStroke_Val "
inputrod of driver brake request.
输入司机制动请求。
";
CM_ SG_ 164 EHBM_InputRodStroke_St "
Information about the signal quality of EHBM_inputRodStroke
关于EHBM_inputRodStroke信号质量的信息
";
CM_ SG_ 164 EHBM_BrakePedal_St "
information about the driver attendance
驾驶员参与信息
";
CM_ SG_ 164 EHBM_BrakeMode_St "
dashboard request iBooster mode(sport mode or default mode or comfort mode)
踏板感觉模式
";
CM_ SG_ 164 EHBM_BrakeModeEnable_St "
Brake Mode state
踏板感觉模式切换接口可用
";
CM_ SG_ 164 EHBM_VDCorTCSIntv_St "
Info lamp - Indication that VDC/TCS(engine torque control or brake torque control) system currently performs a brake/engine intervention
指示VDC/TCS(发动机扭矩控制或制动扭矩控制)系统当前执行制动/发动机干预
";
CM_ SG_ 164 EHBM_CtrllerFault_St "
Controller fault status
描述ECU当前故障状态
";
CM_ SG_ 164 EHBM_VDCIntv_St "
VDC controller active: Oversteering brake intervention or Understeering brake intervention
主动VDC控制器:转向过度或转向不足制动干预
";
CM_ SG_ 164 EHBM_ESCSys_Err "
EHBM系统状态
";
CM_ SG_ 164 EHBM_ESCFunSys_St "
ESC系统功能状态
";
CM_ SG_ 164 EHBM_ABSIntv_St "
ABS control active - Indication that ESP system (especially ABS module) currently performs a brake intervention
主动ABS控制-指示ESP系统(特别是ABS模块)当前执行制动干预
";
CM_ SG_ 164 EHBM_EBDIntv_St "
EBD control active - Indication that ESP system (especially EBD module) currently performs a brake intervention
EBD控制激活-指示ESP系统(特别是EBD模块)当前执行制动干预
";
CM_ SG_ 164 EHBM_BrakeFluidLvl_St "
制动液位报警信号
";
CM_ SG_ 164 EHBM_Checksum3 "




E2E Signal Group Checksum
Checksum is the actual value after calculation. 
E2E信号组校验和
Checksum为计算后实际值




";
CM_ SG_ 164 EHBM_RollingCounter3 "


E2E Signal Group Counter
Counter value is automatically accumulated, added from 0 to 255 and then looped to the initial value of 0. Every time a message is sent, counter adds 1.
E2E信号组计数器
Counter值为自动累加,从0加到255,然后循环至初始值0,每次报文发送,Counter加1


";
CM_ SG_ 164 EHBM_HDCAvail_St "

HDC Available
HDC可用

";
CM_ SG_ 164 EHBM_HDC_St "

HDC control(Off/On, not active braking/On, active braking)
HDC控制(关/开,非主动制动/开,主动制动)

";
CM_ SG_ 164 EHBM_BoostDegrade_St "

EHBM制动助力状态

";
CM_ SG_ 164 EHBM_ESCSwAvail_St "
ESC开关可用状态
";
CM_ SG_ 164 EHBM_ESClamp_St "
ESC ON/OFF状态
";
CM_ SG_ 164 EHBM_TCSSwAvail_St "

TCS开关可用状态

";
CM_ SG_ 164 EHBM_AVH_St "
Indicates AVH Status
表明AVH状态
";
CM_ SG_ 164 EHBM_AVHAvail_St "
AVH Available
AVH可用
";
CM_ SG_ 226 ERPB_BU_OperationReminder_UI "





 EPB operation reminder EPB操作提醒 






";
CM_ SG_ 226 ERPB_BU_EPBHardSwitch_St "


EPB switch status
EPB开关状态


";
CM_ SG_ 226 ERPB_BU_EPBFunctionLamp_St "


EPB functon lamp status, dashboard receive this signal to illuminate the function lamp
EPB功能指示灯状态,仪表接收到该信号后需点亮功能灯


";
CM_ SG_ 226 ERPB_BU_EPBFailLamp_St "


EPB failure lamp status, dashboard receive this signal to illuminate the failure lamp
EPB故障指示灯,仪表接收到该信号后需点亮故障灯


";
CM_ SG_ 226 ERPB_BU_EPB_St "


Status of EPB system
EPB系统状态


";
CM_ SG_ 226 ERPB_BU_CapacityLimitWarn_UI "



 EPB Capacity Limit Warn EPB能力限制警告 




";
CM_ SG_ 226 ERPB_BU_BrakeLight_Req "



EPB 请求点亮制动尾灯



";
CM_ SG_ 160 ACU_YawRateValid_St "

Yaw Rate Sensor State
 Wz横摆角速度状态

";
CM_ SG_ 160 ACU_YawRate_Val "


Yaw Rate
 Wz横摆角速


";
CM_ SG_ 160 ACU_LtrlAccelValid_St "

Lateral Accelaration Sensor State
 Y方向加速度状态

";
CM_ SG_ 160 ACU_LtrlAccel_Val "


Lateral Acceleration
 Y方向加速度


";
CM_ SG_ 160 ACU_LongAccel_Val "


Longitude Acceleration X方向加速度


";
CM_ SG_ 160 ACU_AirbagWarnLamp_St "
ACU故障信号
";
CM_ SG_ 160 ACU_DrvrSeatBelt_St "


Driver buckle switch status 主驾安全带状态


";
CM_ SG_ 160 ACU_DrvrSeatBeltValid_St "
Driver buckle switch status valid
 主驾安全带状态有效位
";
CM_ SG_ 176 EPS_WorkMode_St "


EPS working mode EPS当前驾驶模式


";
CM_ SG_ 176 EPS_System_Err "


EPS failure status EPS失效状态


";
CM_ SG_ 176 EPS_ModeChangeEn_St "

EPS working mode change enable
 EPS驾驶模式切换接口可用

";
CM_ SG_ 800 HDBI_NFCAvailability_St "


HDBI  NFC钥匙有效状态


";
CM_ SG_ 1501 HDBI_VB1_NetworkReqCondition0 "
Wakeup or Request or Keep Network Condition0
唤醒或请求或保持网络条件1
";
CM_ SG_ 1501 HDBI_VB1_NetworkReqCondition1 "
Wakeup or Request or Keep Network Condition1
唤醒或请求或保持网络条件1
";
CM_ SG_ 1501 HDBI_VB1_NetworkReqCondition2 "
Wakeup or Request or Keep Network Condition2
唤醒或请求或保持网络条件2
";
CM_ SG_ 1501 HDBI_VB1_NetworkReqCondition3 "
Wakeup or Request or Keep Network Condition3
唤醒或请求或保持网络条件3
";
CM_ SG_ 1501 HDBI_VB1_NetworkReqCondition4 "
Wakeup or Request or Keep Network Condition4
唤醒或请求或保持网络条件4
";
CM_ SG_ 1501 HDBI_VB1_NetworkReqCondition5 "
Wakeup or Request or Keep Network Condition5
唤醒或请求或保持网络条件5
";
CM_ SG_ 1501 HDBI_VB1_NetworkReqCondition6 "
Wakeup or Request or Keep Network Condition6
唤醒或请求或保持网络条件6
";
CM_ SG_ 1501 HDBI_VB1_NetworkReqCondition7 "
Wakeup or Request or Keep Network Condition7
唤醒或请求或保持网络条件7
";
CM_ SG_ 1501 HDBI_VB1_NetworkReqCondition8 "
Wakeup or Request or Keep Network Condition8
唤醒或请求或保持网络条件8
";
CM_ SG_ 1501 HDBI_VB1_NetworkReqCondition9 "
Wakeup or Request or Keep Network Condition9
唤醒或请求或保持网络条件9
";
CM_ SG_ 1501 HDBI_VB1_NetworkReqCondition10 "
Wakeup or Request or Keep Network Condition10
唤醒或请求或保持网络条件10
";
CM_ SG_ 1501 HDBI_VB1_NetworkReqCondition11 "
Wakeup or Request or Keep Network Condition11
唤醒或请求或保持网络条件11
";
CM_ SG_ 1501 HDBI_VB1_NetworkReqCondition12 "
Wakeup or Request or Keep Network Condition12
唤醒或请求或保持网络条件12
";
CM_ SG_ 1501 HDBI_VB1_NetworkReqCondition13 "
Wakeup or Request or Keep Network Condition13
唤醒或请求或保持网络条件13
";
CM_ SG_ 1501 HDBI_VB1_NetworkReqCondition14 "
Wakeup or Request or Keep Network Condition14
唤醒或请求或保持网络条件14
";
CM_ SG_ 1501 HDBI_VB1_NetworkReqCondition15 "
Wakeup or Request or Keep Network Condition15
唤醒或请求或保持网络条件15
";
CM_ SG_ 1501 HDBI_VB1_NetworkReqCondition16 "
Wakeup or Request or Keep Network Condition16
唤醒或请求或保持网络条件16
";
CM_ SG_ 1501 HDBI_VB1_NetworkReqCondition17 "
Wakeup or Request or Keep Network Condition17
唤醒或请求或保持网络条件17
";
CM_ SG_ 1501 HDBI_VB1_NetworkReqCondition18 "
Wakeup or Request or Keep Network Condition18
唤醒或请求或保持网络条件18
";
CM_ SG_ 1501 HDBI_VB1_NetworkReqCondition19 "
Wakeup or Request or Keep Network Condition19
唤醒或请求或保持网络条件19
";
CM_ SG_ 1501 HDBI_VB1_NetworkReqCondition20 "
Wakeup or Request or Keep Network Condition20
唤醒或请求或保持网络条件20
";
CM_ SG_ 1501 HDBI_VB1_NetworkReqCondition21 "
Wakeup or Request or Keep Network Condition20
唤醒或请求或保持网络条件21
";
CM_ SG_ 1501 HDBI_VB1_NetworkReqCondition22 "
Wakeup or Request or Keep Network Condition20
唤醒或请求或保持网络条件22
";
CM_ SG_ 1501 HDBI_VB1_NetworkReqCondition23 "
Wakeup or Request or Keep Network Condition20
唤醒或请求或保持网络条件23
";
CM_ SG_ 1501 HDBI_VB1_NetworkReqCondition24 "
Wakeup or Request or Keep Network Condition20
唤醒或请求或保持网络条件24
";
CM_ SG_ 1501 HDBI_VB1_NetworkReqCondition25 "
Wakeup or Request or Keep Network Condition20
唤醒或请求或保持网络条件25
";
CM_ SG_ 1501 HDBI_VB1_NetworkReqCondition26 "
Wakeup or Request or Keep Network Condition20
唤醒或请求或保持网络条件26
";
CM_ SG_ 1501 HDBI_VB1_NetworkReqCondition27 "
Wakeup or Request or Keep Network Condition20
唤醒或请求或保持网络条件27
";
CM_ SG_ 1501 HDBI_VB1_NetworkReqCondition28 "
Wakeup or Request or Keep Network Condition20
唤醒或请求或保持网络条件28
";
CM_ SG_ 1501 HDBI_VB1_NetworkReqCondition29 "
Wakeup or Request or Keep Network Condition20
唤醒或请求或保持网络条件29
";
CM_ SG_ 1501 HDBI_VB1_NetworkReqCondition30 "
Wakeup or Request or Keep Network Condition20
唤醒或请求或保持网络条件30
";
CM_ SG_ 1501 HDBI_VB1_NetworkReqCondition31 "
Wakeup or Request or Keep Network Condition20
唤醒或请求或保持网络条件31
";
CM_ SG_ 1344 HDBI_WakeupReq_HDBI "
Wakeup HDBI domain requirement flag
唤醒HDBI域需求标志
";
CM_ SG_ 1344 HDBI_WakeupReq_HDBM "
Wakeup HDBM domain requirement flag
唤醒HDBM域需求标志
";
CM_ SG_ 1057 HDBI_NodeAddress_VB1 "
Node source address
节点源地址
";
CM_ SG_ 1057 HDBI_RepeatMsgReq_VB1 "
Repeat Message Request Bit
重复报文请求位
";
CM_ SG_ 1057 HDBI_ActiveWakeup_VB1 "
Active Wakeup Bit
主动唤醒指示位
";
CM_ SG_ 1057 HDBI_PartialNetworkInfo_VB1 "
Partial Network Information Bit
部分网络管理信息指示位
";
CM_ SG_ 1057 HDBI_RepeatMsgSt_VB1 "
Repeat Message State indication
节点处在重复报文状态指示位
";
CM_ SG_ 1057 HDBI_PN_HDBT_VB1 "
Wakeup Target ECU requirement flag
唤醒目标ECU需求标志
";
CM_ SG_ 1057 HDBI_PN_HDBI_VB1 "
Wakeup Target ECU requirement flag
唤醒目标ECU需求标志
";
CM_ SG_ 1057 HDBI_PN_HDBA_VB1 "
Wakeup Target ECU requirement flag
唤醒目标ECU需求标志
";
CM_ SG_ 1057 HDBI_PN_HDBM_VB1 "
Wakeup Target ECU requirement flag
唤醒目标ECU需求标志
";
CM_ SG_ 1057 HDBI_PN_ZCUF_VB1 "
Wakeup Target ECU requirement flag
唤醒目标ECU需求标志
";
CM_ SG_ 1057 HDBI_PN_ZCUL_VB1 "
Wakeup Target ECU requirement flag
唤醒目标ECU需求标志
";
CM_ SG_ 1057 HDBI_PN_ZCUR_VB1 "
Wakeup Target ECU requirement flag
唤醒目标ECU需求标志
";
CM_ SG_ 1057 HDBI_PN_ZCUT_VB1 "
Wakeup Target ECU requirement flag
唤醒目标ECU需求标志
";
BA_DEF_ BO_  "MessageIdType" ENUM  "Normal","NM","DiagRequest","DiagResponse","DiagState";
BA_DEF_ BO_  "GenMsgSendType" ENUM  "Cyclic","NotUsed","NotUsed","NotUsed","NotUsed","NotUsed","NotUsed","NotUsed","NoMsgSendType","CA","CE","Event","IfActive";
BA_DEF_ BO_  "VFrameFormat" ENUM  "StandardCAN","ExtendedCAN","reserved","reserved","reserved","reserved","reserved","reserved","reserved","reserved","reserved","reserved","reserved","reserved","StandardCAN_FD","ExtendedCAN_FD";
BA_DEF_ BO_  "GenMsgCycleTime" INT 0 0;
BA_DEF_ BO_  "GenMsgCycleTimeFast" INT 0 0;
BA_DEF_ BO_  "CANFD_BRS" ENUM  "0","1";
BA_DEF_ BO_  "GenMsgNrOfRepetition" INT 0 0;
BA_DEF_ BO_  "GenMsgDelayTime" INT 0 0;
BA_DEF_ BO_  "GenMsgILSupport" ENUM  "No","Yes";
BA_DEF_ BO_  "GenMsgStartDelayTime" INT 0 0;
BA_DEF_ BO_  "NmAsrMessage" ENUM  "No","Yes";
BA_DEF_ SG_  "GenSigSendType" ENUM  "Cyclic","OnWrite","OnWriteWithRepetition","OnChange","OnChangeWithRepetition","NotUsed","NotUsed","NoSigSendType","IfActive","IfActiveWithRepetition","OnChangeAndIfActive","OnChangeAndIfActiveWithRepetition","CA","CE","Event";
BA_DEF_ SG_  "GenSigStartValue" INT 0 0;
BA_DEF_ SG_  "GenSigInactiveValue" INT 0 0;
BA_DEF_DEF_  "MessageIdType" "Normal";
BA_DEF_DEF_  "GenMsgSendType" "";
BA_DEF_DEF_  "VFrameFormat" "StandardCAN";
BA_DEF_DEF_  "GenMsgCycleTime" 0;
BA_DEF_DEF_  "GenMsgCycleTimeFast" 0;
BA_DEF_DEF_  "CANFD_BRS" "0";
BA_DEF_DEF_  "GenMsgNrOfRepetition" 0;
BA_DEF_DEF_  "GenMsgDelayTime" 0;
BA_DEF_DEF_  "GenMsgILSupport" "No";
BA_DEF_DEF_  "GenMsgStartDelayTime" 0;
BA_DEF_DEF_  "NmAsrMessage" "No";
BA_DEF_DEF_  "GenSigSendType" "";
BA_DEF_DEF_  "GenSigStartValue" 0;
BA_DEF_DEF_  "GenSigInactiveValue" 0;
BA_ "CANFD_BRS" BO_ 656 1;
BA_ "GenMsgCycleTime" BO_ 656 100;
BA_ "GenMsgSendType" BO_ 656 0;
BA_ "GenMsgILSupport" BO_ 656 1;
BA_ "VFrameFormat" BO_ 656 14;
BA_ "CANFD_BRS" BO_ 657 1;
BA_ "GenMsgCycleTime" BO_ 657 100;
BA_ "GenMsgSendType" BO_ 657 0;
BA_ "GenMsgILSupport" BO_ 657 1;
BA_ "VFrameFormat" BO_ 657 14;
BA_ "CANFD_BRS" BO_ 912 1;
BA_ "GenMsgCycleTime" BO_ 912 200;
BA_ "GenMsgSendType" BO_ 912 0;
BA_ "GenMsgILSupport" BO_ 912 1;
BA_ "VFrameFormat" BO_ 912 14;
BA_ "GenMsgDelayTime" BO_ 1472 20;
BA_ "GenMsgNrOfRepetition" BO_ 1472 3;
BA_ "GenMsgCycleTimeFast" BO_ 1472 100;
BA_ "CANFD_BRS" BO_ 1472 1;
BA_ "GenMsgCycleTime" BO_ 1472 500;
BA_ "GenMsgSendType" BO_ 1472 10;
BA_ "GenMsgILSupport" BO_ 1472 1;
BA_ "VFrameFormat" BO_ 1472 14;
BA_ "GenMsgDelayTime" BO_ 658 10;
BA_ "GenMsgNrOfRepetition" BO_ 658 3;
BA_ "GenMsgCycleTimeFast" BO_ 658 100;
BA_ "CANFD_BRS" BO_ 658 1;
BA_ "GenMsgSendType" BO_ 658 11;
BA_ "GenMsgILSupport" BO_ 658 1;
BA_ "VFrameFormat" BO_ 658 14;
BA_ "GenMsgCycleTime" BO_ 1106 500;
BA_ "GenMsgSendType" BO_ 1106 0;
BA_ "NmAsrMessage" BO_ 1106 1;
BA_ "GenMsgILSupport" BO_ 1106 1;
BA_ "MessageIdType" BO_ 1106 1;
BA_ "GenMsgDelayTime" BO_ 1414 5;
BA_ "GenMsgNrOfRepetition" BO_ 1414 15;
BA_ "GenMsgCycleTimeFast" BO_ 1414 20;
BA_ "CANFD_BRS" BO_ 1414 1;
BA_ "GenMsgCycleTime" BO_ 1414 500;
BA_ "GenMsgSendType" BO_ 1414 10;
BA_ "GenMsgILSupport" BO_ 1414 1;
BA_ "VFrameFormat" BO_ 1414 14;
BA_ "CANFD_BRS" BO_ 1495 1;
BA_ "GenMsgCycleTime" BO_ 1495 1000;
BA_ "GenMsgSendType" BO_ 1495 0;
BA_ "GenMsgILSupport" BO_ 1495 1;
BA_ "VFrameFormat" BO_ 1495 14;
BA_ "CANFD_BRS" BO_ 431 1;
BA_ "GenMsgCycleTime" BO_ 431 50;
BA_ "GenMsgSendType" BO_ 431 0;
BA_ "GenMsgILSupport" BO_ 431 1;
BA_ "VFrameFormat" BO_ 431 14;
BA_ "CANFD_BRS" BO_ 112 1;
BA_ "GenMsgCycleTime" BO_ 112 10;
BA_ "GenMsgSendType" BO_ 112 0;
BA_ "GenMsgILSupport" BO_ 112 1;
BA_ "VFrameFormat" BO_ 112 14;
BA_ "CANFD_BRS" BO_ 400 1;
BA_ "GenMsgCycleTime" BO_ 400 50;
BA_ "GenMsgSendType" BO_ 400 0;
BA_ "GenMsgILSupport" BO_ 400 1;
BA_ "VFrameFormat" BO_ 400 14;
BA_ "CANFD_BRS" BO_ 896 1;
BA_ "GenMsgCycleTime" BO_ 896 200;
BA_ "GenMsgSendType" BO_ 896 0;
BA_ "GenMsgILSupport" BO_ 896 1;
BA_ "VFrameFormat" BO_ 896 14;
BA_ "GenMsgDelayTime" BO_ 1408 20;
BA_ "GenMsgNrOfRepetition" BO_ 1408 3;
BA_ "GenMsgCycleTimeFast" BO_ 1408 100;
BA_ "CANFD_BRS" BO_ 1408 1;
BA_ "GenMsgCycleTime" BO_ 1408 500;
BA_ "GenMsgSendType" BO_ 1408 10;
BA_ "GenMsgILSupport" BO_ 1408 1;
BA_ "VFrameFormat" BO_ 1408 14;
BA_ "GenMsgDelayTime" BO_ 672 20;
BA_ "GenMsgNrOfRepetition" BO_ 672 3;
BA_ "GenMsgCycleTimeFast" BO_ 672 100;
BA_ "CANFD_BRS" BO_ 672 1;
BA_ "GenMsgSendType" BO_ 672 11;
BA_ "GenMsgILSupport" BO_ 672 1;
BA_ "VFrameFormat" BO_ 672 14;
BA_ "GenMsgDelayTime" BO_ 673 10;
BA_ "GenMsgNrOfRepetition" BO_ 673 3;
BA_ "GenMsgCycleTimeFast" BO_ 673 20;
BA_ "CANFD_BRS" BO_ 673 1;
BA_ "GenMsgCycleTime" BO_ 673 100;
BA_ "GenMsgSendType" BO_ 673 10;
BA_ "GenMsgILSupport" BO_ 673 1;
BA_ "VFrameFormat" BO_ 673 14;
BA_ "CANFD_BRS" BO_ 401 1;
BA_ "GenMsgCycleTime" BO_ 401 50;
BA_ "GenMsgSendType" BO_ 401 0;
BA_ "GenMsgILSupport" BO_ 401 1;
BA_ "VFrameFormat" BO_ 401 14;
BA_ "CANFD_BRS" BO_ 403 1;
BA_ "GenMsgCycleTime" BO_ 403 50;
BA_ "GenMsgSendType" BO_ 403 0;
BA_ "GenMsgILSupport" BO_ 403 1;
BA_ "VFrameFormat" BO_ 403 14;
BA_ "CANFD_BRS" BO_ 1482 1;
BA_ "GenMsgCycleTime" BO_ 1482 1000;
BA_ "GenMsgSendType" BO_ 1482 0;
BA_ "GenMsgILSupport" BO_ 1482 1;
BA_ "VFrameFormat" BO_ 1482 14;
BA_ "GenMsgDelayTime" BO_ 1415 5;
BA_ "GenMsgNrOfRepetition" BO_ 1415 15;
BA_ "GenMsgCycleTimeFast" BO_ 1415 20;
BA_ "CANFD_BRS" BO_ 1415 1;
BA_ "GenMsgCycleTime" BO_ 1415 500;
BA_ "GenMsgSendType" BO_ 1415 10;
BA_ "GenMsgILSupport" BO_ 1415 1;
BA_ "VFrameFormat" BO_ 1415 14;
BA_ "GenMsgCycleTime" BO_ 1107 500;
BA_ "GenMsgSendType" BO_ 1107 0;
BA_ "NmAsrMessage" BO_ 1107 1;
BA_ "GenMsgILSupport" BO_ 1107 1;
BA_ "MessageIdType" BO_ 1107 1;
BA_ "CANFD_BRS" BO_ 320 1;
BA_ "GenMsgCycleTime" BO_ 320 50;
BA_ "GenMsgSendType" BO_ 320 0;
BA_ "GenMsgILSupport" BO_ 320 1;
BA_ "VFrameFormat" BO_ 320 14;
BA_ "CANFD_BRS" BO_ 528 1;
BA_ "GenMsgCycleTime" BO_ 528 100;
BA_ "GenMsgSendType" BO_ 528 0;
BA_ "GenMsgILSupport" BO_ 528 1;
BA_ "VFrameFormat" BO_ 528 14;
BA_ "GenMsgDelayTime" BO_ 1424 20;
BA_ "GenMsgNrOfRepetition" BO_ 1424 3;
BA_ "GenMsgCycleTimeFast" BO_ 1424 100;
BA_ "CANFD_BRS" BO_ 1424 1;
BA_ "GenMsgCycleTime" BO_ 1424 500;
BA_ "GenMsgSendType" BO_ 1424 10;
BA_ "GenMsgILSupport" BO_ 1424 1;
BA_ "VFrameFormat" BO_ 1424 14;
BA_ "GenMsgDelayTime" BO_ 513 10;
BA_ "GenMsgNrOfRepetition" BO_ 513 3;
BA_ "GenMsgCycleTimeFast" BO_ 513 10;
BA_ "CANFD_BRS" BO_ 513 1;
BA_ "GenMsgCycleTime" BO_ 513 100;
BA_ "GenMsgSendType" BO_ 513 10;
BA_ "GenMsgILSupport" BO_ 513 1;
BA_ "VFrameFormat" BO_ 513 14;
BA_ "GenMsgDelayTime" BO_ 880 10;
BA_ "GenMsgNrOfRepetition" BO_ 880 3;
BA_ "GenMsgCycleTimeFast" BO_ 880 50;
BA_ "CANFD_BRS" BO_ 880 1;
BA_ "GenMsgCycleTime" BO_ 880 200;
BA_ "GenMsgSendType" BO_ 880 10;
BA_ "GenMsgILSupport" BO_ 880 1;
BA_ "VFrameFormat" BO_ 880 14;
BA_ "CANFD_BRS" BO_ 97 1;
BA_ "GenMsgCycleTime" BO_ 97 10;
BA_ "GenMsgSendType" BO_ 97 0;
BA_ "GenMsgILSupport" BO_ 97 1;
BA_ "VFrameFormat" BO_ 97 14;
BA_ "CANFD_BRS" BO_ 448 1;
BA_ "GenMsgCycleTime" BO_ 448 100;
BA_ "GenMsgSendType" BO_ 448 0;
BA_ "GenMsgILSupport" BO_ 448 1;
BA_ "VFrameFormat" BO_ 448 14;
BA_ "CANFD_BRS" BO_ 225 1;
BA_ "GenMsgCycleTime" BO_ 225 20;
BA_ "GenMsgSendType" BO_ 225 0;
BA_ "GenMsgILSupport" BO_ 225 1;
BA_ "VFrameFormat" BO_ 225 14;
BA_ "CANFD_BRS" BO_ 1476 1;
BA_ "GenMsgCycleTime" BO_ 1476 1000;
BA_ "GenMsgSendType" BO_ 1476 0;
BA_ "GenMsgILSupport" BO_ 1476 1;
BA_ "VFrameFormat" BO_ 1476 14;
BA_ "GenMsgDelayTime" BO_ 1412 5;
BA_ "GenMsgNrOfRepetition" BO_ 1412 15;
BA_ "GenMsgCycleTimeFast" BO_ 1412 20;
BA_ "CANFD_BRS" BO_ 1412 1;
BA_ "GenMsgCycleTime" BO_ 1412 500;
BA_ "GenMsgSendType" BO_ 1412 10;
BA_ "GenMsgILSupport" BO_ 1412 1;
BA_ "VFrameFormat" BO_ 1412 14;
BA_ "GenMsgCycleTime" BO_ 1104 500;
BA_ "GenMsgSendType" BO_ 1104 0;
BA_ "NmAsrMessage" BO_ 1104 1;
BA_ "GenMsgILSupport" BO_ 1104 1;
BA_ "MessageIdType" BO_ 1104 1;
BA_ "CANFD_BRS" BO_ 562 1;
BA_ "GenMsgCycleTime" BO_ 562 100;
BA_ "GenMsgSendType" BO_ 562 0;
BA_ "GenMsgILSupport" BO_ 562 1;
BA_ "VFrameFormat" BO_ 562 14;
BA_ "CANFD_BRS" BO_ 514 1;
BA_ "GenMsgCycleTime" BO_ 514 100;
BA_ "GenMsgSendType" BO_ 514 0;
BA_ "GenMsgILSupport" BO_ 514 1;
BA_ "VFrameFormat" BO_ 514 14;
BA_ "CANFD_BRS" BO_ 515 1;
BA_ "GenMsgCycleTime" BO_ 515 100;
BA_ "GenMsgSendType" BO_ 515 0;
BA_ "GenMsgILSupport" BO_ 515 1;
BA_ "VFrameFormat" BO_ 515 14;
BA_ "CANFD_BRS" BO_ 164 1;
BA_ "GenMsgCycleTime" BO_ 164 20;
BA_ "GenMsgSendType" BO_ 164 0;
BA_ "GenMsgILSupport" BO_ 164 1;
BA_ "VFrameFormat" BO_ 164 14;
BA_ "CANFD_BRS" BO_ 226 1;
BA_ "GenMsgCycleTime" BO_ 226 20;
BA_ "GenMsgSendType" BO_ 226 0;
BA_ "GenMsgILSupport" BO_ 226 1;
BA_ "VFrameFormat" BO_ 226 14;
BA_ "GenMsgNrOfRepetition" BO_ 160 2;
BA_ "GenMsgCycleTimeFast" BO_ 160 5;
BA_ "CANFD_BRS" BO_ 160 1;
BA_ "GenMsgCycleTime" BO_ 160 20;
BA_ "GenMsgSendType" BO_ 160 10;
BA_ "GenMsgILSupport" BO_ 160 1;
BA_ "VFrameFormat" BO_ 160 14;
BA_ "CANFD_BRS" BO_ 176 1;
BA_ "GenMsgCycleTime" BO_ 176 20;
BA_ "GenMsgSendType" BO_ 176 0;
BA_ "GenMsgILSupport" BO_ 176 1;
BA_ "VFrameFormat" BO_ 176 14;
BA_ "GenMsgNrOfRepetition" BO_ 800 3;
BA_ "GenMsgCycleTimeFast" BO_ 800 50;
BA_ "CANFD_BRS" BO_ 800 1;
BA_ "GenMsgCycleTime" BO_ 800 200;
BA_ "GenMsgSendType" BO_ 800 10;
BA_ "GenMsgILSupport" BO_ 800 1;
BA_ "VFrameFormat" BO_ 800 14;
BA_ "GenMsgNrOfRepetition" BO_ 820 3;
BA_ "GenMsgCycleTimeFast" BO_ 820 50;
BA_ "CANFD_BRS" BO_ 820 1;
BA_ "GenMsgCycleTime" BO_ 820 200;
BA_ "GenMsgSendType" BO_ 820 10;
BA_ "GenMsgILSupport" BO_ 820 1;
BA_ "VFrameFormat" BO_ 820 14;
BA_ "CANFD_BRS" BO_ 1501 1;
BA_ "GenMsgCycleTime" BO_ 1501 1000;
BA_ "GenMsgSendType" BO_ 1501 0;
BA_ "GenMsgILSupport" BO_ 1501 1;
BA_ "VFrameFormat" BO_ 1501 14;
BA_ "GenMsgDelayTime" BO_ 1344 5;
BA_ "GenMsgNrOfRepetition" BO_ 1344 15;
BA_ "GenMsgCycleTimeFast" BO_ 1344 20;
BA_ "CANFD_BRS" BO_ 1344 1;
BA_ "GenMsgCycleTime" BO_ 1344 500;
BA_ "GenMsgSendType" BO_ 1344 10;
BA_ "GenMsgILSupport" BO_ 1344 1;
BA_ "VFrameFormat" BO_ 1344 14;
BA_ "GenMsgCycleTime" BO_ 1057 500;
BA_ "GenMsgSendType" BO_ 1057 0;
BA_ "NmAsrMessage" BO_ 1057 1;
BA_ "GenMsgILSupport" BO_ 1057 1;
BA_ "MessageIdType" BO_ 1057 1;
BA_ "GenSigSendType" SG_ 656 ZCUR_FHVACBypassMotor_Err 0;
BA_ "GenSigSendType" SG_ 656 ZCUR_FHVACDefrostMotor_Err 0;
BA_ "GenSigSendType" SG_ 656 ZCUR_FHVACBLW_Err 0;
BA_ "GenSigSendType" SG_ 656 ZCUR_FHVACModePos_Rsp 0;
BA_ "GenSigSendType" SG_ 656 ZCUR_FHVACCyclePos_Rsp 0;
BA_ "GenSigSendType" SG_ 656 ZCUR_FHVACBypassPos_Rsp 0;
BA_ "GenSigSendType" SG_ 656 ZCUR_FHVACDefrostPos_Rsp 0;
BA_ "GenSigSendType" SG_ 656 ZCUR_FHVACBLWPWM_Rsp 0;
BA_ "GenSigSendType" SG_ 656 ZCUR_FHVACBLWRelay_St 0;
BA_ "GenSigSendType" SG_ 656 ZCUR_FHVACLeftMixPos_Rsp 0;
BA_ "GenSigSendType" SG_ 656 ZCUR_FHVACRigtMixPos_Rsp 0;
BA_ "GenSigSendType" SG_ 656 ZCUR_FHVACLeftMixMotor_Err 0;
BA_ "GenSigSendType" SG_ 656 ZCUR_FHVACModeMotor_Err 0;
BA_ "GenSigSendType" SG_ 656 ZCUR_FHVACCycleMotor_Err 0;
BA_ "GenSigSendType" SG_ 656 ZCUR_FHVACBLWRelay_Err 0;
BA_ "GenSigSendType" SG_ 656 ZCUR_FHVACRigtMixMotor_Err 0;
BA_ "GenSigSendType" SG_ 657 ZCUR_TDuctRVValid_St 0;
BA_ "GenSigSendType" SG_ 657 ZCUR_TDuctLFValid_St 0;
BA_ "GenSigSendType" SG_ 657 ZCUR_TDuctRFValid_St 0;
BA_ "GenSigStartValue" SG_ 657 ZCUR_ADSTws_Val 4095;
BA_ "GenSigSendType" SG_ 657 ZCUR_ADSTws_Val 0;
BA_ "GenSigSendType" SG_ 657 ZCUR_ION_St 0;
BA_ "GenSigStartValue" SG_ 657 ZCUR_ADSTrh_Val 4095;
BA_ "GenSigSendType" SG_ 657 ZCUR_ADSTrh_Val 0;
BA_ "GenSigStartValue" SG_ 657 ZCUR_ADShumidity_Val 4095;
BA_ "GenSigSendType" SG_ 657 ZCUR_ADShumidity_Val 0;
BA_ "GenSigStartValue" SG_ 657 ZCUR_TcabOrig_Val 4095;
BA_ "GenSigSendType" SG_ 657 ZCUR_TcabOrig_Val 0;
BA_ "GenSigStartValue" SG_ 657 ZCUR_TEvapOrig_Val 4095;
BA_ "GenSigSendType" SG_ 657 ZCUR_TEvapOrig_Val 0;
BA_ "GenSigStartValue" SG_ 657 ZCUR_TDuctLV_Val 4095;
BA_ "GenSigSendType" SG_ 657 ZCUR_TDuctLV_Val 0;
BA_ "GenSigStartValue" SG_ 657 ZCUR_TDuctRV_Val 4095;
BA_ "GenSigSendType" SG_ 657 ZCUR_TDuctRV_Val 0;
BA_ "GenSigStartValue" SG_ 657 ZCUR_TDuctLF_Val 4095;
BA_ "GenSigSendType" SG_ 657 ZCUR_TDuctLF_Val 0;
BA_ "GenSigStartValue" SG_ 657 ZCUR_TDuctRF_Val 4095;
BA_ "GenSigSendType" SG_ 657 ZCUR_TDuctRF_Val 0;
BA_ "GenSigSendType" SG_ 657 ZCUR_ADS_Valid_St 0;
BA_ "GenSigSendType" SG_ 657 ZCUR_TcabOrigValid_St 0;
BA_ "GenSigSendType" SG_ 657 ZCUR_TEvapOrigValid_St 0;
BA_ "GenSigSendType" SG_ 657 ZCUR_TDuctLVValid_St 0;
BA_ "GenSigSendType" SG_ 657 ZCUR_ION_Err 0;
BA_ "GenSigSendType" SG_ 657 ZCUR_PM25Sensor_Err 0;
BA_ "GenSigSendType" SG_ 657 ZCUR_CmpmtInAirPmDnsty_Val 0;
BA_ "GenSigSendType" SG_ 657 ZCUR_CmpmtInAirPmAQI_St 0;
BA_ "GenSigSendType" SG_ 912 ZCUR_RRHdl_Err 0;
BA_ "GenSigSendType" SG_ 912 ZCUR_FRHdlWork_St 0;
BA_ "GenSigSendType" SG_ 912 ZCUR_RRHdlWork_St 0;
BA_ "GenSigSendType" SG_ 912 ZCUR_FRHdl_Err 0;
BA_ "GenSigSendType" SG_ 912 ZCUR_FRSeatHt_Rsp 0;
BA_ "GenSigSendType" SG_ 912 ZCUR_FRSeatHtStpRsn_St 0;
BA_ "GenSigSendType" SG_ 912 ZCUR_FRSeatVtlt_Rsp 0;
BA_ "GenSigSendType" SG_ 912 ZCUR_FRSeatVtltStpRsn_St 0;
BA_ "GenSigSendType" SG_ 912 ZCUR_RExMirHt_Rsp 0;
BA_ "GenSigSendType" SG_ 912 ZCUR_RExMirHtStpRsn_St 0;
BA_ "GenSigSendType" SG_ 1472 ZCUR_HSDLVPower_Err 2;
BA_ "GenSigSendType" SG_ 1472 ZCUR_HSDLVPower_St 2;
BA_ "GenSigSendType" SG_ 1472 ZCUR_PERMLVPower_Err 2;
BA_ "GenSigSendType" SG_ 1472 ZCUR_PERMLVPower_St 2;
BA_ "GenSigSendType" SG_ 1472 ZCUR_FRSeatHgtAdjLn_St 0;
BA_ "GenSigSendType" SG_ 1472 ZCUR_FRSeatCshnAngAdjLn_St 0;
BA_ "GenSigSendType" SG_ 1472 ZCUR_FRLegAngCshnExtLn_St 0;
BA_ "GenSigSendType" SG_ 1472 ZCUR_FRWinStpRsn_St 2;
BA_ "GenSigSendType" SG_ 1472 ZCUR_RRWinStpRsn_St 2;
BA_ "GenSigSendType" SG_ 1472 ZCUR_FRWinStp_Req 2;
BA_ "GenSigSendType" SG_ 1472 ZCUR_RRWinStp_Req 2;
BA_ "GenSigSendType" SG_ 1472 ZCUR_FRHdlFrzLn_Val 0;
BA_ "GenSigSendType" SG_ 1472 ZCUR_RRHdlFrzLn_Val 0;
BA_ "GenSigSendType" SG_ 1472 ZCUR_FRHdlFrzLnTime_Val 0;
BA_ "GenSigSendType" SG_ 1472 ZCUR_RRHdlFrzLnTime_Val 0;
BA_ "GenSigSendType" SG_ 1472 ZCUR_FRSeatFBAdjLn_St 0;
BA_ "GenSigSendType" SG_ 1472 ZCUR_FRSeatBackrestAdjLn_St 0;
BA_ "GenSigSendType" SG_ 658 ZCUR_FRDrPdlLtWrk_St 2;
BA_ "GenSigSendType" SG_ 658 ZCUR_RRDrPdlLtWrk_St 2;
BA_ "GenSigSendType" SG_ 658 ZCUR_RLMirLtWrk_St 2;
BA_ "GenSigSendType" SG_ 1106 ZCUR_NodeAddress_VB1 0;
BA_ "GenSigSendType" SG_ 1106 ZCUR_RepeatMsgReq_VB1 0;
BA_ "GenSigSendType" SG_ 1106 ZCUR_ActiveWakeup_VB1 0;
BA_ "GenSigSendType" SG_ 1106 ZCUR_PartialNetworkInfo_VB1 0;
BA_ "GenSigSendType" SG_ 1106 ZCUR_RepeatMsgSt_VB1 0;
BA_ "GenSigSendType" SG_ 1106 ZCUR_PN_HDBT_VB1 0;
BA_ "GenSigSendType" SG_ 1106 ZCUR_PN_HDBI_VB1 0;
BA_ "GenSigSendType" SG_ 1106 ZCUR_PN_HDBA_VB1 0;
BA_ "GenSigSendType" SG_ 1106 ZCUR_PN_HDBM_VB1 0;
BA_ "GenSigSendType" SG_ 1106 ZCUR_PN_ZCUF_VB1 0;
BA_ "GenSigSendType" SG_ 1106 ZCUR_PN_ZCUL_VB1 0;
BA_ "GenSigSendType" SG_ 1106 ZCUR_PN_ZCUR_VB1 0;
BA_ "GenSigSendType" SG_ 1106 ZCUR_PN_ZCUT_VB1 0;
BA_ "GenSigSendType" SG_ 1414 ZCUR_WakeupReq_HDBT 2;
BA_ "GenSigSendType" SG_ 1414 ZCUR_WakeupReq_HDBI 2;
BA_ "GenSigSendType" SG_ 1414 ZCUR_WakeupReq_HDBA 2;
BA_ "GenSigSendType" SG_ 1414 ZCUR_WakeupReq_HDBM 2;
BA_ "GenSigSendType" SG_ 1414 ZCUR_WakeupReq_ZCUF 2;
BA_ "GenSigSendType" SG_ 1414 ZCUR_WakeupReq_ZCUL 2;
BA_ "GenSigSendType" SG_ 1414 ZCUR_WakeupReq_ZCUR 2;
BA_ "GenSigSendType" SG_ 1414 ZCUR_WakeupReq_ZCUT 2;
BA_ "GenSigSendType" SG_ 1495 ZCUR_VB1_NetworkReqCondition0 0;
BA_ "GenSigSendType" SG_ 1495 ZCUR_VB1_NetworkReqCondition1 0;
BA_ "GenSigSendType" SG_ 1495 ZCUR_VB1_NetworkReqCondition2 0;
BA_ "GenSigSendType" SG_ 1495 ZCUR_VB1_NetworkReqCondition3 0;
BA_ "GenSigSendType" SG_ 1495 ZCUR_VB1_NetworkReqCondition4 0;
BA_ "GenSigSendType" SG_ 1495 ZCUR_VB1_NetworkReqCondition5 0;
BA_ "GenSigSendType" SG_ 1495 ZCUR_VB1_NetworkReqCondition6 0;
BA_ "GenSigSendType" SG_ 1495 ZCUR_VB1_NetworkReqCondition7 0;
BA_ "GenSigSendType" SG_ 1495 ZCUR_VB1_NetworkReqCondition8 0;
BA_ "GenSigSendType" SG_ 1495 ZCUR_VB1_NetworkReqCondition9 0;
BA_ "GenSigSendType" SG_ 1495 ZCUR_VB1_NetworkReqCondition10 0;
BA_ "GenSigSendType" SG_ 1495 ZCUR_VB1_NetworkReqCondition11 0;
BA_ "GenSigSendType" SG_ 1495 ZCUR_VB1_NetworkReqCondition12 0;
BA_ "GenSigSendType" SG_ 1495 ZCUR_VB1_NetworkReqCondition13 0;
BA_ "GenSigSendType" SG_ 1495 ZCUR_VB1_NetworkReqCondition14 0;
BA_ "GenSigSendType" SG_ 1495 ZCUR_VB1_NetworkReqCondition15 0;
BA_ "GenSigSendType" SG_ 1495 ZCUR_VB1_NetworkReqCondition16 0;
BA_ "GenSigSendType" SG_ 1495 ZCUR_VB1_NetworkReqCondition17 0;
BA_ "GenSigSendType" SG_ 1495 ZCUR_VB1_NetworkReqCondition18 0;
BA_ "GenSigSendType" SG_ 1495 ZCUR_VB1_NetworkReqCondition19 0;
BA_ "GenSigSendType" SG_ 1495 ZCUR_VB1_NetworkReqCondition20 0;
BA_ "GenSigSendType" SG_ 1495 ZCUR_VB1_NetworkReqCondition21 0;
BA_ "GenSigSendType" SG_ 1495 ZCUR_VB1_NetworkReqCondition22 0;
BA_ "GenSigSendType" SG_ 1495 ZCUR_VB1_NetworkReqCondition23 0;
BA_ "GenSigSendType" SG_ 1495 ZCUR_VB1_NetworkReqCondition24 0;
BA_ "GenSigSendType" SG_ 1495 ZCUR_VB1_NetworkReqCondition25 0;
BA_ "GenSigSendType" SG_ 1495 ZCUR_VB1_NetworkReqCondition26 0;
BA_ "GenSigSendType" SG_ 1495 ZCUR_VB1_NetworkReqCondition27 0;
BA_ "GenSigSendType" SG_ 1495 ZCUR_VB1_NetworkReqCondition28 0;
BA_ "GenSigSendType" SG_ 1495 ZCUR_VB1_NetworkReqCondition29 0;
BA_ "GenSigSendType" SG_ 1495 ZCUR_VB1_NetworkReqCondition30 0;
BA_ "GenSigSendType" SG_ 1495 ZCUR_VB1_NetworkReqCondition31 0;
BA_ "GenSigStartValue" SG_ 431 ZCUR_FRSeatCshnAngPst_Val 126;
BA_ "GenSigSendType" SG_ 431 ZCUR_FRSeatCshnAngPst_Val 0;
BA_ "GenSigStartValue" SG_ 431 ZCUR_FRLegAngCshnExtPst_Val 126;
BA_ "GenSigSendType" SG_ 431 ZCUR_FRLegAngCshnExtPst_Val 0;
BA_ "GenSigStartValue" SG_ 431 ZCUR_FRSeatFBPst_Val 126;
BA_ "GenSigSendType" SG_ 431 ZCUR_FRSeatFBPst_Val 0;
BA_ "GenSigStartValue" SG_ 431 ZCUR_FRSeatBackrestPst_Val 126;
BA_ "GenSigSendType" SG_ 431 ZCUR_FRSeatBackrestPst_Val 0;
BA_ "GenSigStartValue" SG_ 431 ZCUR_FRSeatHgtPst_Val 126;
BA_ "GenSigSendType" SG_ 431 ZCUR_FRSeatHgtPst_Val 0;
BA_ "GenSigStartValue" SG_ 431 ZCUR_RExMirUDPst_Val 126;
BA_ "GenSigSendType" SG_ 431 ZCUR_RExMirUDPst_Val 0;
BA_ "GenSigStartValue" SG_ 431 ZCUR_RExMirLRPst_Val 126;
BA_ "GenSigSendType" SG_ 431 ZCUR_RExMirLRPst_Val 0;
BA_ "GenSigSendType" SG_ 112 ZCUL_Checksum1 7;
BA_ "GenSigSendType" SG_ 112 ZCUL_RollingCounter1 7;
BA_ "GenSigSendType" SG_ 112 ZCUL_HzrdWngSw_St 0;
BA_ "GenSigSendType" SG_ 112 ZCUL_SFLTnLt_St 0;
BA_ "GenSigStartValue" SG_ 112 ZCUL_BrakeSwNC_St 1;
BA_ "GenSigSendType" SG_ 112 ZCUL_BrakeSwNC_St 0;
BA_ "GenSigSendType" SG_ 112 ZCUL_FLSeatOcp_St 0;
BA_ "GenSigSendType" SG_ 112 ZCUL_BrakeSwNO_St 0;
BA_ "GenSigSendType" SG_ 400 ZCUL_FLSeatHgtAdj_Req 0;
BA_ "GenSigSendType" SG_ 400 ZCUL_FLLthPawl_St 0;
BA_ "GenSigSendType" SG_ 400 ZCUL_FLSeatCshnAngAdj_Req 0;
BA_ "GenSigSendType" SG_ 400 ZCUL_RLLthPawl_St 0;
BA_ "GenSigSendType" SG_ 400 ZCUL_FLHdlOprt_St 0;
BA_ "GenSigSendType" SG_ 400 ZCUL_RLHdlOprt_St 0;
BA_ "GenSigSendType" SG_ 400 ZCUL_FLDrIntSW_St 0;
BA_ "GenSigSendType" SG_ 400 ZCUL_RLDrIntSW_St 0;
BA_ "GenSigSendType" SG_ 400 ZCUL_FLLthAjar_St 0;
BA_ "GenSigSendType" SG_ 400 ZCUL_RLLthAjar_St 0;
BA_ "GenSigSendType" SG_ 400 ZCUL_FLSeatAdj_Req 0;
BA_ "GenSigSendType" SG_ 400 ZCUL_FLLthHlfLck_St 0;
BA_ "GenSigSendType" SG_ 400 ZCUL_FLSeatBackrestAdj_Req 0;
BA_ "GenSigSendType" SG_ 400 ZCUL_RLLthHlfLck_St 0;
BA_ "GenSigSendType" SG_ 400 ZCUL_Checksum2 7;
BA_ "GenSigSendType" SG_ 400 ZCUL_RollingCounter2 7;
BA_ "GenSigSendType" SG_ 400 ZCUL_FLSeatLegAngCshnExtAdj_Req 0;
BA_ "GenSigStartValue" SG_ 400 ZCUL_SteerTiltPst_Val 254;
BA_ "GenSigSendType" SG_ 400 ZCUL_SteerTiltPst_Val 0;
BA_ "GenSigStartValue" SG_ 400 ZCUL_SteerTelePst_Val 254;
BA_ "GenSigSendType" SG_ 400 ZCUL_SteerTelePst_Val 0;
BA_ "GenSigSendType" SG_ 400 ZCUL_FLWinPst_Rsp 0;
BA_ "GenSigSendType" SG_ 400 ZCUL_RLWinPst_Rsp 0;
BA_ "GenSigStartValue" SG_ 400 ZCUL_LExMirUDPst_Val 126;
BA_ "GenSigSendType" SG_ 400 ZCUL_LExMirUDPst_Val 0;
BA_ "GenSigStartValue" SG_ 400 ZCUL_LExMirLRPst_Val 126;
BA_ "GenSigSendType" SG_ 400 ZCUL_LExMirLRPst_Val 0;
BA_ "GenSigStartValue" SG_ 400 ZCUL_FLSeatFBPst_Val 126;
BA_ "GenSigSendType" SG_ 400 ZCUL_FLSeatFBPst_Val 0;
BA_ "GenSigStartValue" SG_ 400 ZCUL_FLSeatBackrestPst_Val 126;
BA_ "GenSigSendType" SG_ 400 ZCUL_FLSeatBackrestPst_Val 0;
BA_ "GenSigStartValue" SG_ 400 ZCUL_FLSeatHgtPst_Val 126;
BA_ "GenSigSendType" SG_ 400 ZCUL_FLSeatHgtPst_Val 0;
BA_ "GenSigStartValue" SG_ 400 ZCUL_FLSeatCshnAngPst_Val 126;
BA_ "GenSigSendType" SG_ 400 ZCUL_FLSeatCshnAngPst_Val 0;
BA_ "GenSigStartValue" SG_ 400 ZCUL_FLLegAngCshnExtPst_Val 126;
BA_ "GenSigSendType" SG_ 400 ZCUL_FLLegAngCshnExtPst_Val 0;
BA_ "GenSigSendType" SG_ 896 ZCUL_FLHdl_Err 0;
BA_ "GenSigSendType" SG_ 896 ZCUL_FLHdlWork_St 0;
BA_ "GenSigSendType" SG_ 896 ZCUL_RLHdlWork_St 0;
BA_ "GenSigSendType" SG_ 896 ZCUL_RLHdl_Err 0;
BA_ "GenSigSendType" SG_ 896 ZCUL_SteerTeleLn_St 0;
BA_ "GenSigSendType" SG_ 896 ZCUL_SteerTiltLn_St 0;
BA_ "GenSigSendType" SG_ 896 ZCUL_SteerHtStpRsn_St 0;
BA_ "GenSigSendType" SG_ 896 ZCUL_SteerHt_Rsp 0;
BA_ "GenSigSendType" SG_ 896 ZCUL_FLSeatHtStpRsn_St 0;
BA_ "GenSigSendType" SG_ 896 ZCUL_FLSeatVtlt_Rsp 0;
BA_ "GenSigSendType" SG_ 896 ZCUL_FLSeatVtltStpRsn_St 0;
BA_ "GenSigSendType" SG_ 896 ZCUL_LExMirHt_Rsp 0;
BA_ "GenSigSendType" SG_ 896 ZCUL_LExMirHtStpRsn_St 0;
BA_ "GenSigSendType" SG_ 896 ZCUL_FLSeatHt_Rsp 0;
BA_ "GenSigSendType" SG_ 1408 ZCUL_PERMLVPower_Err 2;
BA_ "GenSigSendType" SG_ 1408 ZCUL_HSDLVPower_St 2;
BA_ "GenSigSendType" SG_ 1408 ZCUL_HSDLVPower_Err 2;
BA_ "GenSigSendType" SG_ 1408 ZCUL_PERMLVPower_St 2;
BA_ "GenSigSendType" SG_ 1408 ZCUL_FLHdlFrzLn_Val 0;
BA_ "GenSigSendType" SG_ 1408 ZCUL_RLHdlFrzLn_Val 0;
BA_ "GenSigSendType" SG_ 1408 ZCUL_FLHdlFrzLnTime_Val 0;
BA_ "GenSigSendType" SG_ 1408 ZCUL_RLHdlFrzLnTime_Val 0;
BA_ "GenSigSendType" SG_ 1408 ZCUL_FLSeatFBAdjLn_St 0;
BA_ "GenSigSendType" SG_ 1408 ZCUL_FLSeatBackrestAdjLn_St 0;
BA_ "GenSigSendType" SG_ 1408 ZCUL_FLSeatHgtAdjLn_St 0;
BA_ "GenSigSendType" SG_ 1408 ZCUL_FLSeatCshnAngAdjLn_St 0;
BA_ "GenSigSendType" SG_ 1408 ZCUL_FLLegAngCshnExtLn_St 0;
BA_ "GenSigSendType" SG_ 1408 ZCUL_FLWinStpRsn_St 2;
BA_ "GenSigSendType" SG_ 1408 ZCUL_RLWinStpRsn_St 2;
BA_ "GenSigSendType" SG_ 1408 ZCUL_FLWinStp_Req 2;
BA_ "GenSigSendType" SG_ 1408 ZCUL_RLWinStp_Req 2;
BA_ "GenSigSendType" SG_ 672 ZCUL_FLDrPdlLtWrk_St 2;
BA_ "GenSigSendType" SG_ 672 ZCUL_RLDrPdlLtWrk_St 2;
BA_ "GenSigSendType" SG_ 672 ZCUL_BckLtWrk_St 2;
BA_ "GenSigSendType" SG_ 672 ZCUL_EnSvLtWrk_St 2;
BA_ "GenSigSendType" SG_ 673 ZCUL_RLWinSw_St 2;
BA_ "GenSigSendType" SG_ 673 ZCUL_FLWdwMov_St 2;
BA_ "GenSigSendType" SG_ 673 ZCUL_RLHdlFrz_St 2;
BA_ "GenSigSendType" SG_ 673 ZCUL_RLWdwMov_St 2;
BA_ "GenSigSendType" SG_ 673 ZCUL_FLLthHome_St 2;
BA_ "GenSigSendType" SG_ 673 ZCUL_RLLthHome_St 2;
BA_ "GenSigSendType" SG_ 673 ZCUL_FLDrLth_St 2;
BA_ "GenSigSendType" SG_ 673 ZCUL_SFLTnLtErr_St 2;
BA_ "GenSigSendType" SG_ 673 ZCUL_FLHdlClsPstSW_St 2;
BA_ "GenSigSendType" SG_ 673 ZCUL_RLDrLth_St 2;
BA_ "GenSigSendType" SG_ 673 ZCUL_FLDrLthWrk_St 2;
BA_ "GenSigSendType" SG_ 673 ZCUL_RLHdlClsPstSW_St 2;
BA_ "GenSigSendType" SG_ 673 ZCUL_FLHdlStpRsn_St 2;
BA_ "GenSigSendType" SG_ 673 ZCUL_FLHdlOpnPstSW_St 2;
BA_ "GenSigSendType" SG_ 673 ZCUL_RLDrLthWrk_St 2;
BA_ "GenSigSendType" SG_ 673 ZCUL_RLHdlStpRsn_St 2;
BA_ "GenSigSendType" SG_ 673 ZCUL_FLDrStpRsn_St 2;
BA_ "GenSigSendType" SG_ 673 ZCUL_RLHdlOpnPstSW_St 2;
BA_ "GenSigSendType" SG_ 673 ZCUL_RLDrStpRsn_St 2;
BA_ "GenSigSendType" SG_ 673 ZCUL_FLDrLth_Err 2;
BA_ "GenSigSendType" SG_ 673 ZCUL_RLDrLth_Err 2;
BA_ "GenSigSendType" SG_ 673 ZCUL_LExMirCtrl_Rsp 2;
BA_ "GenSigSendType" SG_ 673 ZCUL_HornSwitch_St 2;
BA_ "GenSigSendType" SG_ 673 ZCUL_FLHdlFrz_St 2;
BA_ "GenSigSendType" SG_ 673 ZCUL_FLDrStpRsn2_St 2;
BA_ "GenSigSendType" SG_ 673 ZCUL_FLDrLthWrk2_St 2;
BA_ "GenSigSendType" SG_ 673 ZCUL_RLDrStpRsn2_St 2;
BA_ "GenSigSendType" SG_ 673 ZCUL_RLDrLthWrk2_St 2;
BA_ "GenSigSendType" SG_ 673 ZCUL_FLLumbSuppUDAdj_Req 2;
BA_ "GenSigSendType" SG_ 673 ZCUL_FLSunshadeSW_St 2;
BA_ "GenSigSendType" SG_ 673 ZCUL_FLLumbSuppFBAdj_Req 2;
BA_ "GenSigSendType" SG_ 673 ZCUL_FLDrLth2_Err 2;
BA_ "GenSigSendType" SG_ 673 ZCUL_RLDrLth2_Err 2;
BA_ "GenSigSendType" SG_ 673 ZCUL_SteerTiltMv_St 2;
BA_ "GenSigSendType" SG_ 673 ZCUL_SteerTeleMv_St 2;
BA_ "GenSigSendType" SG_ 673 ZCUL_SteerTiltStpRsn_St 2;
BA_ "GenSigSendType" SG_ 673 ZCUL_SteerTiltStp_Req 2;
BA_ "GenSigSendType" SG_ 673 ZCUL_SteerTeleStpRsn_St 2;
BA_ "GenSigSendType" SG_ 673 ZCUL_SteerTeleStp_Req 2;
BA_ "GenSigSendType" SG_ 673 ZCUL_LExMirUDMv_St 2;
BA_ "GenSigSendType" SG_ 673 ZCUL_LExMirLRMv_St 2;
BA_ "GenSigSendType" SG_ 673 ZCUL_LExMirUDStpRsn_St 2;
BA_ "GenSigSendType" SG_ 673 ZCUL_LExMirUDStp_Req 2;
BA_ "GenSigSendType" SG_ 673 ZCUL_LExMirLRStpRsn_St 2;
BA_ "GenSigSendType" SG_ 673 ZCUL_LExMirLRStp_Req 2;
BA_ "GenSigSendType" SG_ 673 ZCUL_FLSeatCshnAngStpRsn_St 2;
BA_ "GenSigSendType" SG_ 673 ZCUL_FLSeatCshnAngStp_Req 2;
BA_ "GenSigSendType" SG_ 673 ZCUL_FLLegAngCshnExtStpRsn_St 2;
BA_ "GenSigSendType" SG_ 673 ZCUL_FLLegAngCshnExtStp_Req 2;
BA_ "GenSigSendType" SG_ 673 ZCUL_FLSeatFBMv_St 2;
BA_ "GenSigSendType" SG_ 673 ZCUL_FLSeatBackrestMv_St 2;
BA_ "GenSigSendType" SG_ 673 ZCUL_FLSeatHgtMv_St 2;
BA_ "GenSigSendType" SG_ 673 ZCUL_FLSeatCshnAngMv_St 2;
BA_ "GenSigSendType" SG_ 673 ZCUL_FLLegAngCshnExtMv_St 2;
BA_ "GenSigSendType" SG_ 673 ZCUL_FLSeatFBStpRsn_St 2;
BA_ "GenSigSendType" SG_ 673 ZCUL_FLSeatFBStp_Req 2;
BA_ "GenSigSendType" SG_ 673 ZCUL_FLSeatBackrestStpRsn_St 2;
BA_ "GenSigSendType" SG_ 673 ZCUL_FLSeatBackrestStp_Req 2;
BA_ "GenSigSendType" SG_ 673 ZCUL_FLSeatHgtStpRsn_St 2;
BA_ "GenSigSendType" SG_ 673 ZCUL_FLSeatHgtStp_Req 2;
BA_ "GenSigSendType" SG_ 673 ZCUL_FLHdlDbOprt_St 2;
BA_ "GenSigSendType" SG_ 673 ZCUL_RLHdlDbOprt_St 2;
BA_ "GenSigSendType" SG_ 673 ZCUL_LExMirCtrlMv_St 2;
BA_ "GenSigSendType" SG_ 673 ZCUL_LExMirCtrlStpRsn_St 2;
BA_ "GenSigSendType" SG_ 673 ZCUL_LExMirCtrlStp_Req 2;
BA_ "GenSigSendType" SG_ 401 SWSR_TouchPadDownSw_St 0;
BA_ "GenSigSendType" SG_ 401 SWSR_TouchPadLeftSw_St 0;
BA_ "GenSigSendType" SG_ 401 SWSR_TouchPadRightSw_St 0;
BA_ "GenSigSendType" SG_ 401 SWSR_TouchPadUpSw_St 0;
BA_ "GenSigSendType" SG_ 401 DISFL_FRWinCtl_Req 0;
BA_ "GenSigSendType" SG_ 401 DISFL_RLWinCtl_Req 0;
BA_ "GenSigSendType" SG_ 401 DISFL_RRWinCtl_Req 0;
BA_ "GenSigSendType" SG_ 401 DISFL_DrvCtLckSW_Req 0;
BA_ "GenSigSendType" SG_ 401 DISFL_FLWinCtl_Req 0;
BA_ "GenSigSendType" SG_ 401 TL_FLTpLtClr_St 0;
BA_ "GenSigSendType" SG_ 401 TL_RLTpLtClr_St 0;
BA_ "GenSigSendType" SG_ 401 TL_FRTpLtClr_St 0;
BA_ "GenSigSendType" SG_ 401 TL_RRTpLtClr_St 0;
BA_ "GenSigSendType" SG_ 401 TL_FLTchBtn_St 0;
BA_ "GenSigSendType" SG_ 401 TL_FLTpLtBrt_Val 0;
BA_ "GenSigSendType" SG_ 401 TL_RLTchBtn_St 0;
BA_ "GenSigSendType" SG_ 401 TL_RLTpLtBrt_Val 0;
BA_ "GenSigSendType" SG_ 401 TL_FRTchBtn_St 0;
BA_ "GenSigSendType" SG_ 401 TL_FRTpLtBrt_Val 0;
BA_ "GenSigSendType" SG_ 401 TL_RRTchBtn_St 0;
BA_ "GenSigSendType" SG_ 401 TL_RRTpLtBrt_Val 0;
BA_ "GenSigStartValue" SG_ 401 ZCUL_FD_RT_1_SWSRAvailable_St 1;
BA_ "GenSigSendType" SG_ 401 ZCUL_FD_RT_1_SWSRAvailable_St 0;
BA_ "GenSigStartValue" SG_ 401 ZCUL_FD_RT_1_DISFLAvailable_St 1;
BA_ "GenSigSendType" SG_ 401 ZCUL_FD_RT_1_DISFLAvailable_St 0;
BA_ "GenSigStartValue" SG_ 401 ZCUL_FD_RT_1_TLAvailable_St 1;
BA_ "GenSigSendType" SG_ 401 ZCUL_FD_RT_1_TLAvailable_St 0;
BA_ "GenSigStartValue" SG_ 403 CSM_FwiperSW_St 7;
BA_ "GenSigSendType" SG_ 403 CSM_FwiperSW_St 0;
BA_ "GenSigSendType" SG_ 403 CSM_TurnLightSw_St 0;
BA_ "GenSigSendType" SG_ 403 CSM_FMistWashSW_St 0;
BA_ "GenSigSendType" SG_ 403 CSM_HighBeamSw_St 0;
BA_ "GenSigSendType" SG_ 403 CSM_Checksum1 0;
BA_ "GenSigSendType" SG_ 403 CSM_RollingCounter1 0;
BA_ "GenSigSendType" SG_ 403 CSM_FWiperLO_Err 0;
BA_ "GenSigSendType" SG_ 403 CSM_FWiperHI_Err 0;
BA_ "GenSigSendType" SG_ 403 CSM_FMistSW_Err 0;
BA_ "GenSigSendType" SG_ 403 CSM_FWashSW_Err 0;
BA_ "GenSigSendType" SG_ 403 CSM_FWiperOFF_Err 0;
BA_ "GenSigSendType" SG_ 403 CSM_FWiperAuto1_Err 0;
BA_ "GenSigSendType" SG_ 403 CSM_FWiperAuto2_Err 0;
BA_ "GenSigSendType" SG_ 1482 ZCUL_VB1_NetworkReqCondition0 0;
BA_ "GenSigSendType" SG_ 1482 ZCUL_VB1_NetworkReqCondition1 0;
BA_ "GenSigSendType" SG_ 1482 ZCUL_VB1_NetworkReqCondition2 0;
BA_ "GenSigSendType" SG_ 1482 ZCUL_VB1_NetworkReqCondition3 0;
BA_ "GenSigSendType" SG_ 1482 ZCUL_VB1_NetworkReqCondition4 0;
BA_ "GenSigSendType" SG_ 1482 ZCUL_VB1_NetworkReqCondition5 0;
BA_ "GenSigSendType" SG_ 1482 ZCUL_VB1_NetworkReqCondition6 0;
BA_ "GenSigSendType" SG_ 1482 ZCUL_VB1_NetworkReqCondition7 0;
BA_ "GenSigSendType" SG_ 1482 ZCUL_VB1_NetworkReqCondition8 0;
BA_ "GenSigSendType" SG_ 1482 ZCUL_VB1_NetworkReqCondition9 0;
BA_ "GenSigSendType" SG_ 1482 ZCUL_VB1_NetworkReqCondition10 0;
BA_ "GenSigSendType" SG_ 1482 ZCUL_VB1_NetworkReqCondition11 0;
BA_ "GenSigSendType" SG_ 1482 ZCUL_VB1_NetworkReqCondition12 0;
BA_ "GenSigSendType" SG_ 1482 ZCUL_VB1_NetworkReqCondition13 0;
BA_ "GenSigSendType" SG_ 1482 ZCUL_VB1_NetworkReqCondition14 0;
BA_ "GenSigSendType" SG_ 1482 ZCUL_VB1_NetworkReqCondition15 0;
BA_ "GenSigSendType" SG_ 1482 ZCUL_VB1_NetworkReqCondition16 0;
BA_ "GenSigSendType" SG_ 1482 ZCUL_VB1_NetworkReqCondition17 0;
BA_ "GenSigSendType" SG_ 1482 ZCUL_VB1_NetworkReqCondition18 0;
BA_ "GenSigSendType" SG_ 1482 ZCUL_VB1_NetworkReqCondition19 0;
BA_ "GenSigSendType" SG_ 1482 ZCUL_VB1_NetworkReqCondition20 0;
BA_ "GenSigSendType" SG_ 1482 ZCUL_VB1_NetworkReqCondition21 0;
BA_ "GenSigSendType" SG_ 1482 ZCUL_VB1_NetworkReqCondition22 0;
BA_ "GenSigSendType" SG_ 1482 ZCUL_VB1_NetworkReqCondition23 0;
BA_ "GenSigSendType" SG_ 1482 ZCUL_VB1_NetworkReqCondition24 0;
BA_ "GenSigSendType" SG_ 1482 ZCUL_VB1_NetworkReqCondition25 0;
BA_ "GenSigSendType" SG_ 1482 ZCUL_VB1_NetworkReqCondition26 0;
BA_ "GenSigSendType" SG_ 1482 ZCUL_VB1_NetworkReqCondition27 0;
BA_ "GenSigSendType" SG_ 1482 ZCUL_VB1_NetworkReqCondition28 0;
BA_ "GenSigSendType" SG_ 1482 ZCUL_VB1_NetworkReqCondition29 0;
BA_ "GenSigSendType" SG_ 1482 ZCUL_VB1_NetworkReqCondition30 0;
BA_ "GenSigSendType" SG_ 1482 ZCUL_VB1_NetworkReqCondition31 0;
BA_ "GenSigSendType" SG_ 1415 ZCUL_WakeupReq_HDBT 2;
BA_ "GenSigSendType" SG_ 1415 ZCUL_WakeupReq_HDBI 2;
BA_ "GenSigSendType" SG_ 1415 ZCUL_WakeupReq_HDBA 2;
BA_ "GenSigSendType" SG_ 1415 ZCUL_WakeupReq_HDBM 2;
BA_ "GenSigSendType" SG_ 1415 ZCUL_WakeupReq_ZCUF 2;
BA_ "GenSigSendType" SG_ 1415 ZCUL_WakeupReq_ZCUL 2;
BA_ "GenSigSendType" SG_ 1415 ZCUL_WakeupReq_ZCUR 2;
BA_ "GenSigSendType" SG_ 1415 ZCUL_WakeupReq_ZCUT 2;
BA_ "GenSigSendType" SG_ 1107 ZCUL_NodeAddress_VB1 0;
BA_ "GenSigSendType" SG_ 1107 ZCUL_RepeatMsgReq_VB1 0;
BA_ "GenSigSendType" SG_ 1107 ZCUL_ActiveWakeup_VB1 0;
BA_ "GenSigSendType" SG_ 1107 ZCUL_PartialNetworkInfo_VB1 0;
BA_ "GenSigSendType" SG_ 1107 ZCUL_RepeatMsgSt_VB1 0;
BA_ "GenSigSendType" SG_ 1107 ZCUL_PN_HDBT_VB1 0;
BA_ "GenSigSendType" SG_ 1107 ZCUL_PN_HDBI_VB1 0;
BA_ "GenSigSendType" SG_ 1107 ZCUL_PN_HDBA_VB1 0;
BA_ "GenSigSendType" SG_ 1107 ZCUL_PN_HDBM_VB1 0;
BA_ "GenSigSendType" SG_ 1107 ZCUL_PN_ZCUF_VB1 0;
BA_ "GenSigSendType" SG_ 1107 ZCUL_PN_ZCUL_VB1 0;
BA_ "GenSigSendType" SG_ 1107 ZCUL_PN_ZCUR_VB1 0;
BA_ "GenSigSendType" SG_ 1107 ZCUL_PN_ZCUT_VB1 0;
BA_ "GenSigSendType" SG_ 320 ZCUF_RegenPwrPct_Val 0;
BA_ "GenSigSendType" SG_ 320 ZCUF_CurrActlDrvPwr_Val 0;
BA_ "GenSigSendType" SG_ 320 ZCUF_FWiperParkAreaSW_St 0;
BA_ "GenSigSendType" SG_ 320 ZCUF_CurrActlBrakePwr_Val 0;
BA_ "GenSigSendType" SG_ 320 ZCUF_CurrLimitDrivePwrPct_Val 0;
BA_ "GenSigSendType" SG_ 320 ZCUF_CurrLimitBrakePwrPct_Val 0;
BA_ "GenSigSendType" SG_ 528 ZCUF_ACTotLimPwr_Val 0;
BA_ "GenSigSendType" SG_ 528 ZCUF_ECFActualSpdPct_Val 0;
BA_ "GenSigSendType" SG_ 528 ZCUF_EcfFlt_St 0;
BA_ "GenSigSendType" SG_ 528 ZCUF_FLHighLgt_St 0;
BA_ "GenSigSendType" SG_ 528 ZCUF_FRHighLgt_St 0;
BA_ "GenSigSendType" SG_ 528 ZCUF_StdSenarioMileage_Val 0;
BA_ "GenSigStartValue" SG_ 528 ZCUF_RESSInletTargTemp_Req 60;
BA_ "GenSigSendType" SG_ 528 ZCUF_RESSInletTargTemp_Req 0;
BA_ "GenSigSendType" SG_ 528 ZCUF_Ready_St 0;
BA_ "GenSigSendType" SG_ 528 ZCUF_PackThmlMode_Req 0;
BA_ "GenSigSendType" SG_ 528 ZCUF_HighVoltage_St 0;
BA_ "GenSigSendType" SG_ 528 ZCUF_AGSFaultSt_Err 0;
BA_ "GenSigSendType" SG_ 528 ZCUF_AGSActAng_Val 0;
BA_ "GenSigSendType" SG_ 528 ZCUF_TractionModeSet_Rsp 0;
BA_ "GenSigSendType" SG_ 528 ZCUF_FLTnLgtErr_St 0;
BA_ "GenSigSendType" SG_ 528 ZCUF_FRTnLgtErr_St 0;
BA_ "GenSigSendType" SG_ 528 ZCUF_Checksum5 7;
BA_ "GenSigSendType" SG_ 528 ZCUF_RollingCounter5 7;
BA_ "GenSigSendType" SG_ 528 ZCUF_CoolSysInletTemp_Val 0;
BA_ "GenSigSendType" SG_ 528 ZCUF_CoolSysOutletTemp_Val 0;
BA_ "GenSigSendType" SG_ 1424 ZCUF_HSDLVPower_St 2;
BA_ "GenSigSendType" SG_ 1424 ZCUF_HSDLVPower_Err 2;
BA_ "GenSigSendType" SG_ 1424 ZCUF_PERMLVPower_St 2;
BA_ "GenSigSendType" SG_ 1424 ZCUF_PERMLVPower_Err 2;
BA_ "GenSigSendType" SG_ 1424 ZCUF_AvgEnergyConsume_Val 0;
BA_ "GenSigSendType" SG_ 513 ZCUF_AbnormalShiftInfo_Err 2;
BA_ "GenSigSendType" SG_ 513 ZCUF_ThmlRunawayWarn_St 2;
BA_ "GenSigSendType" SG_ 513 ZCUF_Shift_Err 0;
BA_ "GenSigSendType" SG_ 513 ZCUF_PullOver_St 2;
BA_ "GenSigSendType" SG_ 513 ZCUF_BrakeLightOn_Req 2;
BA_ "GenSigSendType" SG_ 513 ZCUF_HVOffConfirm_Req 2;
BA_ "GenSigSendType" SG_ 513 ZCUF_PTFaultLgtClr_St 2;
BA_ "GenSigSendType" SG_ 513 ZCUF_AntiTheft_St 2;
BA_ "GenSigSendType" SG_ 513 ZCUF_LowVoltSys_Err 2;
BA_ "GenSigSendType" SG_ 513 ZCUF_MotorOverTemp_St 2;
BA_ "GenSigSendType" SG_ 513 ZCUF_PTHMI_Req 2;
BA_ "GenSigStartValue" SG_ 513 ZCUF_EDCDisTemp_Val 4094;
BA_ "GenSigSendType" SG_ 513 ZCUF_EDCDisTemp_Val 0;
BA_ "GenSigStartValue" SG_ 513 ZCUF_EDCSuncPres_Val 65534;
BA_ "GenSigSendType" SG_ 513 ZCUF_EDCSuncPres_Val 0;
BA_ "GenSigStartValue" SG_ 513 ZCUF_EDCSuncTemp_Val 4094;
BA_ "GenSigSendType" SG_ 513 ZCUF_EDCSuncTemp_Val 0;
BA_ "GenSigStartValue" SG_ 513 ZCUF_EDCDisPres_Val 65534;
BA_ "GenSigSendType" SG_ 513 ZCUF_EDCDisPres_Val 0;
BA_ "GenSigStartValue" SG_ 513 ZCUF_TAmbOrig_Val 4094;
BA_ "GenSigSendType" SG_ 513 ZCUF_TAmbOrig_Val 0;
BA_ "GenSigSendType" SG_ 513 ZCUF_EEMSetPowerLevel_St 0;
BA_ "GenSigSendType" SG_ 880 ZCUF_ACMEnable_Req 2;
BA_ "GenSigSendType" SG_ 880 ZCUF_FLLowLgt_St 2;
BA_ "GenSigSendType" SG_ 880 ZCUF_FRLowLgt_St 2;
BA_ "GenSigSendType" SG_ 880 ZCUF_HoodAjar_St 2;
BA_ "GenSigSendType" SG_ 880 ZCUF_DriveConflictRemindInfo_UI 2;
BA_ "GenSigSendType" SG_ 880 ZCUF_FLPstnLgt_St 2;
BA_ "GenSigSendType" SG_ 880 ZCUF_FRPstnLgt_St 2;
BA_ "GenSigSendType" SG_ 880 ZCUF_PTworkmode_St 2;
BA_ "GenSigSendType" SG_ 880 ZCUF_PtModAvailable_St 2;
BA_ "GenSigSendType" SG_ 880 ZCUF_RegenSetPct_Rsp 2;
BA_ "GenSigStartValue" SG_ 880 ZCUF_Fwiper_St 7;
BA_ "GenSigSendType" SG_ 880 ZCUF_Fwiper_St 2;
BA_ "GenSigSendType" SG_ 880 ZCUF_ServiceReminder_St 2;
BA_ "GenSigSendType" SG_ 880 ZCUF_HoodHalfOrPawl_St 2;
BA_ "GenSigSendType" SG_ 880 ZCUF_TractionModeAvail_St 2;
BA_ "GenSigSendType" SG_ 880 ZCUF_TractionModeRemaind_St 2;
BA_ "GenSigSendType" SG_ 880 ZCUF_FLDyLgt_St 0;
BA_ "GenSigSendType" SG_ 880 ZCUF_FRDyLgt_St 0;
BA_ "GenSigSendType" SG_ 880 ZCUF_LowBattChrgForbid_St 0;
BA_ "GenSigSendType" SG_ 880 ZCUF_PTThmlLiquidLackWarn_St 0;
BA_ "GenSigSendType" SG_ 880 ZCUF_RegenAvail_St 0;
BA_ "GenSigSendType" SG_ 880 ZCUF_LowVoltSysWarnStop_St 2;
BA_ "GenSigSendType" SG_ 880 ZCUF_EmergencyLgtOn_Req 2;
BA_ "GenSigSendType" SG_ 880 ZCUF_HoodLatch_St 2;
BA_ "GenSigStartValue" SG_ 880 ZCUF_WashLqdHgtSW_St 1;
BA_ "GenSigSendType" SG_ 880 ZCUF_WashLqdHgtSW_St 0;
BA_ "GenSigSendType" SG_ 97 EHBM_FLWhlPulse_Val 0;
BA_ "GenSigSendType" SG_ 97 EHBM_FRWhlPulse_Val 0;
BA_ "GenSigSendType" SG_ 97 EHBM_RLWhlPulse_Val 0;
BA_ "GenSigSendType" SG_ 97 EHBM_RRWhlPulse_Val 0;
BA_ "GenSigSendType" SG_ 97 EHBM_FLWhlPulseValid_St 0;
BA_ "GenSigSendType" SG_ 97 EHBM_FRWhlPulseValid_St 0;
BA_ "GenSigSendType" SG_ 97 EHBM_RLWhlPulseValid_St 0;
BA_ "GenSigSendType" SG_ 97 EHBM_RRWhlPulseValid_St 0;
BA_ "GenSigStartValue" SG_ 97 ZCUF_FD_RT_1_EHBMAvailable_St 1;
BA_ "GenSigSendType" SG_ 97 ZCUF_FD_RT_1_EHBMAvailable_St 0;
BA_ "GenSigSendType" SG_ 448 ACCM_ZCUFMissing_St 0;
BA_ "GenSigSendType" SG_ 448 ACCM_VDC_Val 0;
BA_ "GenSigSendType" SG_ 448 ACCM_UvP_St 0;
BA_ "GenSigSendType" SG_ 448 ACCM_UnderHV_St 0;
BA_ "GenSigSendType" SG_ 448 ACCM_TempSensorError 0;
BA_ "GenSigSendType" SG_ 448 ACCM_St 0;
BA_ "GenSigSendType" SG_ 448 ACCM_Speed_Val 0;
BA_ "GenSigSendType" SG_ 448 ACCM_SIC_Err 0;
BA_ "GenSigSendType" SG_ 448 ACCM_Power_Val 0;
BA_ "GenSigSendType" SG_ 448 ACCM_PISaturation_St 0;
BA_ "GenSigSendType" SG_ 448 ACCM_PhaseCurrent_Val 0;
BA_ "GenSigSendType" SG_ 448 ACCM_OvPd_St 0;
BA_ "GenSigSendType" SG_ 448 ACCM_OverPower_St 0;
BA_ "GenSigSendType" SG_ 448 ACCM_Overload_St 0;
BA_ "GenSigSendType" SG_ 448 ACCM_OverIPMTemp_St 0;
BA_ "GenSigSendType" SG_ 448 ACCM_OverHV_St 0;
BA_ "GenSigSendType" SG_ 448 ACCM_OverDuty_St 0;
BA_ "GenSigSendType" SG_ 448 ACCM_LvUv_St 0;
BA_ "GenSigSendType" SG_ 448 ACCM_LvOv_St 0;
BA_ "GenSigSendType" SG_ 448 ACCM_LoseStep_St 0;
BA_ "GenSigSendType" SG_ 448 ACCM_LackPhase_St 0;
BA_ "GenSigSendType" SG_ 448 ACCM_IPMTemperature_Val 0;
BA_ "GenSigSendType" SG_ 448 ACCM_HVLoop_St 0;
BA_ "GenSigSendType" SG_ 448 ACCM_HardProtection_St 0;
BA_ "GenSigSendType" SG_ 448 ACCM_FreqLimitcode_Spec 0;
BA_ "GenSigSendType" SG_ 448 ACCM_DriveVoltageUV_St 0;
BA_ "GenSigSendType" SG_ 448 ACCM_DriveVoltageOV_St 0;
BA_ "GenSigSendType" SG_ 448 ACCM_DCCurrent_Val 0;
BA_ "GenSigSendType" SG_ 448 ACCM_CSE_Err 0;
BA_ "GenSigSendType" SG_ 448 ACCM_ControllerTemp_Val 0;
BA_ "GenSigSendType" SG_ 448 ACCM_Busoff_Err 0;
BA_ "GenSigSendType" SG_ 225 ERPB_OperationReminder_UI 0;
BA_ "GenSigSendType" SG_ 225 ERPB_EPBFunctionLamp_St 0;
BA_ "GenSigSendType" SG_ 225 ERPB_EPBFailLamp_St 0;
BA_ "GenSigSendType" SG_ 225 ERPB_EPB_St 0;
BA_ "GenSigSendType" SG_ 225 ERPB_CapacityLimitWarn_UI 0;
BA_ "GenSigSendType" SG_ 225 ERPB_BrakeLight_Req 0;
BA_ "GenSigSendType" SG_ 1476 ZCUF_VB1_NetworkReqCondition0 0;
BA_ "GenSigSendType" SG_ 1476 ZCUF_VB1_NetworkReqCondition1 0;
BA_ "GenSigSendType" SG_ 1476 ZCUF_VB1_NetworkReqCondition2 0;
BA_ "GenSigSendType" SG_ 1476 ZCUF_VB1_NetworkReqCondition3 0;
BA_ "GenSigSendType" SG_ 1476 ZCUF_VB1_NetworkReqCondition4 0;
BA_ "GenSigSendType" SG_ 1476 ZCUF_VB1_NetworkReqCondition5 0;
BA_ "GenSigSendType" SG_ 1476 ZCUF_VB1_NetworkReqCondition6 0;
BA_ "GenSigSendType" SG_ 1476 ZCUF_VB1_NetworkReqCondition7 0;
BA_ "GenSigSendType" SG_ 1476 ZCUF_VB1_NetworkReqCondition8 0;
BA_ "GenSigSendType" SG_ 1476 ZCUF_VB1_NetworkReqCondition9 0;
BA_ "GenSigSendType" SG_ 1476 ZCUF_VB1_NetworkReqCondition10 0;
BA_ "GenSigSendType" SG_ 1476 ZCUF_VB1_NetworkReqCondition11 0;
BA_ "GenSigSendType" SG_ 1476 ZCUF_VB1_NetworkReqCondition12 0;
BA_ "GenSigSendType" SG_ 1476 ZCUF_VB1_NetworkReqCondition13 0;
BA_ "GenSigSendType" SG_ 1476 ZCUF_VB1_NetworkReqCondition14 0;
BA_ "GenSigSendType" SG_ 1476 ZCUF_VB1_NetworkReqCondition15 0;
BA_ "GenSigSendType" SG_ 1476 ZCUF_VB1_NetworkReqCondition16 0;
BA_ "GenSigSendType" SG_ 1476 ZCUF_VB1_NetworkReqCondition17 0;
BA_ "GenSigSendType" SG_ 1476 ZCUF_VB1_NetworkReqCondition18 0;
BA_ "GenSigSendType" SG_ 1476 ZCUF_VB1_NetworkReqCondition19 0;
BA_ "GenSigSendType" SG_ 1476 ZCUF_VB1_NetworkReqCondition20 0;
BA_ "GenSigSendType" SG_ 1476 ZCUF_VB1_NetworkReqCondition21 0;
BA_ "GenSigSendType" SG_ 1476 ZCUF_VB1_NetworkReqCondition22 0;
BA_ "GenSigSendType" SG_ 1476 ZCUF_VB1_NetworkReqCondition23 0;
BA_ "GenSigSendType" SG_ 1476 ZCUF_VB1_NetworkReqCondition24 0;
BA_ "GenSigSendType" SG_ 1476 ZCUF_VB1_NetworkReqCondition25 0;
BA_ "GenSigSendType" SG_ 1476 ZCUF_VB1_NetworkReqCondition26 0;
BA_ "GenSigSendType" SG_ 1476 ZCUF_VB1_NetworkReqCondition27 0;
BA_ "GenSigSendType" SG_ 1476 ZCUF_VB1_NetworkReqCondition28 0;
BA_ "GenSigSendType" SG_ 1476 ZCUF_VB1_NetworkReqCondition29 0;
BA_ "GenSigSendType" SG_ 1476 ZCUF_VB1_NetworkReqCondition30 0;
BA_ "GenSigSendType" SG_ 1476 ZCUF_VB1_NetworkReqCondition31 0;
BA_ "GenSigSendType" SG_ 1412 ZCUF_WakeupReq_HDBT 2;
BA_ "GenSigSendType" SG_ 1412 ZCUF_WakeupReq_HDBI 2;
BA_ "GenSigSendType" SG_ 1412 ZCUF_WakeupReq_HDBA 2;
BA_ "GenSigSendType" SG_ 1412 ZCUF_WakeupReq_HDBM 2;
BA_ "GenSigSendType" SG_ 1412 ZCUF_WakeupReq_ZCUF 2;
BA_ "GenSigSendType" SG_ 1412 ZCUF_WakeupReq_ZCUL 2;
BA_ "GenSigSendType" SG_ 1412 ZCUF_WakeupReq_ZCUR 2;
BA_ "GenSigSendType" SG_ 1412 ZCUF_WakeupReq_ZCUT 2;
BA_ "GenSigSendType" SG_ 1104 ZCUF_NodeAddress_VB1 0;
BA_ "GenSigSendType" SG_ 1104 ZCUF_RepeatMsgReq_VB1 0;
BA_ "GenSigSendType" SG_ 1104 ZCUF_ActiveWakeup_VB1 0;
BA_ "GenSigSendType" SG_ 1104 ZCUF_PartialNetworkInfo_VB1 0;
BA_ "GenSigSendType" SG_ 1104 ZCUF_RepeatMsgSt_VB1 0;
BA_ "GenSigSendType" SG_ 1104 ZCUF_PN_HDBT_VB1 0;
BA_ "GenSigSendType" SG_ 1104 ZCUF_PN_HDBI_VB1 0;
BA_ "GenSigSendType" SG_ 1104 ZCUF_PN_HDBA_VB1 0;
BA_ "GenSigSendType" SG_ 1104 ZCUF_PN_HDBM_VB1 0;
BA_ "GenSigSendType" SG_ 1104 ZCUF_PN_ZCUF_VB1 0;
BA_ "GenSigSendType" SG_ 1104 ZCUF_PN_ZCUL_VB1 0;
BA_ "GenSigSendType" SG_ 1104 ZCUF_PN_ZCUR_VB1 0;
BA_ "GenSigSendType" SG_ 1104 ZCUF_PN_ZCUT_VB1 0;
BA_ "GenSigSendType" SG_ 562 AQS_NoxWert_Val 0;
BA_ "GenSigSendType" SG_ 562 AQS_NoxBereich_St 0;
BA_ "GenSigSendType" SG_ 562 AQS_Nox_St 0;
BA_ "GenSigSendType" SG_ 562 CHVH_InltTmp_Val 0;
BA_ "GenSigSendType" SG_ 562 CHVH_OutltTmp_Val 0;
BA_ "GenSigStartValue" SG_ 562 AQS_Luftguete_Val 14;
BA_ "GenSigSendType" SG_ 562 AQS_Luftguete_Val 0;
BA_ "GenSigStartValue" SG_ 562 TCM_FD_RT_1_AQSAvailable_St 1;
BA_ "GenSigSendType" SG_ 562 TCM_FD_RT_1_AQSAvailable_St 0;
BA_ "GenSigSendType" SG_ 562 CHVH_ActuPwr_Val 0;
BA_ "GenSigSendType" SG_ 562 CHVH_Fault_St 0;
BA_ "GenSigSendType" SG_ 514 TCM_V3WHeatActualPos_Val 0;
BA_ "GenSigStartValue" SG_ 514 TCM_ThermalCoolantTemp_Val 60;
BA_ "GenSigSendType" SG_ 514 TCM_ThermalCoolantTemp_Val 0;
BA_ "GenSigSendType" SG_ 514 TCM_OHXEXVRun_St 0;
BA_ "GenSigSendType" SG_ 514 TCM_OHXEXVPos_Val 0;
BA_ "GenSigSendType" SG_ 514 TCM_OHXEXVOverTempWarn_St 0;
BA_ "GenSigSendType" SG_ 514 TCM_OHXEXVInit_St 0;
BA_ "GenSigSendType" SG_ 514 TCM_OHXEXVFault_St 0;
BA_ "GenSigSendType" SG_ 514 TCM_OHXEXVCal_Req 0;
BA_ "GenSigSendType" SG_ 514 TCM_LINPowerHSD_St 0;
BA_ "GenSigSendType" SG_ 514 TCM_HPLowPressSOVFault_St 0;
BA_ "GenSigSendType" SG_ 514 TCM_HPLowPressSOV_St 0;
BA_ "GenSigSendType" SG_ 514 TCM_HPHighPressSOVFault_St 0;
BA_ "GenSigSendType" SG_ 514 TCM_HPHighPressSOV_St 0;
BA_ "GenSigSendType" SG_ 514 TCM_HPChillerTempValid_St 0;
BA_ "GenSigStartValue" SG_ 514 TCM_HPChillerTemp_Val 65535;
BA_ "GenSigSendType" SG_ 514 TCM_HPChillerTemp_Val 0;
BA_ "GenSigSendType" SG_ 514 TCM_HEXVRun_St 0;
BA_ "GenSigSendType" SG_ 514 TCM_HEXVPos_Val 0;
BA_ "GenSigSendType" SG_ 514 TCM_HEXVOverTempWarn_St 0;
BA_ "GenSigSendType" SG_ 514 TCM_HEXVInit_St 0;
BA_ "GenSigSendType" SG_ 514 TCM_HEXVFault_St 0;
BA_ "GenSigSendType" SG_ 514 TCM_HEXVCal_Req 0;
BA_ "GenSigSendType" SG_ 514 TCM_HeatPumpAcutalSpdPct_Val 0;
BA_ "GenSigSendType" SG_ 514 TCM_FHVACOutletTempValid_St 0;
BA_ "GenSigStartValue" SG_ 514 TCM_FHVACOutletTemp_Val 65535;
BA_ "GenSigSendType" SG_ 514 TCM_FHVACOutletTemp_Val 0;
BA_ "GenSigSendType" SG_ 514 TCM_CombChillerTempValid_St 0;
BA_ "GenSigStartValue" SG_ 514 TCM_CombChillerTemp_Val 65535;
BA_ "GenSigSendType" SG_ 514 TCM_CombChillerTemp_Val 0;
BA_ "GenSigSendType" SG_ 514 TCM_ChillerEXVRun_St 0;
BA_ "GenSigSendType" SG_ 514 TCM_ChillerEXVPos_Val 0;
BA_ "GenSigSendType" SG_ 514 TCM_ChillerEXVOverTempWarn_St 0;
BA_ "GenSigSendType" SG_ 514 TCM_ChillerEXVInit_St 0;
BA_ "GenSigSendType" SG_ 514 TCM_ChillerEXVFault_St 0;
BA_ "GenSigSendType" SG_ 514 TCM_ChillerEXVCal_Req 0;
BA_ "GenSigSendType" SG_ 514 TCM_ACSOVFault_St 0;
BA_ "GenSigSendType" SG_ 514 TCM_ACSOV_St 0;
BA_ "GenSigStartValue" SG_ 515 TCM_V5WV4wActualPosition_Val 3;
BA_ "GenSigSendType" SG_ 515 TCM_V5WV4wActualPosition_Val 0;
BA_ "GenSigSendType" SG_ 515 TCM_V5WV3wActualPosition_Val 0;
BA_ "GenSigSendType" SG_ 515 TCM_V5wMotor_St 0;
BA_ "GenSigSendType" SG_ 515 TCM_V5wFault_St 0;
BA_ "GenSigSendType" SG_ 515 TCM_V3wMotFault_St 0;
BA_ "GenSigSendType" SG_ 515 TCM_V3WHeatPMotor_St 0;
BA_ "GenSigSendType" SG_ 515 TCM_V3WHeatPCal_Req 0;
BA_ "GenSigSendType" SG_ 515 TCM_V3WHeatFault_St 0;
BA_ "GenSigSendType" SG_ 515 TCM_V3WHeatCal_St 0;
BA_ "GenSigSendType" SG_ 515 TCM_ThermalLiquidLackWarn_St 0;
BA_ "GenSigSendType" SG_ 515 TCM_RessPumpFault_St 0;
BA_ "GenSigStartValue" SG_ 515 TCM_PowerVoltage_Val 120;
BA_ "GenSigSendType" SG_ 515 TCM_PowerVoltage_Val 0;
BA_ "GenSigSendType" SG_ 515 TCM_PowerOffDelay_Req 0;
BA_ "GenSigSendType" SG_ 515 TCM_MotPumpFault_St 0;
BA_ "GenSigSendType" SG_ 515 TCM_HeatPumpFault_St 0;
BA_ "GenSigSendType" SG_ 515 TCM_HeatLiquidtLackWarn_St 0;
BA_ "GenSigStartValue" SG_ 164 EHBM_ABS_Err 1;
BA_ "GenSigSendType" SG_ 164 EHBM_ABS_Err 0;
BA_ "GenSigStartValue" SG_ 164 EHBM_EBD_Err 1;
BA_ "GenSigSendType" SG_ 164 EHBM_EBD_Err 0;
BA_ "GenSigSendType" SG_ 164 EHBM_BrakeLight_Req 0;
BA_ "GenSigSendType" SG_ 164 EHBM_ModeChgEnable_St 0;
BA_ "GenSigSendType" SG_ 164 EHBM_CST_Rsp 0;
BA_ "GenSigStartValue" SG_ 164 EHBM_ESC_Err 1;
BA_ "GenSigSendType" SG_ 164 EHBM_ESC_Err 0;
BA_ "GenSigSendType" SG_ 164 EHBM_EmergencyBrakeLight_Req 0;
BA_ "GenSigSendType" SG_ 164 EHBM_PataLamp_St 0;
BA_ "GenSigSendType" SG_ 164 EHBM_VehSpd_Val 0;
BA_ "GenSigSendType" SG_ 164 EHBM_VehSpdValid_St 0;
BA_ "GenSigStartValue" SG_ 164 EHBM_WorkMode_St 15;
BA_ "GenSigSendType" SG_ 164 EHBM_WorkMode_St 0;
BA_ "GenSigStartValue" SG_ 164 EHBM_InputRodStroke_Val 100;
BA_ "GenSigSendType" SG_ 164 EHBM_InputRodStroke_Val 0;
BA_ "GenSigSendType" SG_ 164 EHBM_InputRodStroke_St 0;
BA_ "GenSigSendType" SG_ 164 EHBM_BrakePedal_St 0;
BA_ "GenSigSendType" SG_ 164 EHBM_BrakeMode_St 0;
BA_ "GenSigSendType" SG_ 164 EHBM_BrakeModeEnable_St 0;
BA_ "GenSigSendType" SG_ 164 EHBM_VDCorTCSIntv_St 0;
BA_ "GenSigSendType" SG_ 164 EHBM_CtrllerFault_St 0;
BA_ "GenSigSendType" SG_ 164 EHBM_VDCIntv_St 0;
BA_ "GenSigSendType" SG_ 164 EHBM_ESCSys_Err 0;
BA_ "GenSigSendType" SG_ 164 EHBM_ESCFunSys_St 0;
BA_ "GenSigSendType" SG_ 164 EHBM_ABSIntv_St 0;
BA_ "GenSigSendType" SG_ 164 EHBM_EBDIntv_St 0;
BA_ "GenSigSendType" SG_ 164 EHBM_BrakeFluidLvl_St 0;
BA_ "GenSigSendType" SG_ 164 EHBM_Checksum3 7;
BA_ "GenSigSendType" SG_ 164 EHBM_RollingCounter3 7;
BA_ "GenSigSendType" SG_ 164 EHBM_HDCAvail_St 0;
BA_ "GenSigSendType" SG_ 164 EHBM_HDC_St 0;
BA_ "GenSigSendType" SG_ 164 EHBM_BoostDegrade_St 0;
BA_ "GenSigSendType" SG_ 164 EHBM_ESCSwAvail_St 0;
BA_ "GenSigSendType" SG_ 164 EHBM_ESClamp_St 0;
BA_ "GenSigSendType" SG_ 164 EHBM_TCSSwAvail_St 0;
BA_ "GenSigSendType" SG_ 164 EHBM_AVH_St 0;
BA_ "GenSigSendType" SG_ 164 EHBM_AVHAvail_St 0;
BA_ "GenSigSendType" SG_ 226 ERPB_BU_OperationReminder_UI 0;
BA_ "GenSigStartValue" SG_ 226 ERPB_BU_EPBHardSwitch_St 1;
BA_ "GenSigSendType" SG_ 226 ERPB_BU_EPBHardSwitch_St 0;
BA_ "GenSigSendType" SG_ 226 ERPB_BU_EPBFunctionLamp_St 0;
BA_ "GenSigSendType" SG_ 226 ERPB_BU_EPBFailLamp_St 0;
BA_ "GenSigSendType" SG_ 226 ERPB_BU_EPB_St 0;
BA_ "GenSigSendType" SG_ 226 ERPB_BU_CapacityLimitWarn_UI 0;
BA_ "GenSigSendType" SG_ 226 ERPB_BU_BrakeLight_Req 0;
BA_ "GenSigSendType" SG_ 160 ACU_YawRateValid_St 0;
BA_ "GenSigStartValue" SG_ 160 ACU_YawRate_Val 30000;
BA_ "GenSigSendType" SG_ 160 ACU_YawRate_Val 0;
BA_ "GenSigSendType" SG_ 160 ACU_LtrlAccelValid_St 0;
BA_ "GenSigStartValue" SG_ 160 ACU_LtrlAccel_Val 30000;
BA_ "GenSigSendType" SG_ 160 ACU_LtrlAccel_Val 0;
BA_ "GenSigStartValue" SG_ 160 ACU_LongAccel_Val 30000;
BA_ "GenSigSendType" SG_ 160 ACU_LongAccel_Val 0;
BA_ "GenSigStartValue" SG_ 160 ACU_AirbagWarnLamp_St 1;
BA_ "GenSigSendType" SG_ 160 ACU_AirbagWarnLamp_St 0;
BA_ "GenSigSendType" SG_ 160 ACU_DrvrSeatBelt_St 0;
BA_ "GenSigSendType" SG_ 160 ACU_DrvrSeatBeltValid_St 0;
BA_ "GenSigSendType" SG_ 176 EPS_WorkMode_St 0;
BA_ "GenSigStartValue" SG_ 176 EPS_System_Err 3;
BA_ "GenSigSendType" SG_ 176 EPS_System_Err 0;
BA_ "GenSigSendType" SG_ 176 EPS_ModeChangeEn_St 0;
BA_ "GenSigSendType" SG_ 800 HDBI_NFCAvailability_St 2;
BA_ "GenSigSendType" SG_ 1501 HDBI_VB1_NetworkReqCondition0 0;
BA_ "GenSigSendType" SG_ 1501 HDBI_VB1_NetworkReqCondition1 0;
BA_ "GenSigSendType" SG_ 1501 HDBI_VB1_NetworkReqCondition2 0;
BA_ "GenSigSendType" SG_ 1501 HDBI_VB1_NetworkReqCondition3 0;
BA_ "GenSigSendType" SG_ 1501 HDBI_VB1_NetworkReqCondition4 0;
BA_ "GenSigSendType" SG_ 1501 HDBI_VB1_NetworkReqCondition5 0;
BA_ "GenSigSendType" SG_ 1501 HDBI_VB1_NetworkReqCondition6 0;
BA_ "GenSigSendType" SG_ 1501 HDBI_VB1_NetworkReqCondition7 0;
BA_ "GenSigSendType" SG_ 1501 HDBI_VB1_NetworkReqCondition8 0;
BA_ "GenSigSendType" SG_ 1501 HDBI_VB1_NetworkReqCondition9 0;
BA_ "GenSigSendType" SG_ 1501 HDBI_VB1_NetworkReqCondition10 0;
BA_ "GenSigSendType" SG_ 1501 HDBI_VB1_NetworkReqCondition11 0;
BA_ "GenSigSendType" SG_ 1501 HDBI_VB1_NetworkReqCondition12 0;
BA_ "GenSigSendType" SG_ 1501 HDBI_VB1_NetworkReqCondition13 0;
BA_ "GenSigSendType" SG_ 1501 HDBI_VB1_NetworkReqCondition14 0;
BA_ "GenSigSendType" SG_ 1501 HDBI_VB1_NetworkReqCondition15 0;
BA_ "GenSigSendType" SG_ 1501 HDBI_VB1_NetworkReqCondition16 0;
BA_ "GenSigSendType" SG_ 1501 HDBI_VB1_NetworkReqCondition17 0;
BA_ "GenSigSendType" SG_ 1501 HDBI_VB1_NetworkReqCondition18 0;
BA_ "GenSigSendType" SG_ 1501 HDBI_VB1_NetworkReqCondition19 0;
BA_ "GenSigSendType" SG_ 1501 HDBI_VB1_NetworkReqCondition20 0;
BA_ "GenSigSendType" SG_ 1501 HDBI_VB1_NetworkReqCondition21 0;
BA_ "GenSigSendType" SG_ 1501 HDBI_VB1_NetworkReqCondition22 0;
BA_ "GenSigSendType" SG_ 1501 HDBI_VB1_NetworkReqCondition23 0;
BA_ "GenSigSendType" SG_ 1501 HDBI_VB1_NetworkReqCondition24 0;
BA_ "GenSigSendType" SG_ 1501 HDBI_VB1_NetworkReqCondition25 0;
BA_ "GenSigSendType" SG_ 1501 HDBI_VB1_NetworkReqCondition26 0;
BA_ "GenSigSendType" SG_ 1501 HDBI_VB1_NetworkReqCondition27 0;
BA_ "GenSigSendType" SG_ 1501 HDBI_VB1_NetworkReqCondition28 0;
BA_ "GenSigSendType" SG_ 1501 HDBI_VB1_NetworkReqCondition29 0;
BA_ "GenSigSendType" SG_ 1501 HDBI_VB1_NetworkReqCondition30 0;
BA_ "GenSigSendType" SG_ 1501 HDBI_VB1_NetworkReqCondition31 0;
BA_ "GenSigSendType" SG_ 1344 HDBI_WakeupReq_HDBI 2;
BA_ "GenSigSendType" SG_ 1344 HDBI_WakeupReq_HDBM 2;
BA_ "GenSigSendType" SG_ 1057 HDBI_NodeAddress_VB1 0;
BA_ "GenSigSendType" SG_ 1057 HDBI_RepeatMsgReq_VB1 0;
BA_ "GenSigSendType" SG_ 1057 HDBI_ActiveWakeup_VB1 0;
BA_ "GenSigSendType" SG_ 1057 HDBI_PartialNetworkInfo_VB1 0;
BA_ "GenSigSendType" SG_ 1057 HDBI_RepeatMsgSt_VB1 0;
BA_ "GenSigSendType" SG_ 1057 HDBI_PN_HDBT_VB1 0;
BA_ "GenSigSendType" SG_ 1057 HDBI_PN_HDBI_VB1 0;
BA_ "GenSigSendType" SG_ 1057 HDBI_PN_HDBA_VB1 0;
BA_ "GenSigSendType" SG_ 1057 HDBI_PN_HDBM_VB1 0;
BA_ "GenSigSendType" SG_ 1057 HDBI_PN_ZCUF_VB1 0;
BA_ "GenSigSendType" SG_ 1057 HDBI_PN_ZCUL_VB1 0;
BA_ "GenSigSendType" SG_ 1057 HDBI_PN_ZCUR_VB1 0;
BA_ "GenSigSendType" SG_ 1057 HDBI_PN_ZCUT_VB1 0;
VAL_ 656 ZCUR_FHVACBypassMotor_Err 0 "Not Faulted" 1 "Motor shorted" 2 "Motor Open" 3 "Motor_Stall" ;
VAL_ 656 ZCUR_FHVACDefrostMotor_Err 0 "Not Faulted" 1 "Motor shorted" 2 "Motor Open" 3 "Motor_Stall" ;
VAL_ 656 ZCUR_FHVACBLW_Err 0 "Not Faulted" 1 "Faulted" ;
VAL_ 656 ZCUR_FHVACModePos_Rsp 1023 "Invalid" ;
VAL_ 656 ZCUR_FHVACCyclePos_Rsp 1023 "Invalid" ;
VAL_ 656 ZCUR_FHVACBypassPos_Rsp 1023 "Invalid" ;
VAL_ 656 ZCUR_FHVACDefrostPos_Rsp 1023 "Invalid" ;
VAL_ 656 ZCUR_FHVACBLWPWM_Rsp 1023 "Invalid" ;
VAL_ 656 ZCUR_FHVACBLWRelay_St 0 "Close" 1 "Open" ;
VAL_ 656 ZCUR_FHVACLeftMixPos_Rsp 1023 "Invalid" ;
VAL_ 656 ZCUR_FHVACRigtMixPos_Rsp 1023 "Invalid" ;
VAL_ 656 ZCUR_FHVACLeftMixMotor_Err 0 "Not Faulted" 1 "Motor shorted" 2 "Motor Open" 3 "Motor_Stall" ;
VAL_ 656 ZCUR_FHVACModeMotor_Err 0 "Not Faulted" 1 "Motor shorted" 2 "Motor Open" 3 "Motor_Stall" ;
VAL_ 656 ZCUR_FHVACCycleMotor_Err 0 "Not Faulted" 1 "Motor shorted" 2 "Motor Open" 3 "Motor_Stall" ;
VAL_ 656 ZCUR_FHVACBLWRelay_Err 0 "Not Faulted" 1 "Faulted" ;
VAL_ 656 ZCUR_FHVACRigtMixMotor_Err 0 "Not Faulted" 1 "Motor shorted" 2 "Motor Open" 3 "Motor_Stall" ;
VAL_ 657 ZCUR_TDuctRVValid_St 0 "valid" 1 "Invalid" ;
VAL_ 657 ZCUR_TDuctLFValid_St 0 "valid" 1 "Invalid" ;
VAL_ 657 ZCUR_TDuctRFValid_St 0 "valid" 1 "Invalid" ;
VAL_ 657 ZCUR_ADSTws_Val 4095 "Invalid" ;
VAL_ 657 ZCUR_ION_St 0 "Default" 1 "Close" 2 "Open" 3 "Reserved" ;
VAL_ 657 ZCUR_ADSTrh_Val 4095 "Invalid" ;
VAL_ 657 ZCUR_ADShumidity_Val 4095 "Invalid" ;
VAL_ 657 ZCUR_TcabOrig_Val 4095 "Invalid" ;
VAL_ 657 ZCUR_TEvapOrig_Val 4095 "Invalid" ;
VAL_ 657 ZCUR_TDuctLV_Val 4095 "Invalid" ;
VAL_ 657 ZCUR_TDuctRV_Val 4095 "Invalid" ;
VAL_ 657 ZCUR_TDuctLF_Val 4095 "Invalid" ;
VAL_ 657 ZCUR_TDuctRF_Val 4095 "Invalid" ;
VAL_ 657 ZCUR_ADS_Valid_St 0 "valid" 1 "Invalid" ;
VAL_ 657 ZCUR_TcabOrigValid_St 0 "valid" 1 "Invalid" ;
VAL_ 657 ZCUR_TEvapOrigValid_St 0 "valid" 1 "Invalid" ;
VAL_ 657 ZCUR_TDuctLVValid_St 0 "valid" 1 "Invalid" ;
VAL_ 657 ZCUR_ION_Err 0 "Not Faulted" 1 "Faulted" ;
VAL_ 657 ZCUR_PM25Sensor_Err 0 "Not Faulted" 1 "Faulted" ;
VAL_ 657 ZCUR_CmpmtInAirPmAQI_St 0 "Level1" 1 "Level2" 2 "Level3" 3 "Level4" 4 "Level5" 5 "Level6" 6 "Reserved" 7 "Invalid" ;
VAL_ 912 ZCUR_RRHdl_Err 0 "normal" 1 "short to battery" 2 "short to ground" 3 "open load" 4 "reserved" 5 "reserved" 6 "reserved" 7 "reserved" ;
VAL_ 912 ZCUR_FRHdlWork_St 0 "stop" 1 "closing" 2 "opening" 3 "breaking freeze" ;
VAL_ 912 ZCUR_RRHdlWork_St 0 "stop" 1 "closing" 2 "opening" 3 "breaking freeze" ;
VAL_ 912 ZCUR_FRHdl_Err 0 "normal" 1 "short to battery" 2 "short to ground" 3 "open load" 4 "reserved" 5 "reserved" 6 "reserved" 7 "reserved" ;
VAL_ 912 ZCUR_FRSeatHtStpRsn_St 0 "Default" 1 "Stop Command" 2 "Open Circuit" 3 "Short Circuit" 4 "Reserved" 5 "Over Current" 6 "Drive Timeout" 7 "reserved" 8 "reserved" 9 "reserved" 10 "reserved" 11 "reserved" 12 "reserved" 13 "reserved" 14 "reserved" 15 "reserved" ;
VAL_ 912 ZCUR_FRSeatVtltStpRsn_St 0 "Default" 1 "Stop Command" 2 "Open Circuit" 3 "Short Circuit" 4 "Reserved" 5 "Over Current" 6 "Drive Timeout" 7 "reserved" 8 "reserved" 9 "reserved" 10 "reserved" 11 "reserved" 12 "reserved" 13 "reserved" 14 "reserved" 15 "reserved" ;
VAL_ 912 ZCUR_RExMirHtStpRsn_St 0 "Default" 1 "Stop Command" 2 "Open Circuit" 3 "Short Circuit" 4 "Reserved" 5 "Over Current" 6 "Drive Timeout" 7 "reserved" 8 "reserved" 9 "reserved" 10 "reserved" 11 "reserved" 12 "reserved" 13 "reserved" 14 "reserved" 15 "reserved" ;
VAL_ 1472 ZCUR_FRSeatHgtAdjLn_St 0 "Not Learnt" 1 "Learnt" ;
VAL_ 1472 ZCUR_FRSeatCshnAngAdjLn_St 0 "Not Learnt" 1 "Learnt" ;
VAL_ 1472 ZCUR_FRLegAngCshnExtLn_St 0 "Not Learnt" 1 "Learnt" ;
VAL_ 1472 ZCUR_FRWinStpRsn_St 0 "inactive" 1 "Command vanish" 2 "Stall" 3 "Time out" 4 "Motor Fault" 5 "anti-pinch" 6 "reserved" 7 "reserved" 8 "reserved" 9 "reserved" 10 "reserved" 11 "reserved" 12 "reserved" 13 "reserved" 14 "reserved" 15 "Invalid" ;
VAL_ 1472 ZCUR_RRWinStpRsn_St 0 "inactive" 1 "Command vanish" 2 "Stall" 3 "Time out" 4 "Motor Fault" 5 "anti-pinch" 6 "reserved" 7 "reserved" 8 "reserved" 9 "reserved" 10 "reserved" 11 "reserved" 12 "reserved" 13 "reserved" 14 "reserved" 15 "Invalid" ;
VAL_ 1472 ZCUR_FRWinStp_Req 0 "No Request" 1 "Over Heat" 2 "Reserved" 3 "Reserved" 4 "Reserved" 5 "Reserved" 6 "Reserved" 7 "Reserved" ;
VAL_ 1472 ZCUR_RRWinStp_Req 0 "No Request" 1 "Over Heat" 2 "Reserved" 3 "Reserved" 4 "Reserved" 5 "Reserved" 6 "Reserved" 7 "Reserved" ;
VAL_ 1472 ZCUR_FRHdlFrzLnTime_Val 255 "invalid" ;
VAL_ 1472 ZCUR_RRHdlFrzLnTime_Val 255 "invalid" ;
VAL_ 1472 ZCUR_FRSeatFBAdjLn_St 0 "Not Learnt" 1 "Learnt" ;
VAL_ 1472 ZCUR_FRSeatBackrestAdjLn_St 0 "Not Learnt" 1 "Learnt" ;
VAL_ 658 ZCUR_FRDrPdlLtWrk_St 0 "off" 1 "on" 2 "reserved" 3 "reserved" ;
VAL_ 658 ZCUR_RRDrPdlLtWrk_St 0 "off" 1 "on" 2 "reserved" 3 "reserved" ;
VAL_ 658 ZCUR_RLMirLtWrk_St 0 "off" 1 "on" 2 "reserved" 3 "reserved" ;
VAL_ 1106 ZCUR_RepeatMsgReq_VB1 0 "Repeat Message State not requested" 1 "Repeat Message State requested" ;
VAL_ 1106 ZCUR_ActiveWakeup_VB1 0 "passive Wakeup" 1 "active Wakeup" ;
VAL_ 1106 ZCUR_PartialNetworkInfo_VB1 0 "NM PDU contains no Partial Network request information" 1 "NM PDU contains Partial Network request information" ;
VAL_ 1106 ZCUR_RepeatMsgSt_VB1 0 "Not in Repeat Message State" 1 "In Repeat Message State" ;
VAL_ 1106 ZCUR_PN_HDBT_VB1 0 "No Request" 1 "Request" ;
VAL_ 1106 ZCUR_PN_HDBI_VB1 0 "No Request" 1 "Request" ;
VAL_ 1106 ZCUR_PN_HDBA_VB1 0 "No Request" 1 "Request" ;
VAL_ 1106 ZCUR_PN_HDBM_VB1 0 "No Request" 1 "Request" ;
VAL_ 1106 ZCUR_PN_ZCUF_VB1 0 "No Request" 1 "Request" ;
VAL_ 1106 ZCUR_PN_ZCUL_VB1 0 "No Request" 1 "Request" ;
VAL_ 1106 ZCUR_PN_ZCUR_VB1 0 "No Request" 1 "Request" ;
VAL_ 1106 ZCUR_PN_ZCUT_VB1 0 "No Request" 1 "Request" ;
VAL_ 431 ZCUR_FRSeatCshnAngPst_Val 126 "No Request" 127 "Invalid" ;
VAL_ 431 ZCUR_FRLegAngCshnExtPst_Val 126 "No Request" 127 "Invalid" ;
VAL_ 431 ZCUR_FRSeatFBPst_Val 126 "No Request" 127 "Invalid" ;
VAL_ 431 ZCUR_FRSeatBackrestPst_Val 126 "No Request" 127 "Invalid" ;
VAL_ 431 ZCUR_FRSeatHgtPst_Val 126 "No Request" 127 "Invalid" ;
VAL_ 431 ZCUR_RExMirUDPst_Val 126 "No Request" 127 "Invalid" ;
VAL_ 431 ZCUR_RExMirLRPst_Val 126 "No Request" 127 "Invalid" ;
VAL_ 112 ZCUL_HzrdWngSw_St 0 "No Press" 1 "Press" ;
VAL_ 112 ZCUL_SFLTnLt_St 0 "OFF" 1 "ON" ;
VAL_ 112 ZCUL_BrakeSwNC_St 0 "Open" 1 "Close" ;
VAL_ 112 ZCUL_FLSeatOcp_St 0 "Unoccupied" 1 "Occupied" 2 "Reserved" 3 "Invalid" ;
VAL_ 112 ZCUL_BrakeSwNO_St 0 "open" 1 "close" ;
VAL_ 400 ZCUL_FLSeatHgtAdj_Req 0 "No Request" 1 "Up" 2 "Down" 3 "Invalid" ;
VAL_ 400 ZCUL_FLLthPawl_St 0 "off" 1 "on" ;
VAL_ 400 ZCUL_FLSeatCshnAngAdj_Req 0 "No Request" 1 "Up" 2 "Down" 3 "Invalid" ;
VAL_ 400 ZCUL_RLLthPawl_St 0 "off" 1 "on" ;
VAL_ 400 ZCUL_FLHdlOprt_St 0 "inactive" 1 "active" 2 "reserved" 3 "Invalid" ;
VAL_ 400 ZCUL_RLHdlOprt_St 0 "inactive" 1 "active" 2 "reserved" 3 "Invalid" ;
VAL_ 400 ZCUL_FLDrIntSW_St 0 "not press" 1 "press" 2 "reserved" 3 "Invalid" ;
VAL_ 400 ZCUL_RLDrIntSW_St 0 "not press" 1 "press" 2 "reserved" 3 "Invalid" ;
VAL_ 400 ZCUL_FLLthAjar_St 0 "off" 1 "on" ;
VAL_ 400 ZCUL_RLLthAjar_St 0 "off" 1 "on" ;
VAL_ 400 ZCUL_FLSeatAdj_Req 0 "No Request" 1 "Front" 2 "Rear" 3 "Invalid" ;
VAL_ 400 ZCUL_FLLthHlfLck_St 0 "off" 1 "on" ;
VAL_ 400 ZCUL_FLSeatBackrestAdj_Req 0 "No Request" 1 "Front" 2 "Rear" 3 "Invalid" ;
VAL_ 400 ZCUL_RLLthHlfLck_St 0 "off" 1 "on" ;
VAL_ 400 ZCUL_FLSeatLegAngCshnExtAdj_Req 0 "No Request" 1 "Up" 2 "Down" 3 "Invalid" ;
VAL_ 400 ZCUL_SteerTiltPst_Val 254 "No Request" 255 "Invalid" ;
VAL_ 400 ZCUL_SteerTelePst_Val 254 "No Request" 255 "Invalid" ;
VAL_ 400 ZCUL_FLWinPst_Rsp 255 "Invalid" ;
VAL_ 400 ZCUL_RLWinPst_Rsp 255 "Invalid" ;
VAL_ 400 ZCUL_LExMirUDPst_Val 126 "No Request" 127 "Invalid" ;
VAL_ 400 ZCUL_LExMirLRPst_Val 126 "No Request" 127 "Invalid" ;
VAL_ 400 ZCUL_FLSeatFBPst_Val 126 "No Request" 127 "Invalid" ;
VAL_ 400 ZCUL_FLSeatBackrestPst_Val 126 "No Request" 127 "Invalid" ;
VAL_ 400 ZCUL_FLSeatHgtPst_Val 126 "No Request" 127 "Invalid" ;
VAL_ 400 ZCUL_FLSeatCshnAngPst_Val 126 "No Request" 127 "Invalid" ;
VAL_ 400 ZCUL_FLLegAngCshnExtPst_Val 126 "No Request" 127 "Invalid" ;
VAL_ 896 ZCUL_FLHdl_Err 0 "normal" 1 "short to battery" 2 "short to ground" 3 "open load" 4 "reserved" 5 "reserved" 6 "reserved" 7 "reserved" ;
VAL_ 896 ZCUL_FLHdlWork_St 0 "stop" 1 "closing" 2 "opening" 3 "breaking freeze" ;
VAL_ 896 ZCUL_RLHdlWork_St 0 "stop" 1 "closing" 2 "opening" 3 "breaking freeze" ;
VAL_ 896 ZCUL_RLHdl_Err 0 "normal" 1 "short to battery" 2 "short to ground" 3 "open load" 4 "reserved" 5 "reserved" 6 "reserved" 7 "reserved" ;
VAL_ 896 ZCUL_SteerTeleLn_St 0 "Not Learn" 1 "Learn" ;
VAL_ 896 ZCUL_SteerTiltLn_St 0 "Not Learn" 1 "Learn" ;
VAL_ 896 ZCUL_SteerHtStpRsn_St 0 "Default" 1 "Stop Command" 2 "Open Circuit" 3 "Short Circuit" 4 "Reserved" 5 "Over Current" 6 "Drive Timeout" 7 "reserved" 8 "reserved" 9 "reserved" 10 "reserved" 11 "reserved" 12 "reserved" 13 "reserved" 14 "reserved" 15 "reserved" ;
VAL_ 896 ZCUL_FLSeatHtStpRsn_St 0 "Default" 1 "Stop Command" 2 "Open Circuit" 3 "Short Circuit" 4 "Reserved" 5 "Over Current" 6 "Drive Timeout" 7 "reserved" 8 "reserved" 9 "reserved" 10 "reserved" 11 "reserved" 12 "reserved" 13 "reserved" 14 "reserved" 15 "reserved" ;
VAL_ 896 ZCUL_FLSeatVtltStpRsn_St 0 "Default" 1 "Stop Command" 2 "Open Circuit" 3 "Short Circuit" 4 "Reserved" 5 "Over Current" 6 "Drive Timeout" 7 "reserved" 8 "reserved" 9 "reserved" 10 "reserved" 11 "reserved" 12 "reserved" 13 "reserved" 14 "reserved" 15 "reserved" ;
VAL_ 896 ZCUL_LExMirHtStpRsn_St 0 "Default" 1 "Stop Command" 2 "Open Circuit" 3 "Short Circuit" 4 "Reserved" 5 "Over Current" 6 "Drive Timeout" 7 "reserved" 8 "reserved" 9 "reserved" 10 "reserved" 11 "reserved" 12 "reserved" 13 "reserved" 14 "reserved" 15 "reserved" ;
VAL_ 1408 ZCUL_FLHdlFrzLnTime_Val 255 "invalid" ;
VAL_ 1408 ZCUL_RLHdlFrzLnTime_Val 255 "invalid" ;
VAL_ 1408 ZCUL_FLSeatFBAdjLn_St 0 "Not Learnt" 1 "Learnt" ;
VAL_ 1408 ZCUL_FLSeatBackrestAdjLn_St 0 "Not Learnt" 1 "Learnt" ;
VAL_ 1408 ZCUL_FLSeatHgtAdjLn_St 0 "Not Learnt" 1 "Learnt" ;
VAL_ 1408 ZCUL_FLSeatCshnAngAdjLn_St 0 "Not Learnt" 1 "Learnt" ;
VAL_ 1408 ZCUL_FLLegAngCshnExtLn_St 0 "Not Learnt" 1 "Learnt" ;
VAL_ 1408 ZCUL_FLWinStpRsn_St 0 "inactive" 1 "Expected position" 2 "Stall" 3 "Time out" 4 "Motor Fault" 5 "Aanti-clamp" 6 "reserved" 7 "reserved" 8 "reserved" 9 "reserved" 10 "reserved" 11 "reserved" 12 "reserved" 13 "reserved" 14 "reserved" 15 "Invalid" ;
VAL_ 1408 ZCUL_RLWinStpRsn_St 0 "inactive" 1 "Expected position" 2 "Stall" 3 "Time out" 4 "Motor Fault" 5 "Aanti-clamp" 6 "reserved" 7 "reserved" 8 "reserved" 9 "reserved" 10 "reserved" 11 "reserved" 12 "reserved" 13 "reserved" 14 "reserved" 15 "Invalid" ;
VAL_ 1408 ZCUL_FLWinStp_Req 0 "No Request" 1 "Over Heat" 2 "Reserved" 3 "Reserved" 4 "Reserved" 5 "Reserved" 6 "Reserved" 7 "Reserved" ;
VAL_ 1408 ZCUL_RLWinStp_Req 0 "No Request" 1 "Over Heat" 2 "Reserved" 3 "Reserved" 4 "Reserved" 5 "Reserved" 6 "Reserved" 7 "Reserved" ;
VAL_ 672 ZCUL_FLDrPdlLtWrk_St 0 "off" 1 "on" 2 "reserved" 3 "reserved" ;
VAL_ 672 ZCUL_RLDrPdlLtWrk_St 0 "off" 1 "on" 2 "reserved" 3 "reserved" ;
VAL_ 672 ZCUL_BckLtWrk_St 0 "OFF" 1 "Lv1" 2 "Lv2" 3 "Lv3" 4 "Lv4" 5 "Lv5" 6 "Lv6" 7 "Lv7" 8 "Lv8" 9 "Lv9" 10 "Lv10" 11 "reserved" 12 "reserved" 13 "reserved" 14 "reserved" 15 "reserved" ;
VAL_ 672 ZCUL_EnSvLtWrk_St 0 "off" 1 "on" 2 "reserved" 3 "reserved" ;
VAL_ 673 ZCUL_RLWinSw_St 0 "No Request" 1 "Manual Up" 2 "Manual Down" 3 "Auto Up" 4 "Auto Down" 5 "Reserved" 6 "Reserved" 7 "Invalid" ;
VAL_ 673 ZCUL_FLWdwMov_St 0 "stop" 1 "closing" 2 "opening" 3 "invalid" ;
VAL_ 673 ZCUL_RLHdlFrz_St 0 "freeze not occur" 1 "freeze occur" ;
VAL_ 673 ZCUL_RLWdwMov_St 0 "stop" 1 "closing" 2 "opening" 3 "invalid" ;
VAL_ 673 ZCUL_FLLthHome_St 0 "off" 1 "on" ;
VAL_ 673 ZCUL_RLLthHome_St 0 "off" 1 "on" ;
VAL_ 673 ZCUL_FLDrLth_St 0 "unlatched" 1 "half latched" 2 "full latched" 3 "medium" 4 "reserved" 5 "reserved" 6 "reserved" 7 "reserved" ;
VAL_ 673 ZCUL_SFLTnLtErr_St 0 "No Error" 1 "Error" ;
VAL_ 673 ZCUL_FLHdlClsPstSW_St 0 "off" 1 "on" ;
VAL_ 673 ZCUL_RLDrLth_St 0 "unlatched" 1 "half latched" 2 "full latched" 3 "medium" 4 "reserved" 5 "reserved" 6 "reserved" 7 "reserved" ;
VAL_ 673 ZCUL_FLDrLthWrk_St 0 "stop" 1 "cinching" 2 "releasing" 3 "resuming after cinch" 4 "resuming after release" 5 "initialing" 6 "brake" 7 "reserved" ;
VAL_ 673 ZCUL_RLHdlClsPstSW_St 0 "off" 1 "on" ;
VAL_ 673 ZCUL_FLHdlStpRsn_St 0 "inactive" 1 "move to open position" 2 "pinch occuered" 3 "break freeze fail" 4 "handle fault" 5 "drive time out" 6 "heat protected" 7 "power status abnormal" 8 "command conflict" 9 "move to close position" 10 "reserved" 11 "reserved" 12 "reserved" 13 "reserved" 14 "reserved" 15 "reserved" ;
VAL_ 673 ZCUL_FLHdlOpnPstSW_St 0 "off" 1 "on" ;
VAL_ 673 ZCUL_RLDrLthWrk_St 0 "stop" 1 "cinching" 2 "releasing" 3 "resuming after cinch" 4 "resuming after release" 5 "initialing" 6 "brake" 7 "reserved" ;
VAL_ 673 ZCUL_RLHdlStpRsn_St 0 "inactive" 1 "move to open position" 2 "pinch occuered" 3 "break freeze fail" 4 "handle fault" 5 "drive time out" 6 "heat protected" 7 "power status abnormal" 8 "command conflict" 9 "move to close position" 10 "reserved" 11 "reserved" 12 "reserved" 13 "reserved" 14 "reserved" 15 "reserved" ;
VAL_ 673 ZCUL_FLDrStpRsn_St 0 "inactive" 1 "expected work end" 2 "latch fault" 3 "drive time out" 4 "heat protect" 5 "command conflict" 6 "stall occured" 7 "manual release" 8 "reserved" 9 "reserved" 10 "reserved" 11 "reserved" 12 "reserved" 13 "reserved" 14 "reserved" 15 "reserved" ;
VAL_ 673 ZCUL_RLHdlOpnPstSW_St 0 "off" 1 "on" ;
VAL_ 673 ZCUL_RLDrStpRsn_St 0 "inactive" 1 "expected work end" 2 "latch fault" 3 "drive time out" 4 "heat protect" 5 "command conflict" 6 "stall occured" 7 "manual release" 8 "reserved" 9 "reserved" 10 "reserved" 11 "reserved" 12 "reserved" 13 "reserved" 14 "reserved" 15 "reserved" ;
VAL_ 673 ZCUL_FLDrLth_Err 0 "normal" 1 "short to battery" 2 "short to ground" 3 "open load" 4 "reserved" 5 "reserved" 6 "reserved" 7 "reserved" ;
VAL_ 673 ZCUL_RLDrLth_Err 0 "normal" 1 "short to battery" 2 "short to ground" 3 "open load" 4 "reserved" 5 "reserved" 6 "reserved" 7 "reserved" ;
VAL_ 673 ZCUL_LExMirCtrl_Rsp 0 "unfold" 1 "fold" ;
VAL_ 673 ZCUL_HornSwitch_St 0 "No Press" 1 "Press" ;
VAL_ 673 ZCUL_FLHdlFrz_St 0 "freeze not occur" 1 "freeze occur" ;
VAL_ 673 ZCUL_FLDrStpRsn2_St 0 "inactive" 1 "expected work end" 2 "latch fault" 3 "drive time out" 4 "heat protect" 5 "command conflict" 6 "stall occured" 7 "manual release" 8 "reserved" 9 "reserved" 10 "reserved" 11 "reserved" 12 "reserved" 13 "reserved" 14 "reserved" 15 "reserved" ;
VAL_ 673 ZCUL_FLDrLthWrk2_St 0 "stop" 1 "cinching" 2 "releasing" 3 "resuming after cinch" 4 "resuming after release" 5 "initialing" 6 "brake" 7 "reserved" ;
VAL_ 673 ZCUL_RLDrStpRsn2_St 0 "inactive" 1 "expected work end" 2 "latch fault" 3 "drive time out" 4 "heat protect" 5 "command conflict" 6 "stall occured" 7 "manual release" 8 "reserved" 9 "reserved" 10 "reserved" 11 "reserved" 12 "reserved" 13 "reserved" 14 "reserved" 15 "reserved" ;
VAL_ 673 ZCUL_RLDrLthWrk2_St 0 "stop" 1 "cinching" 2 "releasing" 3 "resuming after cinch" 4 "resuming after release" 5 "initialing" 6 "brake" 7 "reserved" ;
VAL_ 673 ZCUL_FLLumbSuppUDAdj_Req 0 "No Request" 1 "Up" 2 "Down" 3 "Invalid" ;
VAL_ 673 ZCUL_FLSunshadeSW_St 0 "closed" 1 "opened" ;
VAL_ 673 ZCUL_FLLumbSuppFBAdj_Req 0 "No Request" 1 "Front" 2 "Back" 3 "Invalid" ;
VAL_ 673 ZCUL_FLDrLth2_Err 0 "normal" 1 "short to battery" 2 "short to ground" 3 "open load" 4 "reserved" 5 "reserved" 6 "reserved" 7 "reserved" ;
VAL_ 673 ZCUL_RLDrLth2_Err 0 "normal" 1 "short to battery" 2 "short to ground" 3 "open load" 4 "reserved" 5 "reserved" 6 "reserved" 7 "reserved" ;
VAL_ 673 ZCUL_SteerTiltMv_St 0 "Stop" 1 "Up" 2 "Down" 3 "Invalid" ;
VAL_ 673 ZCUL_SteerTeleMv_St 0 "Stop" 1 "Stretch" 2 "Shrink" 3 "Invalid" ;
VAL_ 673 ZCUL_SteerTiltStpRsn_St 0 "Default" 1 "Stop Command" 2 "Open Circuit" 3 "Short Circuit" 4 "Stall occurred" 5 "Over Current" 6 "Drive Timeout" 7 "Anti-pinch" 8 "Hall Fault" 9 "reserved" 10 "reserved" 11 "reserved" 12 "reserved" 13 "reserved" 14 "reserved" 15 "reserved" ;
VAL_ 673 ZCUL_SteerTiltStp_Req 0 "No Request" 1 "Heat Protect" 2 "Over Voltage" 3 "Under Voltage" 4 "Reserved" 5 "Reserved" 6 "Reserved" 7 "Reserved" ;
VAL_ 673 ZCUL_SteerTeleStpRsn_St 0 "Default" 1 "Stop Command" 2 "Open Circuit" 3 "Short Circuit" 4 "Stall occurred" 5 "Over Current" 6 "Drive Timeout" 7 "Anti-pinch" 8 "Hall Fault" 9 "reserved" 10 "reserved" 11 "reserved" 12 "reserved" 13 "reserved" 14 "reserved" 15 "reserved" ;
VAL_ 673 ZCUL_SteerTeleStp_Req 0 "No Request" 1 "Heat Protect" 2 "Over Voltage" 3 "Under Voltage" 4 "Reserved" 5 "Reserved" 6 "Reserved" 7 "Reserved" ;
VAL_ 673 ZCUL_LExMirUDMv_St 0 "Stop" 1 "Up" 2 "Down" 3 "Invalid" ;
VAL_ 673 ZCUL_LExMirLRMv_St 0 "Stop" 1 "Left" 2 "Right" 3 "Invalid" ;
VAL_ 673 ZCUL_LExMirUDStpRsn_St 0 "Default" 1 "Stop Command" 2 "Open Circuit" 3 "Short Circuit" 4 "Stall occurred" 5 "Over Current" 6 "Drive Timeout" 7 "reserved" 8 "reserved" 9 "reserved" 10 "reserved" 11 "reserved" 12 "reserved" 13 "reserved" 14 "reserved" 15 "reserved" ;
VAL_ 673 ZCUL_LExMirUDStp_Req 0 "No Request" 1 "Heat Protect" 2 "Over Voltage" 3 "Under Voltage" 4 "Reserved" 5 "Reserved" 6 "Reserved" 7 "Reserved" ;
VAL_ 673 ZCUL_LExMirLRStpRsn_St 0 "Default" 1 "Stop Command" 2 "Open Circuit" 3 "Short Circuit" 4 "Stall occurred" 5 "Over Current" 6 "Drive Timeout" 7 "reserved" 8 "reserved" 9 "reserved" 10 "reserved" 11 "reserved" 12 "reserved" 13 "reserved" 14 "reserved" 15 "reserved" ;
VAL_ 673 ZCUL_LExMirLRStp_Req 0 "No Request" 1 "Heat Protect" 2 "Over Voltage" 3 "Under Voltage" 4 "Reserved" 5 "Reserved" 6 "Reserved" 7 "Reserved" ;
VAL_ 673 ZCUL_FLSeatCshnAngStpRsn_St 0 "Default" 1 "Stop Command" 2 "Open Circuit" 3 "Short Circuit" 4 "Stall occurred" 5 "Over Current" 6 "Drive Timeout" 7 "Reserved" 8 "Hall Fault" 9 "reserved" 10 "reserved" 11 "reserved" 12 "reserved" 13 "reserved" 14 "reserved" 15 "reserved" ;
VAL_ 673 ZCUL_FLSeatCshnAngStp_Req 0 "No Request" 1 "Heat Protect" 2 "Over Voltage" 3 "Under Voltage" 4 "Reserved" 5 "Reserved" 6 "Reserved" 7 "Reserved" ;
VAL_ 673 ZCUL_FLLegAngCshnExtStpRsn_St 0 "Default" 1 "Stop Command" 2 "Open Circuit" 3 "Short Circuit" 4 "Stall occurred" 5 "Over Current" 6 "Drive Timeout" 7 "Reserved" 8 "Hall Fault" 9 "reserved" 10 "reserved" 11 "reserved" 12 "reserved" 13 "reserved" 14 "reserved" 15 "reserved" ;
VAL_ 673 ZCUL_FLLegAngCshnExtStp_Req 0 "No Request" 1 "Heat Protect" 2 "Over Voltage" 3 "Under Voltage" 4 "Reserved" 5 "Reserved" 6 "Reserved" 7 "Reserved" ;
VAL_ 673 ZCUL_FLSeatFBMv_St 0 "Stop" 1 "Front" 2 "Rear" 3 "Invalid" ;
VAL_ 673 ZCUL_FLSeatBackrestMv_St 0 "Stop" 1 "Front" 2 "Rear" 3 "Invalid" ;
VAL_ 673 ZCUL_FLSeatHgtMv_St 0 "Stop" 1 "Up" 2 "Down" 3 "Invalid" ;
VAL_ 673 ZCUL_FLSeatCshnAngMv_St 0 "Stop" 1 "Up" 2 "Down" 3 "Invalid" ;
VAL_ 673 ZCUL_FLLegAngCshnExtMv_St 0 "Stop" 1 "Up" 2 "Down" 3 "Invalid" ;
VAL_ 673 ZCUL_FLSeatFBStpRsn_St 0 "Default" 1 "Stop Command" 2 "Open Circuit" 3 "Short Circuit" 4 "Stall occurred" 5 "Over Current" 6 "Drive Timeout" 7 "Anti-pinch" 8 "Hall Fault" 9 "reserved" 10 "reserved" 11 "reserved" 12 "reserved" 13 "reserved" 14 "reserved" 15 "reserved" ;
VAL_ 673 ZCUL_FLSeatFBStp_Req 0 "No Request" 1 "Heat Protect" 2 "Over Voltage" 3 "Under Voltage" 4 "Reserved" 5 "Reserved" 6 "Reserved" 7 "Reserved" ;
VAL_ 673 ZCUL_FLSeatBackrestStpRsn_St 0 "Default" 1 "Stop Command" 2 "Open Circuit" 3 "Short Circuit" 4 "Stall occurred" 5 "Over Current" 6 "Drive Timeout" 7 "Reserved" 8 "Hall Fault" 9 "reserved" 10 "reserved" 11 "reserved" 12 "reserved" 13 "reserved" 14 "reserved" 15 "reserved" ;
VAL_ 673 ZCUL_FLSeatBackrestStp_Req 0 "No Request" 1 "Heat Protect" 2 "Over Voltage" 3 "Under Voltage" 4 "Reserved" 5 "Reserved" 6 "Reserved" 7 "Reserved" ;
VAL_ 673 ZCUL_FLSeatHgtStpRsn_St 0 "Default" 1 "Stop Command" 2 "Open Circuit" 3 "Short Circuit" 4 "Stall occurred" 5 "Over Current" 6 "Drive Timeout" 7 "Reserved" 8 "Hall Fault" 9 "reserved" 10 "reserved" 11 "reserved" 12 "reserved" 13 "reserved" 14 "reserved" 15 "reserved" ;
VAL_ 673 ZCUL_FLSeatHgtStp_Req 0 "No Request" 1 "Heat Protect" 2 "Over Voltage" 3 "Under Voltage" 4 "Reserved" 5 "Reserved" 6 "Reserved" 7 "Reserved" ;
VAL_ 673 ZCUL_FLHdlDbOprt_St 0 "not double operate" 1 "double operate" 2 "reserved" 3 "Invalid" ;
VAL_ 673 ZCUL_RLHdlDbOprt_St 0 "not double operate" 1 "double operate" 2 "reserved" 3 "Invalid" ;
VAL_ 673 ZCUL_LExMirCtrlMv_St 0 "Stop" 1 "Unfold" 2 "Fold" 3 "Reserved" ;
VAL_ 673 ZCUL_LExMirCtrlStpRsn_St 0 "Default" 1 "Stop Command" 2 "Open Circuit" 3 "Short Circuit" 4 "Stall occurred" 5 "Over Current" 6 "Drive Timeout" 7 "reserved" 8 "reserved" 9 "reserved" 10 "reserved" 11 "reserved" 12 "reserved" 13 "reserved" 14 "reserved" 15 "reserved" ;
VAL_ 673 ZCUL_LExMirCtrlStp_Req 0 "No Request" 1 "Heat Protect" 2 "Over Voltage" 3 "Under Voltage" 4 "Reserved" 5 "Reserved" 6 "Reserved" 7 "Reserved" ;
VAL_ 401 SWSR_TouchPadDownSw_St 0 "No Press" 1 "Press" ;
VAL_ 401 SWSR_TouchPadLeftSw_St 0 "No Press" 1 "Press" ;
VAL_ 401 SWSR_TouchPadRightSw_St 0 "No Press" 1 "Press" ;
VAL_ 401 SWSR_TouchPadUpSw_St 0 "No Press" 1 "Press" ;
VAL_ 401 DISFL_FRWinCtl_Req 0 "No Request" 1 "Manual Up" 2 "Manual Down" 3 "Auto Up" 4 "Auto Down" 5 "Reserved" 6 "Reserved" 7 "Invalid" ;
VAL_ 401 DISFL_RLWinCtl_Req 0 "No Request" 1 "Manual Up" 2 "Manual Down" 3 "Auto Up" 4 "Auto Down" 5 "Reserved" 6 "Reserved" 7 "Invalid" ;
VAL_ 401 DISFL_RRWinCtl_Req 0 "No Request" 1 "Manual Up" 2 "Manual Down" 3 "Auto Up" 4 "Auto Down" 5 "Reserved" 6 "Reserved" 7 "Invalid" ;
VAL_ 401 DISFL_DrvCtLckSW_Req 0 "No Request" 1 "Switch Pressed" 2 "Reservd" 3 "Invalid" ;
VAL_ 401 DISFL_FLWinCtl_Req 0 "No Request" 1 "Manual Up" 2 "Manual Down" 3 "Auto Up" 4 "Auto Down" 5 "Reserved" 6 "Reserved" 7 "Reserved" ;
VAL_ 401 TL_FLTpLtClr_St 0 "cold" 1 "warm" 2 "reserved" 3 "reserved" ;
VAL_ 401 TL_RLTpLtClr_St 0 "cold" 1 "warm" 2 "reserved" 3 "reserved" ;
VAL_ 401 TL_FRTpLtClr_St 0 "cold" 1 "warm" 2 "reserved" 3 "reserved" ;
VAL_ 401 TL_RRTpLtClr_St 0 "cold" 1 "warm" 2 "reserved" 3 "reserved" ;
VAL_ 401 TL_FLTchBtn_St 0 "off" 1 "on" ;
VAL_ 401 TL_FLTpLtBrt_Val 0 "OFF" 1 "Lv1" 2 "Lv2" 3 "Lv3" 4 "Lv4" 5 "Lv5" 6 "Lv6" 7 "Lv7" 8 "Lv8" 9 "Lv9" 10 "Lv10" 11 "reserved" 12 "reserved" 13 "reserved" 14 "reserved" 15 "reserved" ;
VAL_ 401 TL_RLTchBtn_St 0 "off" 1 "on" ;
VAL_ 401 TL_RLTpLtBrt_Val 0 "OFF" 1 "Lv1" 2 "Lv2" 3 "Lv3" 4 "Lv4" 5 "Lv5" 6 "Lv6" 7 "Lv7" 8 "Lv8" 9 "Lv9" 10 "Lv10" 11 "reserved" 12 "reserved" 13 "reserved" 14 "reserved" 15 "reserved" ;
VAL_ 401 TL_FRTchBtn_St 0 "off" 1 "on" ;
VAL_ 401 TL_FRTpLtBrt_Val 0 "OFF" 1 "Lv1" 2 "Lv2" 3 "Lv3" 4 "Lv4" 5 "Lv5" 6 "Lv6" 7 "Lv7" 8 "Lv8" 9 "Lv9" 10 "Lv10" 11 "reserved" 12 "reserved" 13 "reserved" 14 "reserved" 15 "reserved" ;
VAL_ 401 TL_RRTchBtn_St 0 "off" 1 "on" ;
VAL_ 401 TL_RRTpLtBrt_Val 0 "OFF" 1 "Lv1" 2 "Lv2" 3 "Lv3" 4 "Lv4" 5 "Lv5" 6 "Lv6" 7 "Lv7" 8 "Lv8" 9 "Lv9" 10 "Lv10" 11 "reserved" 12 "reserved" 13 "reserved" 14 "reserved" 15 "reserved" ;
VAL_ 401 ZCUL_FD_RT_1_SWSRAvailable_St 0 "Available" 1 "Not available" 2 "Reserved" 3 "Reserved" ;
VAL_ 401 ZCUL_FD_RT_1_DISFLAvailable_St 0 "Available" 1 "Not available" 2 "Reserved" 3 "Reserved" ;
VAL_ 401 ZCUL_FD_RT_1_TLAvailable_St 0 "Available" 1 "Not available" 2 "Reserved" 3 "Reserved" ;
VAL_ 403 CSM_FwiperSW_St 0 "OFF" 1 "Auto1" 2 "Auto2" 3 "LO" 4 "HI" 5 "Reserved" 6 "Reserved" 7 "Invalid" ;
VAL_ 403 CSM_TurnLightSw_St 0 "OFF" 1 "Left lane change" 2 "Left Turn" 3 "Right Lane change" 4 "Right Turn" 5 "Reserved" 6 "Reserved" 7 "Reserved" ;
VAL_ 403 CSM_FMistWashSW_St 0 "All Close" 1 "MIST Open" 2 "Front Wash Open" 3 "Reserved" ;
VAL_ 403 CSM_HighBeamSw_St 0 "Default Position" 1 "Push out" 2 "Push in" 3 "Reserved" ;
VAL_ 403 CSM_FWiperLO_Err 0 "Invalid" 1 "Short circuit to ground" 2 "Ground breaking" 3 "Reserved" ;
VAL_ 403 CSM_FWiperHI_Err 0 "Invalid" 1 "Short circuit to ground" 2 "Ground breaking" 3 "Reserved" ;
VAL_ 403 CSM_FMistSW_Err 0 "Invalid" 1 "Short circuit to ground" 2 "Ground breaking" 3 "Reserved" ;
VAL_ 403 CSM_FWashSW_Err 0 "Invalid" 1 "Short circuit to ground" 2 "Reserved" 3 "Reserved" ;
VAL_ 403 CSM_FWiperOFF_Err 0 "Invalid" 1 "Short circuit to ground" 2 "Ground breaking" 3 "Reserved" ;
VAL_ 403 CSM_FWiperAuto1_Err 0 "Invalid" 1 "Short circuit to ground" 2 "Ground breaking" 3 "Reserved" ;
VAL_ 403 CSM_FWiperAuto2_Err 0 "Invalid" 1 "Short circuit to ground" 2 "Ground breaking" 3 "Reserved" ;
VAL_ 1107 ZCUL_RepeatMsgReq_VB1 0 "Repeat Message State not requested" 1 "Repeat Message State requested" ;
VAL_ 1107 ZCUL_ActiveWakeup_VB1 0 "passive Wakeup" 1 "active Wakeup" ;
VAL_ 1107 ZCUL_PartialNetworkInfo_VB1 0 "NM PDU contains no Partial Network request information" 1 "NM PDU contains Partial Network request information" ;
VAL_ 1107 ZCUL_RepeatMsgSt_VB1 0 "Not in Repeat Message State" 1 "In Repeat Message State" ;
VAL_ 1107 ZCUL_PN_HDBT_VB1 0 "No Request" 1 "Request" ;
VAL_ 1107 ZCUL_PN_HDBI_VB1 0 "No Request" 1 "Request" ;
VAL_ 1107 ZCUL_PN_HDBA_VB1 0 "No Request" 1 "Request" ;
VAL_ 1107 ZCUL_PN_HDBM_VB1 0 "No Request" 1 "Request" ;
VAL_ 1107 ZCUL_PN_ZCUF_VB1 0 "No Request" 1 "Request" ;
VAL_ 1107 ZCUL_PN_ZCUL_VB1 0 "No Request" 1 "Request" ;
VAL_ 1107 ZCUL_PN_ZCUR_VB1 0 "No Request" 1 "Request" ;
VAL_ 1107 ZCUL_PN_ZCUT_VB1 0 "No Request" 1 "Request" ;
VAL_ 320 ZCUF_FWiperParkAreaSW_St 0 "Inactive(断开)" 1 "active（接通初始位置）" ;
VAL_ 528 ZCUF_EcfFlt_St 0 "正常" 1 "限功率运行" 2 "无法运行" ;
VAL_ 528 ZCUF_FLHighLgt_St 0 "OFF" 1 "ON" ;
VAL_ 528 ZCUF_FRHighLgt_St 0 "OFF" 1 "ON" ;
VAL_ 528 ZCUF_RESSInletTargTemp_Req 255 "Invalid" ;
VAL_ 528 ZCUF_Ready_St 0 "Not Ready" 1 "Ready" ;
VAL_ 528 ZCUF_PackThmlMode_Req 0 "None" 1 "Cooling ECO" 2 "Cooling Normal" 3 "Cooling Enhanced" 4 "Heating Normal" 5 "Reserved" 6 "Reserved" 7 "Reserved" ;
VAL_ 528 ZCUF_HighVoltage_St 0 "No" 1 "Yes" 2 "Reserved" 3 "Reserved" ;
VAL_ 528 ZCUF_AGSFaultSt_Err 0 "No Error" 1 "Error" ;
VAL_ 528 ZCUF_TractionModeSet_Rsp 0 "Inactive" 1 "Active" 2 "Reserved" 3 "Invalid" ;
VAL_ 528 ZCUF_FLTnLgtErr_St 0 "No Error" 1 "Error" ;
VAL_ 528 ZCUF_FRTnLgtErr_St 0 "No Error" 1 "Error" ;
VAL_ 528 ZCUF_CoolSysInletTemp_Val 255 "Invalid" ;
VAL_ 528 ZCUF_CoolSysOutletTemp_Val 255 "Invalid" ;
VAL_ 1424 ZCUF_AvgEnergyConsume_Val 4095 "Invalid" ;
VAL_ 513 ZCUF_AbnormalShiftInfo_Err 0 "Normal" 1 "R switch to D when vehicle is running" 2 "D switch to R when vehicle is running" 3 "Switching to P when vehicle is running" 4 "Switching out of P when brake pedal is not applied" 5 "EPB not locked, current gear is N" 6 "Shifting not allowed in current vehicle mode" 7 "Shifting to D/R is not allowed when vehicle is not in high voltage" 8 "reserved" 9 "reserved" 10 "reserved" 11 "reserved" 12 "reserved" 13 "reserved" 14 "reserved" 15 "reserved" ;
VAL_ 513 ZCUF_ThmlRunawayWarn_St 0 "inactive" 1 "active without speed（无车速）" 2 "acitve with speed（有车速）" ;
VAL_ 513 ZCUF_Shift_Err 0 "Normal" 1 "Error, can not shift" 2 "Error, can not shift to R/N/D" 3 "Error, can not shift to P" 4 "System error, no shifting is allowed" 5 "reserved" 6 "reserved" 7 "Invalid" ;
VAL_ 513 ZCUF_PullOver_St 0 "No Active" 1 "Active" ;
VAL_ 513 ZCUF_BrakeLightOn_Req 0 "No Request" 1 "Open Request" ;
VAL_ 513 ZCUF_HVOffConfirm_Req 0 "None" 1 "Request confirm" ;
VAL_ 513 ZCUF_PTFaultLgtClr_St 0 "No Light" 1 "Yellow, Tiny Fault" 2 "Red, Heavy Fault" 3 "Reserved" ;
VAL_ 513 ZCUF_AntiTheft_St 0 "Inactive" 1 "L2&L3 pass" 2 "L2&L3 Fail" 3 "L2 Pass，L3 Fail" 4 "L2 Fail，L3 Pass" 5 "Reserved" 6 "Reserved" 7 "Invalid" ;
VAL_ 513 ZCUF_LowVoltSys_Err 0 "Normal" 1 "Error" ;
VAL_ 513 ZCUF_MotorOverTemp_St 0 "inactive" 1 "active" ;
VAL_ 513 ZCUF_EDCDisTemp_Val 4095 "Invalid" ;
VAL_ 513 ZCUF_EDCSuncPres_Val 65535 "Invalid" ;
VAL_ 513 ZCUF_EDCSuncTemp_Val 4095 "Invalid" ;
VAL_ 513 ZCUF_EDCDisPres_Val 65535 "Invalid" ;
VAL_ 513 ZCUF_TAmbOrig_Val 4095 "Invalid" ;
VAL_ 513 ZCUF_EEMSetPowerLevel_St 0 "Level0" 1 "Level1" 2 "Level2" 3 "Level3" 4 "Level4" 5 "Level5" 6 "Reserved" 7 "Reserved" 8 "Reserved" 9 "Reserved" 10 "Reserved" 11 "Reserved" 12 "Reserved" 13 "Reserved" 14 "Reserved" 15 "Reserved" ;
VAL_ 880 ZCUF_ACMEnable_Req 0 "Disable" 1 "Enable" ;
VAL_ 880 ZCUF_FLLowLgt_St 0 "OFF" 1 "ON" ;
VAL_ 880 ZCUF_FRLowLgt_St 0 "OFF" 1 "ON" ;
VAL_ 880 ZCUF_HoodAjar_St 0 "off" 1 "on" ;
VAL_ 880 ZCUF_DriveConflictRemindInfo_UI 0 "Normal" 1 "Try to drive the car when charging connecor is connected" 2 "行车请挂如D/R档" 3 "Guardian" 4 "OTA升级中，禁止换挡" 5 "临时停车模式或宠物模式开启，禁止换挡" 6 "Reserved" 7 "Reserved" 8 "Reserved" 9 "Reserved" 10 "Reserved" 11 "Reserved" 12 "Reserved" 13 "Reserved" 14 "Reserved" 15 "Reserved" ;
VAL_ 880 ZCUF_FLPstnLgt_St 0 "OFF" 1 "ON" ;
VAL_ 880 ZCUF_FRPstnLgt_St 0 "OFF" 1 "ON" ;
VAL_ 880 ZCUF_PTworkmode_St 0 "Standard" 1 "Comfort" 2 "Sport" 3 "LowConsum" 4 "winter" 5 "one pedal" 6 "Reserved" 7 "Reserved" 8 "Reserved" 9 "Reserved" 10 "Reserved" 11 "Reserved" 12 "Reserved" 13 "Reserved" 14 "Reserved" 15 "Invalid" ;
VAL_ 880 ZCUF_PtModAvailable_St 0 "NotAvailable" 1 "Available" ;
VAL_ 880 ZCUF_RegenSetPct_Rsp 255 "Invalid" ;
VAL_ 880 ZCUF_Fwiper_St 0 "OFF" 1 "Low wipes" 2 "High wipes" 3 "Service" 4 "int1(预留)" 5 "in2（预留）" 6 "stop（预留)" 7 "Invalid" ;
VAL_ 880 ZCUF_ServiceReminder_St 0 "No Active" 1 "Active" ;
VAL_ 880 ZCUF_HoodHalfOrPawl_St 0 "off" 1 "on" ;
VAL_ 880 ZCUF_TractionModeAvail_St 0 "Not Available" 1 "Available" 2 "Reserved" 3 "Reserved" ;
VAL_ 880 ZCUF_TractionModeRemaind_St 0 "Normal" 1 "Power system error, traction mode remaind" 2 "Reserved" 3 "Invalid" ;
VAL_ 880 ZCUF_FLDyLgt_St 0 "OFF" 1 "ON" ;
VAL_ 880 ZCUF_FRDyLgt_St 0 "OFF" 1 "ON" ;
VAL_ 880 ZCUF_LowBattChrgForbid_St 0 "Permit" 1 "Forbid" ;
VAL_ 880 ZCUF_PTThmlLiquidLackWarn_St 0 "No Warning" 1 "Warning" 2 "Reserved" 3 "Reserved" ;
VAL_ 880 ZCUF_RegenAvail_St 0 "No Available" 1 "Available" ;
VAL_ 880 ZCUF_LowVoltSysWarnStop_St 0 "No active" 1 "active" ;
VAL_ 880 ZCUF_EmergencyLgtOn_Req 0 "No Request" 1 "Open Request" ;
VAL_ 880 ZCUF_HoodLatch_St 0 "Close" 1 "Open" 2 "Resvered" 3 "Invalid" ;
VAL_ 880 ZCUF_WashLqdHgtSW_St 0 "Inactive(液位低断开)" 1 "active(液位正常接通)" ;
VAL_ 97 EHBM_FLWhlPulseValid_St 0 "Invalid" 1 "Valid" ;
VAL_ 97 EHBM_FRWhlPulseValid_St 0 "Invalid" 1 "Valid" ;
VAL_ 97 EHBM_RLWhlPulseValid_St 0 "Invalid" 1 "Valid" ;
VAL_ 97 EHBM_RRWhlPulseValid_St 0 "Invalid" 1 "Valid" ;
VAL_ 97 ZCUF_FD_RT_1_EHBMAvailable_St 0 "Available" 1 "Not available" 2 "Reserved" 3 "Reserved" ;
VAL_ 448 ACCM_ZCUFMissing_St 0 "No Error" 1 "Error" ;
VAL_ 448 ACCM_UvP_St 0 "No Error" 1 "Error" ;
VAL_ 448 ACCM_UnderHV_St 0 "No Error" 1 "Error" ;
VAL_ 448 ACCM_TempSensorError 0 "No Error" 1 "Error" ;
VAL_ 448 ACCM_St 0 "Comp_Stop" 1 "Comp_ON" 2 "Comp_Speed_Limited_Operation" 3 "Stop_For_Protection_TF" 4 "Stop_For_Auto_Recovery_Protect" 5 "Stop_For_Freeze" 6 "NC" 7 "INIT" ;
VAL_ 448 ACCM_SIC_Err 0 "No Error" 1 "Error" ;
VAL_ 448 ACCM_PISaturation_St 0 "No Error" 1 "Error" ;
VAL_ 448 ACCM_OvPd_St 0 "No Error" 1 "Error" ;
VAL_ 448 ACCM_OverPower_St 0 "No Error" 1 "Error" ;
VAL_ 448 ACCM_Overload_St 0 "No Error" 1 "Error" ;
VAL_ 448 ACCM_OverIPMTemp_St 0 "No Error" 1 "Error" ;
VAL_ 448 ACCM_OverHV_St 0 "No Error" 1 "Error" ;
VAL_ 448 ACCM_OverDuty_St 0 "No Error" 1 "Error" ;
VAL_ 448 ACCM_LvUv_St 0 "No Error" 1 "Error" ;
VAL_ 448 ACCM_LvOv_St 0 "No Error" 1 "Error" ;
VAL_ 448 ACCM_LoseStep_St 0 "No Error" 1 "Error" ;
VAL_ 448 ACCM_LackPhase_St 0 "No Error" 1 "Error" ;
VAL_ 448 ACCM_HardProtection_St 0 "No Error" 1 "Error" ;
VAL_ 448 ACCM_DriveVoltageUV_St 0 "No Error" 1 "Error" ;
VAL_ 448 ACCM_DriveVoltageOV_St 0 "No Error" 1 "Error" ;
VAL_ 448 ACCM_CSE_Err 0 "No Error" 1 "Error" ;
VAL_ 448 ACCM_Busoff_Err 0 "No Error" 1 "Error" ;
VAL_ 225 ERPB_OperationReminder_UI 0 "OFF" 1 "Press the brake pedal first,then release the EBP button" 2 "Can't release due to charging gun is connected" 3 "Can't release due to camping mode" 4 "Manual release of EPB switch is not allowed under P gear" 5 "Automatically release EPB, please close the door, fasten the seat belt and adjust the sitting position" 6 "Roller Bench Mode" 7 "RESERVED" 8 "RESERVED" 9 "RESERVED" 10 "RESERVED" 11 "RESERVED" 12 "RESERVED" 13 "RESERVED" 14 "RESERVED" 15 "RESERVED" ;
VAL_ 225 ERPB_EPBFunctionLamp_St 0 "OFF" 1 "StaticOn" 2 "Flash" 3 "Reserved" ;
VAL_ 225 ERPB_EPBFailLamp_St 0 "OFF" 1 "StaticOn" 2 "Flash" 3 "Reserved" ;
VAL_ 225 ERPB_EPB_St 0 "Initial" 1 "Released(卡钳处于释放状态)" 2 "Closed(卡钳处于夹紧状态)" 3 "Locking(卡钳正处于夹紧过程中)" 4 "Releasing(卡钳正处于释放过程中)" 5 "UnKnow" 6 "Reserved" 7 "Invalid" ;
VAL_ 225 ERPB_CapacityLimitWarn_UI 0 "NO_TEXT_MESSAGE" 1 "GRADIENT_TOO_HIGH" 2 "CLAMPFORCE_NOT_ENOUGH" 3 "EPB FAILS" 4 "OPEN_PARK_BRAKE_BY_SWITCH" 5 "RESERVED" 6 "RESERVED" 7 "RESERVED" 8 "RESERVED" 9 "RESERVED" 10 "RESERVED" 11 "RESERVED" 12 "RESERVED" 13 "RESERVED" 14 "RESERVED" 15 "INVALID" ;
VAL_ 225 ERPB_BrakeLight_Req 0 "No request" 1 "Request" ;
VAL_ 1104 ZCUF_RepeatMsgReq_VB1 0 "Repeat Message State not requested" 1 "Repeat Message State requested" ;
VAL_ 1104 ZCUF_ActiveWakeup_VB1 0 "passive Wakeup" 1 "active Wakeup" ;
VAL_ 1104 ZCUF_PartialNetworkInfo_VB1 0 "NM PDU contains no Partial Network request information" 1 "NM PDU contains Partial Network request information" ;
VAL_ 1104 ZCUF_RepeatMsgSt_VB1 0 "Not in Repeat Message State" 1 "In Repeat Message State" ;
VAL_ 1104 ZCUF_PN_HDBT_VB1 0 "No Request" 1 "Request" ;
VAL_ 1104 ZCUF_PN_HDBI_VB1 0 "No Request" 1 "Request" ;
VAL_ 1104 ZCUF_PN_HDBA_VB1 0 "No Request" 1 "Request" ;
VAL_ 1104 ZCUF_PN_HDBM_VB1 0 "No Request" 1 "Request" ;
VAL_ 1104 ZCUF_PN_ZCUF_VB1 0 "No Request" 1 "Request" ;
VAL_ 1104 ZCUF_PN_ZCUL_VB1 0 "No Request" 1 "Request" ;
VAL_ 1104 ZCUF_PN_ZCUR_VB1 0 "No Request" 1 "Request" ;
VAL_ 1104 ZCUF_PN_ZCUT_VB1 0 "No Request" 1 "Request" ;
VAL_ 562 AQS_Nox_St 0 "nicht geschaltet" 1 "Luftguetestufe 1" 2 "Luftguetestufe 2" 3 "Luftguetestufe 3" 4 "Luftguetestufe 4" 5 "Luftguetestufe 5" 6 "Luftguetestufe 6" 7 "Luftguetestufe 7" 8 "Luftguetestufe 8" 9 "Luftguetestufe 9" 10 "Luftguetestufe 10" 11 "Reserved" 12 "Reserved" 13 "Reserved" 14 "Reserved" 15 "Luftguetestufe Error" ;
VAL_ 562 AQS_Luftguete_Val 0 "saubere Luft" 1 "Luftguete 10 %" 2 "Luftguete 20 %" 3 "Luftguete 30 %" 4 "Luftguete 40 %" 5 "Luftguete 50 %" 6 "Luftguete 60 %" 7 "Luftguete 70 %" 8 "Luftguete 80 %" 9 "Luftguete 90 %" 10 "Luft stark verschmutzt" 11 "Reserved" 12 "Reserved" 13 "Reserved" 14 "Init" 15 "Fehler" ;
VAL_ 562 TCM_FD_RT_1_AQSAvailable_St 0 "Available" 1 "Not available" 2 "Reserved" 3 "Reserved" ;
VAL_ 562 CHVH_Fault_St 0 "正常" 1 "限功率运行" 2 "无法运行" 3 "Reserved" ;
VAL_ 514 TCM_V3WHeatActualPos_Val 255 "Invalid" ;
VAL_ 514 TCM_ThermalCoolantTemp_Val 255 "Invalid" ;
VAL_ 514 TCM_OHXEXVRun_St 0 "Actuator is not moving" 1 "Actuator is moving" ;
VAL_ 514 TCM_OHXEXVOverTempWarn_St 0 "Ok" 1 "High Temperature Warning" 2 "Not defined" 3 "Not defined" ;
VAL_ 514 TCM_OHXEXVInit_St 0 "Not Initialized" 1 "Initialization in Process" 2 "Initialized" 3 "Invalid" ;
VAL_ 514 TCM_OHXEXVFault_St 0 "Actuator Not Faulted" 1 "Motor-Coil shorted" 2 "Motor-Coil open load" 3 "Over temperature shutdown" 4 "Lose Step(新增)" 5 "Motor_Stall" 6 "Overvoltage or undervoltage(新增)" 7 "Overload or OverCurrent(新增)" 8 "Not defined" 9 "Not defined" 10 "Not defined" 11 "Not defined" 12 "Not defined" 13 "Not defined" 14 "Not defined" 15 "Not defined" ;
VAL_ 514 TCM_OHXEXVCal_Req 0 "No Calibration Request" 1 "Calibration Required for Imporving Accuracy of Position" 2 "Calibration Required for Finding Reference  Position" ;
VAL_ 514 TCM_LINPowerHSD_St 0 "Default" 1 "Close" 2 "Open" 3 "Invalid" ;
VAL_ 514 TCM_HPLowPressSOVFault_St 0 "No Error" 1 "Error" ;
VAL_ 514 TCM_HPLowPressSOV_St 0 "Default" 1 "Colsed" 2 "Open" 3 "reserved" ;
VAL_ 514 TCM_HPHighPressSOVFault_St 0 "No Error" 1 "Error" ;
VAL_ 514 TCM_HPHighPressSOV_St 0 "Default" 1 "Colsed" 2 "Open" 3 "reserved" ;
VAL_ 514 TCM_HPChillerTempValid_St 0 "Invalid" 1 "validy" ;
VAL_ 514 TCM_HPChillerTemp_Val 65535 "Invalid" ;
VAL_ 514 TCM_HEXVRun_St 0 "Actuator is not moving" 1 "Actuator is moving" ;
VAL_ 514 TCM_HEXVOverTempWarn_St 0 "Ok" 1 "High Temperature Warning" 2 "Not defined" 3 "Not defined" ;
VAL_ 514 TCM_HEXVInit_St 0 "Not Initialized" 1 "Initialization in Process" 2 "Initialized" 3 "Invalid" ;
VAL_ 514 TCM_HEXVFault_St 0 "Actuator Not Faulted" 1 "Motor-Coil shorted" 2 "Motor-Coil open load" 3 "Over temperature shutdown" 4 "Lose Step(新增)" 5 "Motor_Stall" 6 "Overvoltage or undervoltage(新增)" 7 "Overload or OverCurrent(新增)" 8 "Not defined" 9 "Not defined" 10 "Not defined" 11 "Not defined" 12 "Not defined" 13 "Not defined" 14 "Not defined" 15 "Not defined" ;
VAL_ 514 TCM_HEXVCal_Req 0 "No Calibration Request" 1 "Calibration Required for Imporving Accuracy of Position" 2 "Calibration Required for Finding Reference  Position" ;
VAL_ 514 TCM_HeatPumpAcutalSpdPct_Val 255 "Invalid" ;
VAL_ 514 TCM_FHVACOutletTempValid_St 0 "Invalid" 1 "validy" ;
VAL_ 514 TCM_FHVACOutletTemp_Val 65535 "Invalid" ;
VAL_ 514 TCM_CombChillerTempValid_St 0 "Invalid" 1 "validy" ;
VAL_ 514 TCM_CombChillerTemp_Val 65535 "Invalid" ;
VAL_ 514 TCM_ChillerEXVRun_St 0 "Actuator is not moving" 1 "Actuator is moving" ;
VAL_ 514 TCM_ChillerEXVOverTempWarn_St 0 "Ok" 1 "High Temperature Warning" 2 "Not defined" 3 "Not defined" ;
VAL_ 514 TCM_ChillerEXVInit_St 0 "Not Initialized" 1 "Initialization in Process" 2 "Initialized" 3 "Invalid" ;
VAL_ 514 TCM_ChillerEXVFault_St 0 "Actuator Not Faulted" 1 "Motor-Coil shorted" 2 "Motor-Coil open load" 3 "Over temperature shutdown" 4 "Not defined" 5 "Motor_Stall" 6 "Not defined" 7 "Not defined" 8 "Not defined" 9 "Not defined" 10 "Not defined" 11 "Not defined" 12 "Not defined" 13 "Not defined" 14 "Not defined" 15 "Not defined" ;
VAL_ 514 TCM_ChillerEXVCal_Req 0 "No Calibration Request" 1 "Calibration Required for Imporving Accuracy of Position" 2 "Calibration Required for Finding Reference  Position" ;
VAL_ 514 TCM_ACSOVFault_St 0 "No Error" 1 "Error" ;
VAL_ 514 TCM_ACSOV_St 0 "Default" 1 "Colsed" 2 "Open" 3 "reserved" ;
VAL_ 515 TCM_V5WV4wActualPosition_Val 0 "EDS_RESS Loop Connection" 1 "EDS_RESS Loop Separation" 2 "Valve is going to the targeted Position" 3 "Unknown Position" ;
VAL_ 515 TCM_V5wMotor_St 0 "Motor Stop" 1 "Motor Running" ;
VAL_ 515 TCM_V5wFault_St 0 "No Error" 1 "Error" ;
VAL_ 515 TCM_V3wMotFault_St 0 "No Error" 1 "Error" ;
VAL_ 515 TCM_V3WHeatPMotor_St 0 "Motor Stop" 1 "Motor Running" ;
VAL_ 515 TCM_V3WHeatPCal_Req 0 "No Calibration Request" 1 "Calibration Required for Imporving Accuracy of Position" 2 "Calibration Required for Finding Reference  Position" ;
VAL_ 515 TCM_V3WHeatFault_St 0 "No Error" 1 "Error" ;
VAL_ 515 TCM_V3WHeatCal_St 0 "Calibration is inactive/Calibration Succeed" 1 "Calibration is active" 2 "Calibration is failure" ;
VAL_ 515 TCM_ThermalLiquidLackWarn_St 0 "No Fault" 1 "Fault" 2 "Reserved" 3 "Invalid" ;
VAL_ 515 TCM_RessPumpFault_St 0 "正常" 1 "限功率运行" 2 "无法运行" 3 "Reserved" ;
VAL_ 515 TCM_PowerOffDelay_Req 0 "Initial Value" 1 "PowerOffDelayRequest 请求延迟下电" 2 "NoRequest 无延迟下电请求" 3 "Invalid" ;
VAL_ 515 TCM_MotPumpFault_St 0 "正常" 1 "限功率运行" 2 "无法运行" 3 "Reserved" ;
VAL_ 515 TCM_HeatPumpFault_St 0 "正常" 1 "限功率运行" 2 "无法运行" 3 "Reserved" ;
VAL_ 515 TCM_HeatLiquidtLackWarn_St 0 "No Fault" 1 "Fault" 2 "Reserved" 3 "Invalid" ;
VAL_ 164 EHBM_ABS_Err 0 "Normal" 1 "Fault" ;
VAL_ 164 EHBM_EBD_Err 0 "Normal" 1 "Fault" ;
VAL_ 164 EHBM_BrakeLight_Req 0 "No Request" 1 "Request" ;
VAL_ 164 EHBM_ModeChgEnable_St 0 "Disable" 1 "Enable" ;
VAL_ 164 EHBM_CST_Rsp 0 "CST is disabled/Init/Default" 1 "CST is Standby" 2 "CST is Active" 3 "CST is Failure" ;
VAL_ 164 EHBM_ESC_Err 0 "Off" 1 "On" ;
VAL_ 164 EHBM_EmergencyBrakeLight_Req 0 "No Request" 1 "Request" ;
VAL_ 164 EHBM_PataLamp_St 0 "TCS Disable" 1 "TCS Enable" ;
VAL_ 164 EHBM_VehSpd_Val 8191 "Invalid" ;
VAL_ 164 EHBM_VehSpdValid_St 0 "Invalid" 1 "Valid" ;
VAL_ 164 EHBM_WorkMode_St 0 "Standard" 1 "Comfort" 2 "Sport" 3 "One Pedal" 4 "Winter" 5 "Soft sand" 6 "Offroad" 7 "Reserved" 8 "Reserved" 9 "Reserved" 10 "Reserved" 11 "Reserved" 12 "Reserved" 13 "Reserved" 14 "Reserved" 15 "Invalid" ;
VAL_ 164 EHBM_InputRodStroke_Val 1023 "Invalid" ;
VAL_ 164 EHBM_InputRodStroke_St 0 "Init" 1 "Normal" 2 "Fault" 3 "Reserved" ;
VAL_ 164 EHBM_BrakePedal_St 0 "Brake pedal not applied" 1 "Brake pedal applied" ;
VAL_ 164 EHBM_BrakeMode_St 0 "Light" 1 "Middle" 2 "Hard" 3 "Reserved" 7 "Invalid" ;
VAL_ 164 EHBM_BrakeModeEnable_St 0 "Disable" 1 "Enable" 2 "Reserved" 3 "Reserved" ;
VAL_ 164 EHBM_VDCorTCSIntv_St 0 "Not active" 1 "Active" ;
VAL_ 164 EHBM_CtrllerFault_St 0 "Normal" 1 "Fault" ;
VAL_ 164 EHBM_VDCIntv_St 0 "Not active" 1 "Active" ;
VAL_ 164 EHBM_ESCSys_Err 0 "Normal" 1 "Fault" ;
VAL_ 164 EHBM_ESCFunSys_St 0 "Init" 1 "Normal" 2 "Diagnose" 3 "Degreed Level 1" 4 "Degreed Level 2" ;
VAL_ 164 EHBM_ABSIntv_St 0 "Not active" 1 "Active" ;
VAL_ 164 EHBM_EBDIntv_St 0 "Not active" 1 "Active" ;
VAL_ 164 EHBM_BrakeFluidLvl_St 0 "BrakeFluid_Normal/Init/Default" 1 "BrakeFluid_Empty" 2 "BrakeFluid_Electric_Err" 3 "Reserved" ;
VAL_ 164 EHBM_HDCAvail_St 0 "Not available" 1 "Available" ;
VAL_ 164 EHBM_HDC_St 0 "OFF" 1 "On not active braking" 2 "On active braking" 3 "Reserved" ;
VAL_ 164 EHBM_BoostDegrade_St 0 "BBF_FullSys/Init/Default" 1 "BBF_DegradedPedalFeel" 2 "BBF_CircuitSperation" 3 "BBF_C1/2BoostOnly" 4 "HydBack w/ act / HydBack w/o act" 5 "Reserved" 6 "Reserved" 7 "Reserved" ;
VAL_ 164 EHBM_ESCSwAvail_St 0 "Not available" 1 "Available" ;
VAL_ 164 EHBM_ESClamp_St 0 "ESC Disable" 1 "ESC Enable" ;
VAL_ 164 EHBM_TCSSwAvail_St 0 "Not available" 1 "Available" ;
VAL_ 164 EHBM_AVH_St 0 "Off" 1 "Intervention" 2 "Standby" 3 "Reserved" ;
VAL_ 164 EHBM_AVHAvail_St 0 "Not available" 1 "Available" ;
VAL_ 226 ERPB_BU_OperationReminder_UI 0 "OFF" 1 "Press the brake pedal first,then release the EBP button" 2 "Can't release due to charging gun is connected" 3 "Can't release due to camping mode" 4 "Manual release of EPB switch is not allowed under P gear" 5 "Automatically release EPB, please close the door, fasten the seat belt and adjust the sitting position" 6 "Roller Bench Mode" 7 "RESERVED" 8 "RESERVED" 9 "RESERVED" 10 "RESERVED" 11 "RESERVED" 12 "RESERVED" 13 "RESERVED" 14 "RESERVED" 15 "RESERVED" ;
VAL_ 226 ERPB_BU_EPBHardSwitch_St 0 "Not active" 1 "Released" 2 "Applied" 3 "Reserved" ;
VAL_ 226 ERPB_BU_EPBFunctionLamp_St 0 "OFF" 1 "StaticOn" 2 "Flash" 3 "Reserved" ;
VAL_ 226 ERPB_BU_EPBFailLamp_St 0 "OFF" 1 "StaticOn" 2 "Flash" 3 "Reserved" ;
VAL_ 226 ERPB_BU_EPB_St 0 "Initial" 1 "Released(卡钳处于释放状态)" 2 "Closed(卡钳处于夹紧状态)" 3 "Locking(卡钳正处于夹紧过程中)" 4 "Releasing(卡钳正处于释放过程中)" 5 "UnKnow" 6 "Reserved" 7 "Invalid" ;
VAL_ 226 ERPB_BU_CapacityLimitWarn_UI 0 "NO_TEXT_MESSAGE" 1 "GRADIENT_TOO_HIGH" 2 "CLAMPFORCE_NOT_ENOUGH" 3 "EPB FAILS" 4 "OPEN_PARK_BRAKE_BY_SWITCH" 5 "RESERVED" 6 "RESERVED" 7 "RESERVED" 8 "RESERVED" 9 "RESERVED" 10 "RESERVED" 11 "RESERVED" 12 "RESERVED" 13 "RESERVED" 14 "RESERVED" 15 "INVALID" ;
VAL_ 226 ERPB_BU_BrakeLight_Req 0 "no request" 1 "request" ;
VAL_ 160 ACU_YawRateValid_St 0 "Invalid" 1 "Valid" ;
VAL_ 160 ACU_YawRate_Val 65535 "Invalid" ;
VAL_ 160 ACU_LtrlAccelValid_St 0 "Invalid" 1 "Valid" ;
VAL_ 160 ACU_LtrlAccel_Val 65535 "Invalid" ;
VAL_ 160 ACU_LongAccel_Val 65535 "Invalid" ;
VAL_ 160 ACU_AirbagWarnLamp_St 0 "Lamp Off" 1 "Lamp ON(default)" 2 "Flashing" 3 "Reserved" ;
VAL_ 160 ACU_DrvrSeatBelt_St 0 "Not Tied" 1 "Tied" ;
VAL_ 160 ACU_DrvrSeatBeltValid_St 0 "Invalid" 1 "Valid" ;
VAL_ 176 EPS_WorkMode_St 0 "Heavy" 1 "Mid" 2 "Light" 3 "Reserved" 4 "Reserved" 5 "Reserved" 6 "Reserved" 7 "Invalid" ;
VAL_ 176 EPS_System_Err 0 "EPS No Failure (Indicatio off)" 1 "Light Level Failure Indication (Yellow)" 2 "EPS Heavy Level Failure I ndication (Red)" 3 "Invalid" ;
VAL_ 176 EPS_ModeChangeEn_St 0 "Disable" 1 "Enable" ;
VAL_ 800 HDBI_NFCAvailability_St 0 "Invalid;" 1 "Valid;" 2 "Reserved;" 3 "Reserved;" ;
VAL_ 1057 HDBI_RepeatMsgReq_VB1 0 "Repeat Message State not requested" 1 "Repeat Message State requested" ;
VAL_ 1057 HDBI_ActiveWakeup_VB1 0 "passive Wakeup" 1 "active Wakeup" ;
VAL_ 1057 HDBI_PartialNetworkInfo_VB1 0 "NM PDU contains no Partial Network request information" 1 "NM PDU contains Partial Network request information" ;
VAL_ 1057 HDBI_RepeatMsgSt_VB1 0 "Not in Repeat Message State" 1 "In Repeat Message State" ;
VAL_ 1057 HDBI_PN_HDBT_VB1 0 "No Request" 1 "Request" ;
VAL_ 1057 HDBI_PN_HDBI_VB1 0 "No Request" 1 "Request" ;
VAL_ 1057 HDBI_PN_HDBA_VB1 0 "No Request" 1 "Request" ;
VAL_ 1057 HDBI_PN_HDBM_VB1 0 "No Request" 1 "Request" ;
VAL_ 1057 HDBI_PN_ZCUF_VB1 0 "No Request" 1 "Request" ;
VAL_ 1057 HDBI_PN_ZCUL_VB1 0 "No Request" 1 "Request" ;
VAL_ 1057 HDBI_PN_ZCUR_VB1 0 "No Request" 1 "Request" ;
VAL_ 1057 HDBI_PN_ZCUT_VB1 0 "No Request" 1 "Request" ;
